VERSION ""

NS_ :

BS_:

BU_: TM

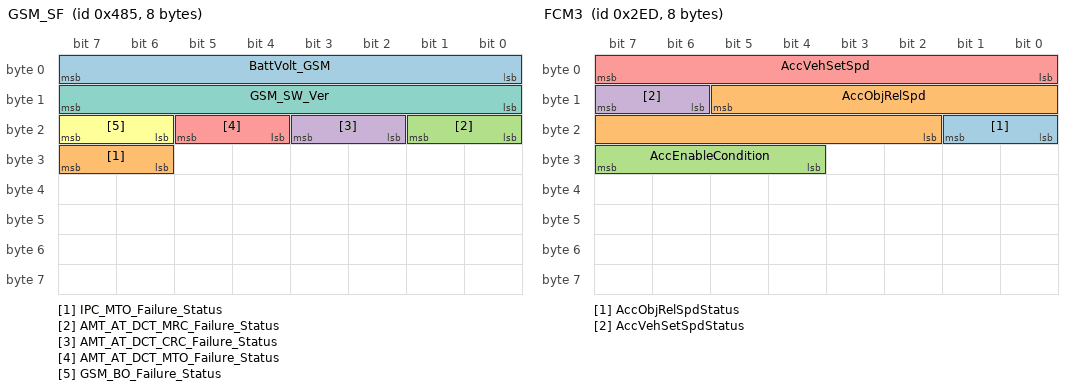
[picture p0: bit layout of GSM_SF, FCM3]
BO_ 1157 GSM_SF: 8 Vector__XXX
 SG_ BattVolt_GSM : 7|8@0+ (0.1,0) [0|25] ""  TM
 SG_ IPC_MTO_Failure_Status : 31|2@0+ (1,0) [0|3] ""  TM
 SG_ AMT_AT_DCT_MRC_Failure_Status : 17|2@0+ (1,0) [0|3] ""  TM
 SG_ AMT_AT_DCT_CRC_Failure_Status : 19|2@0+ (1,0) [0|3] ""  TM
 SG_ AMT_AT_DCT_MTO_Failure_Status : 21|2@0+ (1,0) [0|3] ""  TM
 SG_ GSM_BO_Failure_Status : 23|2@0+ (1,0) [0|3] ""  TM
 SG_ GSM_SW_Ver : 15|8@0+ (1,0) [0|255] ""  TM

BO_ 749 FCM3: 8 Vector__XXX
 SG_ AccObjRelSpdStatus : 17|2@0+ (1,0) [0|3] ""  TM
 SG_ AccObjRelSpd : 13|12@0+ (0.1,0) [0|409.5] ""  TM
 SG_ AccEnableCondition : 31|4@0+ (1,0) [0|15] ""  TM
 SG_ AccVehSetSpdStatus : 15|2@0+ (1,0) [0|3] ""  TM
 SG_ AccVehSetSpd : 7|8@0+ (1,0) [0|255] "kmph"  TM

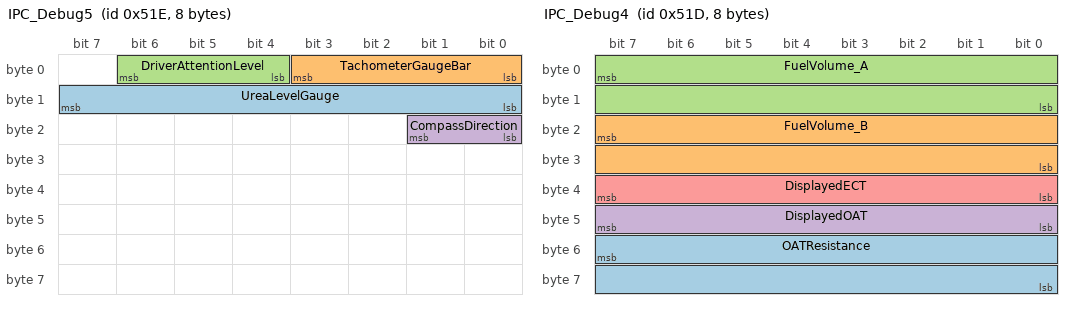
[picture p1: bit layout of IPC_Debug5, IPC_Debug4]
BO_ 1310 IPC_Debug5: 8 Vector__XXX
 SG_ UreaLevelGauge : 8|8@1+ (1,0) [0|100] "%"  TM
 SG_ TachometerGaugeBar : 3|4@0+ (1,0) [0|15] "NA"  TM
 SG_ DriverAttentionLevel : 6|3@0+ (1,0) [0|5] ""  TM
 SG_ CompassDirection : 17|2@0+ (1,0) [0|3] ""  TM

BO_ 1309 IPC_Debug4: 8 Vector__XXX
 SG_ OATResistance : 55|16@0+ (10,0) [0|655350] "Ohms"  TM
 SG_ FuelVolume_B : 23|16@0+ (0.1,0) [0|6553.5] "Litre"  TM
 SG_ FuelVolume_A : 7|16@0+ (0.1,0) [0|6553.5] "Litre"  TM
 SG_ DisplayedOAT : 47|8@0+ (1,0) [0|255] "C"  TM
 SG_ DisplayedECT : 39|8@0+ (1,0) [0|255] "C"  TM

BO_ 526 EMS_Event1: 8 Vector__XXX
 SG_ AccLkaSwitchState : 3|2@0+ (1,0) [0|3] ""  TM
 SG_ AdasSteeringSwitchState : 7|4@0+ (1,0) [0|15] ""  TM

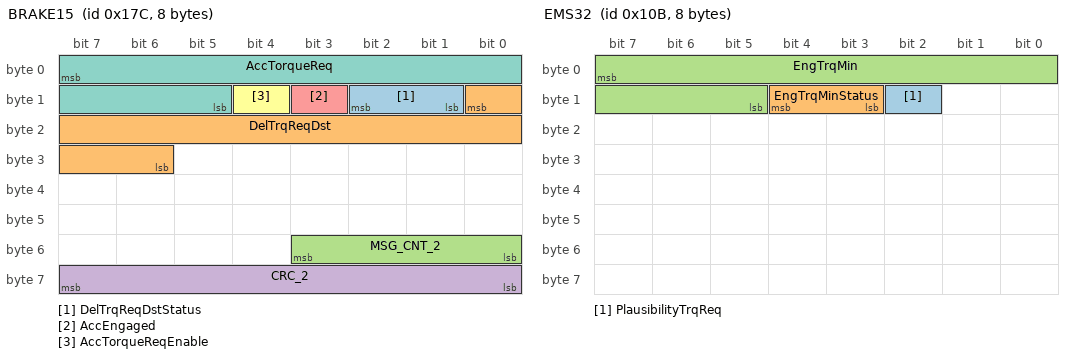
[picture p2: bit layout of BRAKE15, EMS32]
BO_ 380 BRAKE15: 8 Vector__XXX
 SG_ DelTrqReqDstStatus : 10|2@0+ (1,0) [0|3] ""  TM
 SG_ DelTrqReqDst : 8|11@0+ (0.01,-10) [-10|10] "Nm"  TM
 SG_ MSG_CNT_2 : 51|4@0+ (1,0) [0|15] ""  TM
 SG_ CRC_2 : 63|8@0+ (1,0) [0|255] ""  TM
 SG_ AccEngaged : 11|1@0+ (1,0) [0|1] ""  TM
 SG_ AccTorqueReqEnable : 12|1@0+ (1,0) [0|1] ""  TM
 SG_ AccTorqueReq : 7|11@0+ (1,-500) [-500|1546] "Nm"  TM

BO_ 267 EMS32: 8 Vector__XXX
 SG_ PlausibilityTrqReq : 10|1@0+ (1,0) [0|1] ""  TM
 SG_ EngTrqMinStatus : 12|2@0+ (1,0) [0|3] ""  TM
 SG_ EngTrqMin : 7|11@0+ (1,-500) [-500|1546] "Nm"  TM

BO_ 864 BCM4_RC: 8 Vector__XXX
 SG_ BcmPotPowerTailgateState : 25|2@0+ (1,0) [0|3] ""  TM
 SG_ PotHeightAdjState : 28|3@0+ (1,0) [0|7] ""  TM
 SG_ PotSwRkeOnOffState : 30|1@0+ (1,0) [0|1] ""  TM
 SG_ PotGestOnOffState : 29|1@0+ (1,0) [0|1] ""  TM
 SG_ PotBuzzOnOffState : 31|1@0+ (1,0) [0|1] ""  TM
 SG_ PotFuncState : 16|1@0+ (1,0) [0|1] ""  TM
 SG_ BCmHuSunShadeStateStatus : 18|2@0+ (1,0) [0|3] ""  TM
 SG_ BCmHuSunShadeState : 21|3@0+ (1,0) [0|7] ""  TM
 SG_ BCmHuSunRoofStateStatus : 23|2@0+ (1,0) [0|3] ""  TM
 SG_ BCmHuSunRoofState : 10|3@0+ (1,0) [0|7] ""  TM
 SG_ BCmHuGotoEntryExitPosState : 11|1@0+ (1,0) [0|1] ""  TM
 SG_ DrvMemSeatFunState : 12|1@0+ (1,0) [0|1] ""  TM
 SG_ MemRecallCancelSeat : 13|1@0+ (1,0) [0|1] ""  TM
 SG_ MemoryPosStoreReqStatus : 4|2@0+ (1,0) [0|3] ""  TM
 SG_ MemoryPosStoreReq : 2|3@0+ (1,0) [0|7] ""  TM
 SG_ MemoryPosLoadReqStatus : 15|2@0+ (1,0) [0|3] ""  TM
 SG_ MemoryPosLoadReq : 7|3@0+ (1,0) [0|7] ""  TM

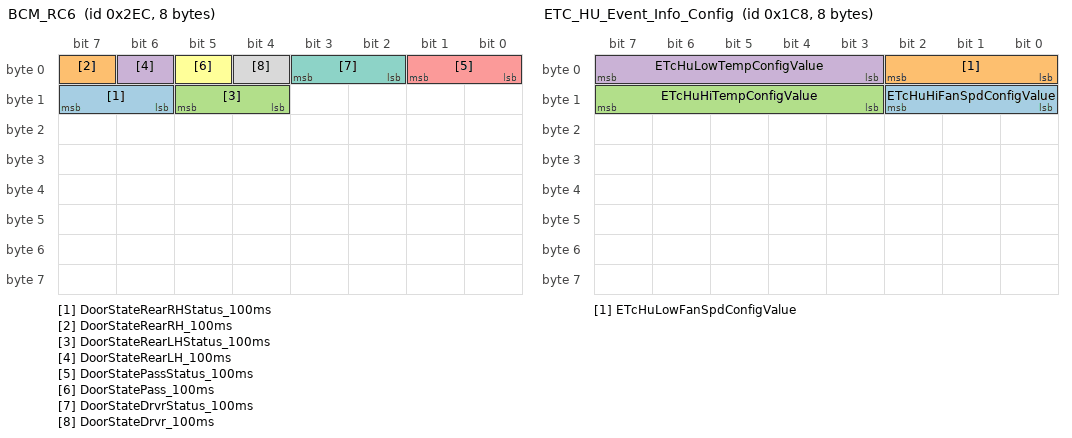
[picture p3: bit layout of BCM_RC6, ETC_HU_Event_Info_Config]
BO_ 748 BCM_RC6: 8 Vector__XXX
 SG_ DoorStateRearRHStatus_100ms : 15|2@0+ (1,0) [0|3] ""  TM
 SG_ DoorStateRearRH_100ms : 7|1@0+ (1,0) [0|1] ""  TM
 SG_ DoorStateRearLHStatus_100ms : 13|2@0+ (1,0) [0|3] ""  TM
 SG_ DoorStateRearLH_100ms : 6|1@0+ (1,0) [0|1] ""  TM
 SG_ DoorStatePassStatus_100ms : 1|2@0+ (1,0) [0|3] ""  TM
 SG_ DoorStatePass_100ms : 5|1@0+ (1,0) [0|1] ""  TM
 SG_ DoorStateDrvrStatus_100ms : 3|2@0+ (1,0) [0|3] ""  TM
 SG_ DoorStateDrvr_100ms : 4|1@0+ (1,0) [0|1] ""  TM

BO_ 456 ETC_HU_Event_Info_Config: 8 Vector__XXX
 SG_ ETcHuHiFanSpdConfigValue : 10|3@0+ (1,0) [0|7] ""  TM
 SG_ ETcHuLowFanSpdConfigValue : 2|3@0+ (1,0) [0|7] ""  TM
 SG_ ETcHuHiTempConfigValue : 15|5@0+ (1,0) [0|31] ""  TM
 SG_ ETcHuLowTempConfigValue : 7|5@0+ (1,0) [0|31] ""  TM

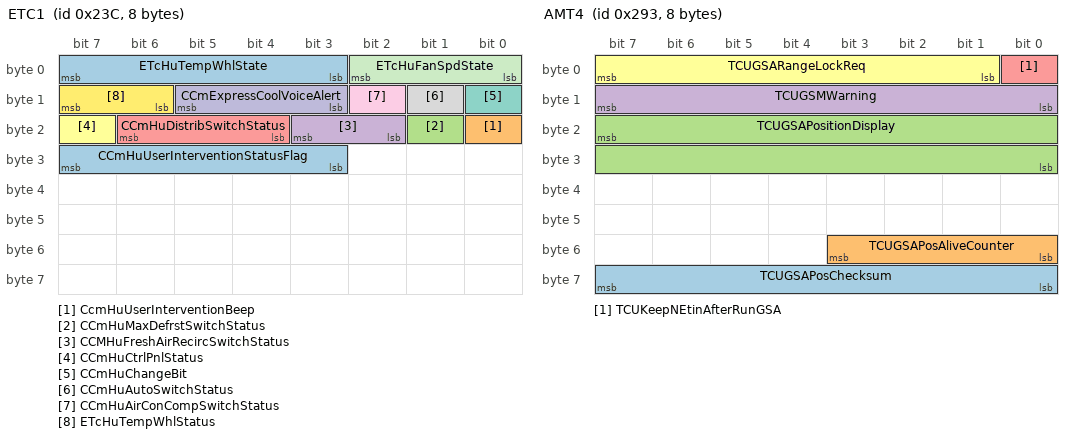
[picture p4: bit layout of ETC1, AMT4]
BO_ 572 ETC1: 8 Vector__XXX
 SG_ CCmHuUserInterventionStatusFlag : 31|5@0+ (1,0) [0|31] ""  TM
 SG_ CcmHuUserInterventionBeep : 16|1@0+ (1,0) [0|1] ""  TM
 SG_ CCmHuMaxDefrstSwitchStatus : 17|1@0+ (1,0) [0|1] ""  TM
 SG_ CCMHuFreshAirRecircSwitchStatus : 19|2@0+ (1,0) [0|3] ""  TM
 SG_ CCmHuDistribSwitchStatus : 22|3@0+ (1,0) [0|7] ""  TM
 SG_ CCmHuCtrlPnlStatus : 23|1@0+ (1,0) [0|1] ""  TM
 SG_ CCmHuChangeBit : 8|1@0+ (1,0) [0|1] ""  TM
 SG_ CCmHuAutoSwitchStatus : 9|1@0+ (1,0) [0|1] ""  TM
 SG_ CCmHuAirConCompSwitchStatus : 10|1@0+ (1,0) [0|1] ""  TM
 SG_ CCmExpressCoolVoiceAlert : 13|3@0+ (1,0) [0|7] ""  TM
 SG_ ETcHuFanSpdState : 2|3@0+ (1,0) [0|7] ""  TM
 SG_ ETcHuTempWhlStatus : 15|2@0+ (1,0) [0|3] ""  TM
 SG_ ETcHuTempWhlState : 7|5@0+ (1,0) [0|31] ""  TM

BO_ 1292 ESCL_NMPDU: 8 Vector__XXX
 SG_ ESCL_NMPDU_USER_DATA_D4 : 55|8@0+ (1,0) [0|255] ""  TM
 SG_ ESCL_NMPDU_USER_DATA_D3 : 47|8@0+ (1,0) [0|255] ""  TM
 SG_ ESCL_NMPDU_USER_DATA_D2 : 39|8@0+ (1,0) [0|255] ""  TM
 SG_ ESCL_NMPDU_USER_DATA_D1 : 31|8@0+ (1,0) [0|255] ""  TM
 SG_ ESCL_NMPDU_SRC_ECU_ID : 7|8@0+ (1,0) [0|255] ""  TM
 SG_ CurrentState_ESCL : 16|1@0+ (1,0) [0|1] ""  TM
 SG_ ActiveWakeUp_ESCL : 12|1@0+ (1,0) [0|1] ""  TM
 SG_ Reserved79 : 20|1@0+ (1,0) [0|1] ""  TM
 SG_ Reserved78 : 21|1@0+ (1,0) [0|1] ""  TM
 SG_ Reserved77 : 22|1@0+ (1,0) [0|1] ""  TM
 SG_ Reserved76 : 23|1@0+ (1,0) [0|1] ""  TM
 SG_ Reserved75 : 9|1@0+ (1,0) [0|1] ""  TM
 SG_ Reserved74 : 10|1@0+ (1,0) [0|1] ""  TM
 SG_ Reserved73 : 13|1@0+ (1,0) [0|1] ""  TM
 SG_ Reserved72 : 15|1@0+ (1,0) [0|1] ""  TM
 SG_ RepeatMessageReq_ESCL : 8|1@0+ (1,0) [0|1] ""  TM
 SG_ PreviousState_ESCL : 19|3@0+ (1,0) [0|7] ""  TM
 SG_ PartialNetworkInformation_ESCL : 14|1@0+ (1,0) [0|1] ""  TM
 SG_ NMCoOrdSlpReady_ESCL : 11|1@0+ (1,0) [0|1] ""  TM
 SG_ ESCL_NMPDU_USER_DATA_D5 : 63|8@0+ (1,0) [0|255] ""  TM

BO_ 437 DctPepsAuthReq: 8 Vector__XXX
 SG_ DctPepsAuthReq : 7|64@0+ (1,0) [0|0] ""  TM

BO_ 659 AMT4: 8 Vector__XXX
 SG_ TCUGSAPosChecksum : 63|8@0+ (1,0) [0|255] ""  TM
 SG_ TCUGSAPosAliveCounter : 51|4@0+ (1,0) [0|15] ""  TM
 SG_ TCUGSAPositionDisplay : 23|16@0+ (1,0) [0|65535] ""  TM
 SG_ TCUGSMWarning : 15|8@0+ (1,0) [0|255] ""  TM
 SG_ TCUKeepNEtinAfterRunGSA : 0|1@0+ (1,0) [0|1] ""  TM
 SG_ TCUGSARangeLockReq : 7|7@0+ (1,0) [0|127] ""  TM

BO_ 1610 SRR_DiagResponse_UUDT: 8 Vector__XXX
 SG_ SRR_DiagResponse_UUDT : 7|64@0+ (1,0) [0|0] ""  TM

BO_ 1866 SRR_DiagResponse_USDT: 8 Vector__XXX
 SG_ SRR_DiagResponse_USDT : 7|64@0+ (1,0) [0|0] ""  TM

BO_ 1858 SRR_DiagRequest: 8 Vector__XXX
 SG_ SRR_DiagRequest : 7|64@0+ (1,0) [0|0] ""  TM

BO_ 1608 FR_DiagResponse_UUDT: 8 Vector__XXX
 SG_ FR_DiagResponse_UUDT : 7|64@0+ (1,0) [0|0] ""  TM

BO_ 1864 FR_DiagResponse_USDT: 8 Vector__XXX
 SG_ FR_DiagResponse_USDT : 7|64@0+ (1,0) [0|0] ""  TM

BO_ 1856 FR_DiagRequest: 8 Vector__XXX
 SG_ FR_DiagRequest : 7|64@0+ (1,0) [0|0] ""  TM

BO_ 1609 FCM_DiagResponse_UUDT: 8 Vector__XXX
 SG_ FCM_DiagResponse_UUDT : 7|64@0+ (1,0) [0|0] ""  TM

BO_ 1865 FCM_DiagResponse_USDT: 8 Vector__XXX
 SG_ FCM_DiagResponse_USDT : 7|64@0+ (1,0) [0|0] ""  TM

BO_ 1857 FCM_DiagRequest: 8 Vector__XXX
 SG_ FCM_DiagRequest : 7|64@0+ (1,0) [0|0] ""  TM

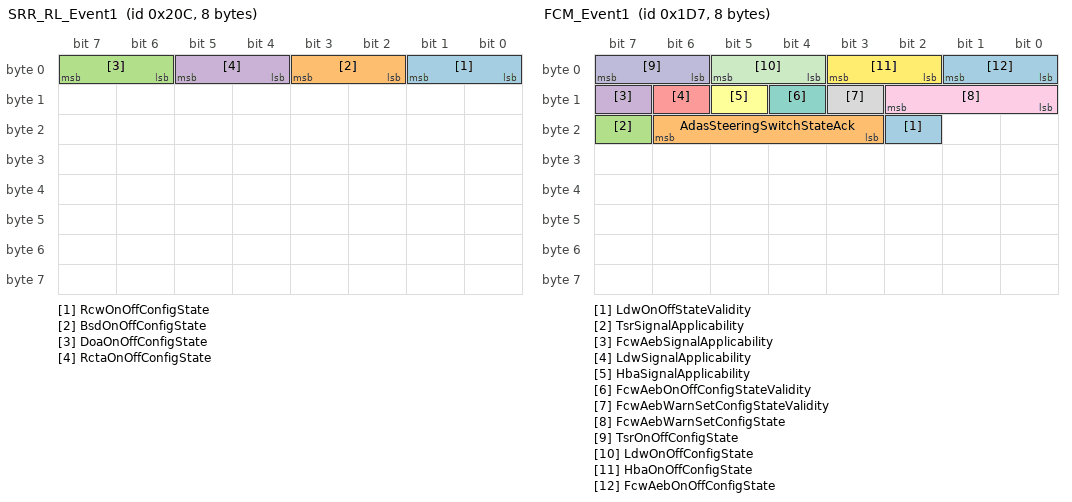
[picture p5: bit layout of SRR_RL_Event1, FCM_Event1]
BO_ 524 SRR_RL_Event1: 8 Vector__XXX
 SG_ RcwOnOffConfigState : 1|2@0+ (1,0) [0|3] ""  TM
 SG_ BsdOnOffConfigState : 3|2@0+ (1,0) [0|3] ""  TM
 SG_ DoaOnOffConfigState : 7|2@0+ (1,0) [0|3] ""  TM
 SG_ RctaOnOffConfigState : 5|2@0+ (1,0) [0|3] ""  TM

BO_ 593 SRR_RL1: 8 Vector__XXX
 SG_ RLRadarPresence : 26|1@0+ (1,0) [0|1] ""  TM
 SG_ RctaStates : 29|3@0+ (1,0) [0|7] ""  TM
 SG_ RctaOnOffState : 19|2@0+ (1,0) [0|3] ""  TM
 SG_ RctaIndRight : 31|2@0+ (1,0) [0|3] ""  TM
 SG_ RctaIndLeft : 17|2@0+ (1,0) [0|3] ""  TM
 SG_ RcwWarning : 25|2@0+ (1,0) [0|3] ""  TM
 SG_ RcwStates : 39|3@0+ (1,0) [0|7] ""  TM
 SG_ RcwOnOffState : 36|2@0+ (1,0) [0|3] ""  TM
 SG_ BsdStates : 22|3@0+ (1,0) [0|7] ""  TM
 SG_ BsdSoundRight : 23|1@0+ (1,0) [0|1] ""  TM
 SG_ BsdSoundLeft : 8|1@0+ (1,0) [0|1] ""  TM
 SG_ BsdOnOffState : 15|2@0+ (1,0) [0|3] ""  TM
 SG_ BsdIndStatus : 13|1@0+ (1,0) [0|1] ""  TM
 SG_ BsdIndRight : 10|2@0+ (1,0) [0|3] ""  TM
 SG_ BsdIndLeft : 12|2@0+ (1,0) [0|3] ""  TM
 SG_ DoaWarnRight : 3|2@0+ (1,0) [0|3] ""  TM
 SG_ DoaWarnLeft : 5|2@0+ (1,0) [0|3] ""  TM
 SG_ DoaStates : 1|2@0+ (1,0) [0|3] ""  TM
 SG_ DoaOnOffState : 7|2@0+ (1,0) [0|3] ""  TM

BO_ 1291 SRR_NMPDU: 8 Vector__XXX
 SG_ ActiveWakeUp_SRR : 12|1@0+ (1,0) [0|1] ""  TM
 SG_ CurrentState_SRR : 16|1@0+ (1,0) [0|1] ""  TM
 SG_ NMCoOrdSlpReady_SRR : 11|1@0+ (1,0) [0|1] ""  TM
 SG_ PartialNetworkInformation_SRR : 14|1@0+ (1,0) [0|1] ""  TM
 SG_ PreviousState_SRR : 19|3@0+ (1,0) [0|7] ""  TM
 SG_ RepeatMessageReq_SRR : 8|1@0+ (1,0) [0|1] ""  TM
 SG_ Reserved71 : 23|1@0+ (1,0) [0|1] ""  TM
 SG_ Reserved70 : 22|1@0+ (1,0) [0|1] ""  TM
 SG_ Reserved69 : 21|1@0+ (1,0) [0|1] ""  TM
 SG_ Reserved68 : 20|1@0+ (1,0) [0|1] ""  TM
 SG_ Reserved67 : 15|1@0+ (1,0) [0|1] ""  TM
 SG_ Reserved66 : 13|1@0+ (1,0) [0|1] ""  TM
 SG_ Reserved65 : 10|1@0+ (1,0) [0|1] ""  TM
 SG_ Reserved64 : 9|1@0+ (1,0) [0|1] ""  TM
 SG_ SRR_NMPDU_USER_DATA_D5 : 63|8@0+ (1,0) [0|255] ""  TM
 SG_ SRR_NMPDU_USER_DATA_D4 : 55|8@0+ (1,0) [0|255] ""  TM
 SG_ SRR_NMPDU_USER_DATA_D3 : 47|8@0+ (1,0) [0|255] ""  TM
 SG_ SRR_NMPDU_USER_DATA_D2 : 39|8@0+ (1,0) [0|255] ""  TM
 SG_ SRR_NMPDU_USER_DATA_D1 : 31|8@0+ (1,0) [0|255] ""  TM
 SG_ SRR_NMPDU_SRC_ECU_ID : 7|8@0+ (1,0) [0|255] ""  TM

BO_ 468 HU_Event2: 8 Vector__XXX
 SG_ PotSwRkeOnOffReq : 58|2@0+ (1,0) [0|3] ""  TM
 SG_ PotHeightAdjReq : 61|3@0+ (1,0) [0|7] ""  TM
 SG_ PotGestOnOffReq : 63|2@0+ (1,0) [0|3] ""  TM
 SG_ PotBuzzOnOffReq : 49|2@0+ (1,0) [0|3] ""  TM
 SG_ RcwReqType : 51|2@0+ (1,0) [0|3] ""  TM
 SG_ RcwOnOffStateReq : 53|2@0+ (1,0) [0|3] ""  TM
 SG_ RcwOnOffStateAck : 55|2@0+ (1,0) [0|3] ""  TM
 SG_ RctaReqType : 41|2@0+ (1,0) [0|3] ""  TM
 SG_ RctaOnOffStateReq : 43|2@0+ (1,0) [0|3] ""  TM
 SG_ RctaOnOffStateAck : 45|2@0+ (1,0) [0|3] ""  TM
 SG_ DoaReqType : 47|2@0+ (1,0) [0|3] ""  TM
 SG_ DoaOnOffStateReq : 33|2@0+ (1,0) [0|3] ""  TM
 SG_ DoaOnOffStateAck : 35|2@0+ (1,0) [0|3] ""  TM
 SG_ BsdReqType : 37|2@0+ (1,0) [0|3] ""  TM
 SG_ BsdOnOffStateReq : 39|2@0+ (1,0) [0|3] ""  TM
 SG_ BsdOnOffStateAck : 25|2@0+ (1,0) [0|3] ""  TM
 SG_ FcwAebWarnSetStateReq : 21|3@0+ (1,0) [0|7] ""  TM
 SG_ FcwAebWarnSetStateAck : 18|3@0+ (1,0) [0|7] ""  TM
 SG_ FcwAebReqType : 31|2@0+ (1,0) [0|3] ""  TM
 SG_ FcwAebOnOffStateReq : 23|2@0+ (1,0) [0|3] ""  TM
 SG_ FcwAebOnOffStateAck : 29|2@0+ (1,0) [0|3] ""  TM
 SG_ TsrReqType : 13|2@0+ (1,0) [0|3] ""  TM
 SG_ TsrOnOffStateReq : 9|2@0+ (1,0) [0|3] ""  TM
 SG_ TsrOnOffStateAck : 11|2@0+ (1,0) [0|3] ""  TM
 SG_ LdwOnOffStateReq : 15|2@0+ (1,0) [0|3] ""  TM
 SG_ LdwReqType : 27|2@0+ (1,0) [0|3] ""  TM
 SG_ LdwOnOffStateAck : 7|2@0+ (1,0) [0|3] ""  TM
 SG_ HbaOnOffStateReq : 5|2@0+ (1,0) [0|3] ""  TM
 SG_ HbaReqType : 3|2@0+ (1,0) [0|3] ""  TM
 SG_ HbaOnOffStateAck : 1|2@0+ (1,0) [0|3] ""  TM

BO_ 471 FCM_Event1: 8 Vector__XXX
 SG_ LdwOnOffStateValidity : 18|1@0+ (1,0) [0|1] ""  TM
 SG_ AdasSteeringSwitchStateAck : 22|4@0+ (1,0) [0|15] ""  TM
 SG_ TsrSignalApplicability : 23|1@0+ (1,0) [0|1] ""  TM
 SG_ FcwAebSignalApplicability : 15|1@0+ (1,0) [0|1] ""  TM
 SG_ LdwSignalApplicability : 14|1@0+ (1,0) [0|1] ""  TM
 SG_ HbaSignalApplicability : 13|1@0+ (1,0) [0|1] ""  TM
 SG_ FcwAebOnOffConfigStateValidity : 12|1@0+ (1,0) [0|1] ""  TM
 SG_ FcwAebWarnSetConfigStateValidity : 11|1@0+ (1,0) [0|1] ""  TM
 SG_ FcwAebWarnSetConfigState : 10|3@0+ (1,0) [0|7] ""  TM
 SG_ TsrOnOffConfigState : 7|2@0+ (1,0) [0|3] ""  TM
 SG_ LdwOnOffConfigState : 5|2@0+ (1,0) [0|3] ""  TM
 SG_ HbaOnOffConfigState : 3|2@0+ (1,0) [0|3] ""  TM
 SG_ FcwAebOnOffConfigState : 1|2@0+ (1,0) [0|3] ""  TM

BO_ 592 FCM1: 8 Vector__XXX
 SG_ AccInfoDisp : 44|3@0+ (1,0) [0|7] ""  TM
 SG_ AccWarnDisp : 41|2@0+ (1,0) [0|3] ""  TM
 SG_ AccSetDst : 55|3@0+ (1,0) [0|7] ""  TM
 SG_ AccObjValid : 52|1@0+ (1,0) [0|1] ""  TM
 SG_ AccObjDistStatus : 25|2@0+ (1,0) [0|3] ""  TM
 SG_ AccObjDist : 39|11@0+ (0.1,0) [0|204.7] "m"  TM
 SG_ TsrSysStates : 13|2@0+ (1,0) [0|3] ""  TM
 SG_ TsrDspSpd : 23|8@0+ (1,0) [0|255] ""  TM
 SG_ TsrDisNoPass : 15|2@0+ (1,0) [0|3] ""  TM
 SG_ LkaLnWrnStates : 1|2@0+ (1,0) [0|3] ""  TM
 SG_ LkaLdwLaneRecogn : 3|2@0+ (1,0) [0|3] ""  TM
 SG_ HbaStates : 11|2@0+ (1,0) [0|3] ""  TM
 SG_ TsrOnOffState : 7|2@0+ (1,0) [0|3] ""  TM
 SG_ HbaOnOffState : 9|2@0+ (1,0) [0|3] ""  TM
 SG_ LkaLdwSysStates : 31|3@0+ (1,0) [0|7] ""  TM
 SG_ LdwOnOffState : 5|2@0+ (1,0) [0|3] ""  TM
 SG_ FcmPresence : 28|1@0+ (1,0) [0|1] ""  TM

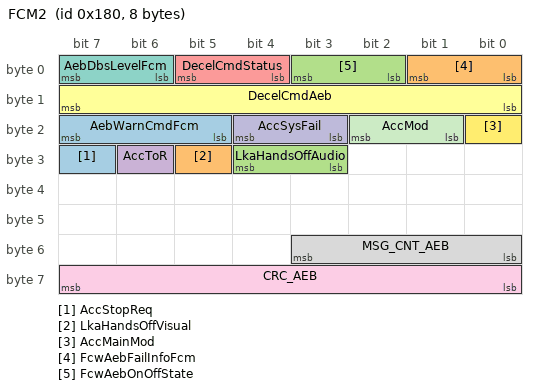
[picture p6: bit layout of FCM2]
BO_ 384 FCM2: 8 Vector__XXX
 SG_ AccStopReq : 31|1@0+ (1,0) [0|1] ""  TM
 SG_ LkaHandsOffVisual : 29|1@0+ (1,0) [0|1] ""  TM
 SG_ LkaHandsOffAudio : 28|2@0+ (1,0) [0|3] ""  TM
 SG_ AccToR : 30|1@0+ (1,0) [0|1] ""  TM
 SG_ DecelCmdStatus : 5|2@0+ (1,0) [0|3] ""  TM
 SG_ DecelCmdAeb : 15|8@0+ (0.01,0) [0|1] "g"  TM
 SG_ AebDbsLevelFcm : 7|2@0+ (1,0) [0|3] ""  TM
 SG_ MSG_CNT_AEB : 51|4@0+ (1,0) [0|15] ""  TM
 SG_ CRC_AEB : 63|8@0+ (1,0) [0|255] ""  TM
 SG_ AccSysFail : 20|2@0+ (1,0) [0|3] ""  TM
 SG_ AccMod : 18|2@0+ (1,0) [0|3] ""  TM
 SG_ AccMainMod : 16|1@0+ (1,0) [0|1] ""  TM
 SG_ AebWarnCmdFcm : 23|3@0+ (1,0) [0|7] ""  TM
 SG_ FcwAebFailInfoFcm : 1|2@0+ (1,0) [0|3] ""  TM
 SG_ FcwAebOnOffState : 3|2@0+ (1,0) [0|3] ""  TM

CM_ BU_ TM "Telematics Control Unit EV ECU

FN file name: 'TML_TM_FunctionNet_Matrix_V1.59'
FN column letter: 'B'
FN column Name: 'TM'";
CM_ BO_ 1157 "Supervision frame transmitted by GSM";
CM_ SG_ 1157 BattVolt_GSM "Battery voltage evaluated by GSM";
CM_ SG_ 1157 IPC_MTO_Failure_Status "Status of the IPC Message Timeout  failure detected as per Tata-IVN_Specification_Network_Management.";
CM_ SG_ 1157 AMT_AT_DCT_MRC_Failure_Status "Status of the message rolling counter failure";
CM_ SG_ 1157 AMT_AT_DCT_CRC_Failure_Status "Status of the cyclic reduntancy failure ";
CM_ SG_ 1157 AMT_AT_DCT_MTO_Failure_Status "Status of the AMT_AT_DCT Message Timeout  failure detected as per Tata-IVN_Specification_Network_Management.";
CM_ SG_ 1157 GSM_BO_Failure_Status "Status of the bus-off failure detected by GSM as per Tata-IVN_Specification_Network_Management.

";
CM_ SG_ 1157 GSM_SW_Ver "SW version of GSM
";
CM_ SG_ 749 AccObjRelSpdStatus "Status of Object distance";
CM_ SG_ 749 AccObjRelSpd "Object relative speed";
CM_ SG_ 749 AccEnableCondition "This signal tells whether ACC can be enabled by the driver or not";
CM_ SG_ 749 AccVehSetSpdStatus "Status of set vehicle speed";
CM_ SG_ 749 AccVehSetSpd "Set vehicle speed";
CM_ SG_ 1310 DriverAttentionLevel "AVH function availability indication";
CM_ SG_ 526 AccLkaSwitchState "It indicates the status of AdasSteeringSwitchState signal";
CM_ SG_ 526 AdasSteeringSwitchState "It indicates the State of Steering switch pressed by the user";
CM_ SG_ 380 DelTrqReqDstStatus "plausibility status signal of DelTrqReqDst";
CM_ SG_ 380 DelTrqReqDst "delta torque request";
CM_ SG_ 380 MSG_CNT_2 "Messgage counter for ACC torque signals";
CM_ SG_ 380 CRC_2 "CRC signal for ACC torque";
CM_ SG_ 380 AccEngaged "This indicates whether ACC is engaged or not";
CM_ SG_ 380 AccTorqueReqEnable "This signal indicates that ESP requests engine torque control for ACC. When the signal is set, EMS should not conduct fuel-cut off control unless it is required to prevent the damage of the engine and the related components.";
CM_ SG_ 380 AccTorqueReq "Effective flywheel torque requested by the BSM, either in case of TorqueIncrease or TorqueReduct.";
CM_ SG_ 267 PlausibilityTrqReq "This signal represents the feedback about validity of BSM intervention requests. This signal shall be set as soon as the ECM detects a communication fault (MC, CRC or SNA) on BSM received messages";
CM_ SG_ 267 EngTrqMinStatus "status information of EngTrqMin";
CM_ SG_ 267 EngTrqMin "This signal represents the minimum engine torque that the engine can deliver at gas pedal released";
CM_ SG_ 864 BcmPotPowerTailgateState "PowerTailgateStatus - Status of power boot/tailgate. Received from the POT ECU . This is published to PEPS ECU";
CM_ SG_ 864 PotHeightAdjState "Easy Entry/Exit function Enable or Disable current State to HU";
CM_ SG_ 864 PotSwRkeOnOffState "POT open/close by RKE switch enable/ disable user req state from BCM to HU";
CM_ SG_ 864 PotGestOnOffState "POT open/close by gesture enable/ disable user req state from BCM to HU";
CM_ SG_ 864 PotBuzzOnOffState "POT buzzer of open/close action enable/ disable user req state from BCM to HU";
CM_ SG_ 864 PotFuncState "This signal informs the whether POT function present or not in Vehicle";
CM_ SG_ 864 BCmHuSunShadeStateStatus "status of BCmHuSunShadeState";
CM_ SG_ 864 BCmHuSunShadeState "SunShade state from BCM to HU";
CM_ SG_ 864 BCmHuSunRoofStateStatus "status of BCmHuSunRoofState";
CM_ SG_ 864 BCmHuSunRoofState "Sunroof state from BCM to HU";
CM_ SG_ 864 BCmHuGotoEntryExitPosState "Easy Entry/Exit function Enable or Disable current State to HU";
CM_ SG_ 864 DrvMemSeatFunState "This signal informs the whether memory driver seat function present or not ";
CM_ SG_ 864 MemRecallCancelSeat "when the ongoing memory recall is cancelled due to any source (seat switch pack or any pre-condition)";
CM_ SG_ 864 MemoryPosStoreReqStatus "Status of Signal MemoryPosStoreReq";
CM_ SG_ 864 MemoryPosStoreReq "Memory save";
CM_ SG_ 864 MemoryPosLoadReqStatus "Status of Signal MemoryPosLoadReq";
CM_ SG_ 864 MemoryPosLoadReq "Seat Memory recall";
CM_ SG_ 748 DoorStateRearRHStatus_100ms "Rear right side door valid status



";
CM_ SG_ 748 DoorStateRearRH_100ms "Rear right side door switch state from BCM to FATC and IC";
CM_ SG_ 748 DoorStateRearLHStatus_100ms "Rear left side door valid Status





";
CM_ SG_ 748 DoorStateRearLH_100ms "Rear left side door switch state from BCM";
CM_ SG_ 748 DoorStatePassStatus_100ms "Driver Door Passenger valid Status";
CM_ SG_ 748 DoorStatePass_100ms "Co-Driver door switch state from BCM ";
CM_ SG_ 748 DoorStateDrvrStatus_100ms "DoorStateDrvr valid Status";
CM_ SG_ 748 DoorStateDrvr_100ms "Driver door switch state from BCM ";
CM_ SG_ 456 ETcHuHiFanSpdConfigValue "Indicates the higher configuration fan speed value for the ETC ECU under consideration";
CM_ SG_ 456 ETcHuLowFanSpdConfigValue "Indicates the lower configuration fan speed value for the ETC ECU under consideration";
CM_ SG_ 456 ETcHuHiTempConfigValue "Indicates the higher configuration temperature value for the ETC ECU under consideration";
CM_ SG_ 456 ETcHuLowTempConfigValue "Indicates the lower configuration temperature value for the ETC ECU under consideration";
CM_ SG_ 572 CCmHuUserInterventionStatusFlag "Indicates which HVAC control user has operated";
CM_ SG_ 572 CcmHuUserInterventionBeep "Audio Beep request for the user intervention on touched CCH panel.";
CM_ SG_ 572 CCmHuMaxDefrstSwitchStatus "Indicates whether the maximum defrost control is ON or OFF";
CM_ SG_ 572 CCMHuFreshAirRecircSwitchStatus "Indicates the different values of fresh air recirculation mode";
CM_ SG_ 572 CCmHuDistribSwitchStatus "Indicates the different distribution modes";
CM_ SG_ 572 CCmHuCtrlPnlStatus "Indicates whether the control panel is ON or OFF";
CM_ SG_ 572 CCmHuChangeBit "change bit";
CM_ SG_ 572 CCmHuAutoSwitchStatus "Indicates whether the Auto mode is ON or OFF";
CM_ SG_ 572 CCmHuAirConCompSwitchStatus "Indicates whether the AC is ON or OFF";
CM_ SG_ 572 CCmExpressCoolVoiceAlert "Indicates voice alert based on action needed for express cooling functionality";
CM_ SG_ 572 ETcHuFanSpdState "Indicates the Fan speed value in Levels";
CM_ SG_ 572 ETcHuTempWhlStatus "Indicates the status of the Set temperature value";
CM_ SG_ 572 ETcHuTempWhlState "Indicates the Set temperature value from ETC in Levels";
CM_ BO_ 437 "PEPS - DCT Immobilization DCT Immobilize to PEPS. Immobilization signals from DCT to PEPS while learning";
CM_ SG_ 437 DctPepsAuthReq "PEPS - DCT Immobilization

 DCT Immobilize to PEPS. Immobilization signals from DCT to PEPS while learning";
CM_ SG_ 659 TCUGSAPosChecksum "CRC for entire GSM Tx messages";
CM_ SG_ 659 TCUGSAPosAliveCounter "Rolling counter for the entire GSM Tx messages";
CM_ SG_ 659 TCUGSAPositionDisplay "Refer FN/FD for bit-mapped signals";
CM_ SG_ 659 TCUGSMWarning "Request from GSM for alerts/warnings. More then one bit to can be set in the signal. This is to request multiple messages.

This is bit-mapped signal. Please refer FD/Function net for value table";
CM_ SG_ 659 TCUGSARangeLockReq "Refer FN/FD for bit-mapped signals";
CM_ SG_ 524 RcwOnOffConfigState "It indicates the RCW  feature's On/Off State";
CM_ SG_ 524 BsdOnOffConfigState "It indicates the BSD feature's On/Off State";
CM_ SG_ 524 DoaOnOffConfigState "It indicates the DOA feature's On/Off State";
CM_ SG_ 524 RctaOnOffConfigState "It indicates the RCTA feature's On/Off State";
CM_ BO_ 593 "Supervision frame transmitted by SRS";
CM_ SG_ 593 RLRadarPresence "This signal indicates the presence of Rear Radar Module";
CM_ SG_ 593 RctaStates "This signal indicates the states of RCTA";
CM_ SG_ 593 RctaOnOffState "This signal indicates the presence of RCTA feature";
CM_ SG_ 593 RctaIndRight "This signal Indicates RCTA Warning Indicator mode for Right side.";
CM_ SG_ 593 RctaIndLeft "This signal Indicates RCTA Warning Indicator mode for Left side.";
CM_ SG_ 593 RcwWarning "Flag indicating activation of RCW warning (hazard light request)";
CM_ SG_ 593 RcwStates "RCW system status";
CM_ SG_ 593 RcwOnOffState "This signal indicates the presence of RCW feature";
CM_ SG_ 593 BsdStates "This signal indicates the status of BSD";
CM_ SG_ 593 BsdSoundRight "BSD-LCA Sound warning Right speaker";
CM_ SG_ 593 BsdSoundLeft "BSD-LCA Sound warning Left speaker";
CM_ SG_ 593 BsdOnOffState "This signal indicates the presence of BSD feature";
CM_ SG_ 593 BsdIndStatus "Mirror indicator failure signa";
CM_ SG_ 593 BsdIndRight "BSD right indicator warning";
CM_ SG_ 593 BsdIndLeft "BSD left indicator warning";
CM_ SG_ 593 DoaWarnRight "DOA Left indicator warning";
CM_ SG_ 593 DoaWarnLeft "DOA Left indicator warning";
CM_ SG_ 593 DoaStates "This signal indicates the states of DOA";
CM_ SG_ 593 DoaOnOffState "This signal indicates the presence of DOA feature";
CM_ SG_ 468 PotSwRkeOnOffReq "POT open/close by RKE switch enable/ disable user req";
CM_ SG_ 468 PotHeightAdjReq "POT height selection by user through HU";
CM_ SG_ 468 PotGestOnOffReq "POT open/close by gesture enable/ disable user req";
CM_ SG_ 468 PotBuzzOnOffReq "POT buzzer of open/close action enable/ disable user req";
CM_ SG_ 468 RcwReqType "This signal indicates the request for an action that IVI wants RearRadar to perform for RCW feature";
CM_ SG_ 468 RcwOnOffStateReq "It indicates the request made by the user for feature enable/disable";
CM_ SG_ 468 RcwOnOffStateAck "It indicates the acknowledgment status from IVI";
CM_ SG_ 468 RctaReqType "This signal indicates the request for an action that IVI wants RLRadar to perform for RCTA feature";
CM_ SG_ 468 RctaOnOffStateReq "It indicates the request made by the user for feature enable/disable";
CM_ SG_ 468 RctaOnOffStateAck "It indicates the acknowledgment status from IVI";
CM_ SG_ 468 DoaReqType "This signal indicates the request for an action that IVI wants RLRadar to perform for DOA feature";
CM_ SG_ 468 DoaOnOffStateReq "It indicates the request made by the user for feature enable/disable";
CM_ SG_ 468 DoaOnOffStateAck "It indicates the acknowledgment status from IVI";
CM_ SG_ 468 BsdReqType "This signal indicates the request for an action that IVI wants RearRadar to perform for BSD feature";
CM_ SG_ 468 BsdOnOffStateReq "It indicates the request made by the user for feature enable/disable";
CM_ SG_ 468 BsdOnOffStateAck "It indicates the acknowledgment status from IVI";
CM_ SG_ 468 FcwAebWarnSetStateReq "It indicates the request made by the user for feature sensitivity

";
CM_ SG_ 468 FcwAebWarnSetStateAck "It indicates the acknowledgment status from IVI for feature sensitivity
";
CM_ SG_ 468 FcwAebReqType "This signal indicates the request for an action that IVI wants FCM to perform for FCW AEB feature

";
CM_ SG_ 468 FcwAebOnOffStateReq "It indicates the request made by the user for feature enable/disable

";
CM_ SG_ 468 FcwAebOnOffStateAck "It indicates the acknowledgment status from IVI for feature ON/OFF
";
CM_ SG_ 468 TsrReqType "This signal indicates the request for an action that IVI wants FCM to perform for TSR feature

";
CM_ SG_ 468 TsrOnOffStateReq "It indicates the request made by the user for feature enable/disable

";
CM_ SG_ 468 TsrOnOffStateAck "It indicates the acknowledgment status from IVI

";
CM_ SG_ 468 LdwOnOffStateReq "It indicates the request made by the user for feature enable/disable

";
CM_ SG_ 468 LdwReqType "This signal indicates the request for an action that IVI wants FCM to perform for LDW feature
";
CM_ SG_ 468 LdwOnOffStateAck "It indicates the acknowledgment status from IVI
";
CM_ SG_ 468 HbaOnOffStateReq "It indicates the request made by the user for feature enable/disable
";
CM_ SG_ 468 HbaReqType "This signal indicates the request for an action that IVI wants FCM to perform for HBA feature";
CM_ SG_ 468 HbaOnOffStateAck "It indicates the acknowledgment status from IVI
";
CM_ SG_ 471 LdwOnOffStateValidity "This signal indicates whether the conditions for LKA feature activation are valid";
CM_ SG_ 471 AdasSteeringSwitchStateAck "It indicates Ack of Switch signal from ESP";
CM_ SG_ 471 TsrSignalApplicability "This signal describes the applicability of TSR Event signals";
CM_ SG_ 471 FcwAebSignalApplicability "This signal describes the applicability of FCW-AEB Event signals";
CM_ SG_ 471 LdwSignalApplicability "This signal describes the applicability of LDW Event signals";
CM_ SG_ 471 HbaSignalApplicability "This signal describes the applicability of HBA Event signals";
CM_ SG_ 471 FcwAebOnOffConfigStateValidity "It indicates the status of AEB feature's On/Off State signal";
CM_ SG_ 471 FcwAebWarnSetConfigStateValidity "It indicates the status of the sensitivity settings signal";
CM_ SG_ 471 FcwAebWarnSetConfigState "It indicates the sensitivity settings selected by the user";
CM_ SG_ 471 TsrOnOffConfigState "It indicates the TSR feature's On/Off State";
CM_ SG_ 471 LdwOnOffConfigState "It indicates the LDW feature's On/Off State";
CM_ SG_ 471 HbaOnOffConfigState "It indicates the HBA feature's On/Off State";
CM_ SG_ 471 FcwAebOnOffConfigState "It indicates the AEB feature's On/Off State";
CM_ SG_ 592 AccInfoDisp "ACC information display";
CM_ SG_ 592 AccWarnDisp "ACC warning display (ACC disengaged: Control Release. No ACC entry: Control Prohibition)";
CM_ SG_ 592 AccSetDst "ACC set distance by the driver's input";
CM_ SG_ 592 AccObjValid "object validity - This indicates whether a valid object is present in ego vehicle path or not";
CM_ SG_ 592 AccObjDistStatus "Status of Object distance";
CM_ SG_ 592 AccObjDist "Object distance";
CM_ SG_ 592 TsrSysStates "TSR (Traffic Sign Recognition) system operating state";
CM_ SG_ 592 TsrDspSpd "Speed limit sign Information for cluster display";
CM_ SG_ 592 TsrDisNoPass "No passing sign information for cluster display";
CM_ SG_ 592 LkaLnWrnStates "Lane Departure Warning to user";
CM_ SG_ 592 LkaLdwLaneRecogn "This signal indicates the recognized Lane by Camera module.";
CM_ SG_ 592 HbaStates "This signal indicates the HBA system states";
CM_ SG_ 592 TsrOnOffState "It indicates the TSR feature's On/Off State";
CM_ SG_ 592 HbaOnOffState "It indicates the HBA feature's On/Off State";
CM_ SG_ 592 LkaLdwSysStates "This signal indicates the LKA/LDW system status";
CM_ SG_ 592 LdwOnOffState "It indicates the LDW feature's On/Off State";
CM_ SG_ 592 FcmPresence "This signal indicates the presence of Front Camera Module";
CM_ SG_ 384 AccStopReq "STOP REQUEST";
CM_ SG_ 384 LkaHandsOffVisual "This signal indicates the visual warning to be given to the user for Steering Hands off";
CM_ SG_ 384 LkaHandsOffAudio "This signal indicates the audio warning to be given to the user for Steering Hands off";
CM_ SG_ 384 AccToR "ACC takeover request - This signal gives information to the driver that customer should take over the control of the system
CRC and MRC is required for this signal";
CM_ SG_ 384 DecelCmdStatus "It indicates the status of the deceleration request value signal.";
CM_ SG_ 384 DecelCmdAeb "DBS(Dynamic braking support ) helps to avoid collision by increasing the brake force when driver setup on the brake is  weak in collision risk situation.";
CM_ SG_ 384 AebDbsLevelFcm "DBS(Dynamic braking support ) helps to avoid collision by increasing the brake force when driver setup on the brake is  weak in collision risk situation.";
CM_ SG_ 384 MSG_CNT_AEB "Message counter for AEB feature";
CM_ SG_ 384 CRC_AEB "CRC signal for AEB feature";
CM_ SG_ 384 AccSysFail "ACC failure status";
CM_ SG_ 384 AccMod "Mode Indication for ACC function";
CM_ SG_ 384 AccMainMod "ACC main mode";
CM_ SG_ 384 AebWarnCmdFcm "AEB warning command (prefill, partial braking, full braking). CRC and MRC is required for this signal";
CM_ SG_ 384 FcwAebFailInfoFcm "The failure information of AEB.The failure information of AEB.";
CM_ SG_ 384 FcwAebOnOffState "It indicates the AEB feature's On/Off State";
BA_DEF_ SG_  "Remarks" STRING ;
BA_DEF_ SG_  "NWM_WakeupAllowed" ENUM  "No","Yes";
BA_DEF_ SG_  "GenSigTimeoutTime_HU_Mid_X451" INT 0 65535;
BA_DEF_ SG_  "GenSigTimeoutTime_HU_High_X451" INT 0 65535;
BA_DEF_ SG_  "GenSigTimeoutTime_HU_B" INT 0 65535;
BA_DEF_ SG_  "GenSigTimeoutTime_HU_A" INT 0 65535;
BA_DEF_ SG_  "GenSigTimeoutTime_BCM_Mid" INT 0 65535;
BA_DEF_ SG_  "GenSigTimeoutMsg_HU_Mid_X451" INT 0 65535;
BA_DEF_ SG_  "GenSigTimeoutMsg_HU_High_X451" INT 0 65535;
BA_DEF_ SG_  "GenSigTimeoutMsg_HU_B" INT 0 65535;
BA_DEF_ SG_  "GenSigTimeoutMsg_HU_A" INT 0 65535;
BA_DEF_ SG_  "GenSigStartValue" INT 0 0;
BA_DEF_ SG_  "GenSigSendType" ENUM  "Cyclic","OnWrite","OnWriteWithRepetition","OnChange","OnChangeWithRepetition","IfActive","IfActiveWithRepetition","NoSigSendType","NotUsed","NotUsed","NotUsed","NotUsed","NotUsed";
BA_DEF_ SG_  "GenSigInactiveValue" INT 0 0;
BA_DEF_ SG_  "GenSigEnvVarType" ENUM  "int","float","undef";
BA_DEF_ SG_  "GenSigCycleTimeActive" INT 0 0;
BA_DEF_ SG_  "GenSigCycleTime" INT 0 0;
BA_DEF_ SG_  "GenSigTimeoutMsg_HU_High_X445" INT 0 65535;
BA_DEF_ SG_  "GenSigTimeoutMsg_HU_Mid_X445" INT 0 65535;
BA_DEF_ SG_  "GenSigTimeoutTime_HU_High_X445" INT 0 65535;
BA_DEF_ SG_  "GenSigTimeoutTime_HU_Mid_X445" INT 0 65535;
BA_DEF_ SG_  "GenSigTimeoutMsg_IVI" INT 0 65535;
BA_DEF_ SG_  "GenSigTimeoutTime_IVI" INT 0 65535;
BA_DEF_ BO_  "NmMessage" ENUM  "no","yes";
BA_DEF_ BO_  "NmAsrMessage" ENUM  "<n.a.>","No","Yes";
BA_DEF_ BO_  "MessageTimeout" INT 0 65535;
BA_DEF_ BO_  "Me" INT 0 0;
BA_DEF_ BO_  "GenMsgStartDelayTime" INT 0 0;
BA_DEF_ BO_  "GenMsgSendType" ENUM  "Cyclic","NotUsed","NotUsed","NotUsed","NotUsed","NotUsed","NotUsed","IfActive","NoMsgSendType","NotUsed";
BA_DEF_ BO_  "GenMsgNrOfRepetition" INT 0 0;
BA_DEF_ BO_  "GenMsgILSupport" ENUM  "No","Yes";
BA_DEF_ BO_  "GenMsgDelayTime" INT 0 0;
BA_DEF_ BO_  "GenMsgCycleTimeFast" INT 0 0;
BA_DEF_ BO_  "GenMsgCycleTime" INT 0 0;
BA_DEF_ BO_  "DiagUudtResponse" ENUM  "false","true";
BA_DEF_ BO_  "DiagUsdtResponse" ENUM  "false","true";
BA_DEF_ BO_  "DiagState" ENUM  "No","Yes";
BA_DEF_ BO_  "DiagResponse" ENUM  "No","Yes";
BA_DEF_ BO_  "DiagRequest" ENUM  "No","Yes";
BA_DEF_ BO_  "MsgType" ENUM  "Application","NM","NMH";
BA_DEF_ BU_  "NodeLayerModules" STRING ;
BA_DEF_ BU_  "NmCAN" INT 1 3;
BA_DEF_ BU_  "NmAsrNodeIdentifier" HEX 0 255;
BA_DEF_ BU_  "NmAsrNode" ENUM  "<n.a.>","No","Yes";
BA_DEF_ BU_  "NmAsrCanMsgReducedTime" INT 1 65535;
BA_DEF_ BU_  "ECU" STRING ;
BA_DEF_  "NmType" STRING ;
BA_DEF_  "NmMessageCount" INT 0 128;
BA_DEF_  "NmAsrWaitBusSleepTime" INT 1 65535;
BA_DEF_  "NmAsrTimeoutTime" INT 1 65535;
BA_DEF_  "NmAsrRepeatMessageTime" INT 1 65535;
BA_DEF_  "NmAsrMessageCount" INT 128 128;
BA_DEF_  "NmAsrCanMsgCycleTime" INT 1 65535;
BA_DEF_  "NmAsrBaseAddress" HEX 0 2047;
BA_DEF_  "Manufacturer" STRING ;
BA_DEF_  "ILTxTimeout" INT 0 65535;
BA_DEF_  "GenEnvVarPrefix" STRING ;
BA_DEF_  "GenEnvVarEndingSnd" STRING ;
BA_DEF_  "GenEnvVarEndingDsp" STRING ;
BA_DEF_  "DBName" STRING ;
BA_DEF_  "BusType" STRING ;
BA_DEF_  "Baudrate" INT 0 1000000;
BA_DEF_ SG_  "SystemSignalLongSymbol" STRING ;
BA_DEF_DEF_  "Remarks" "null";
BA_DEF_DEF_  "NWM_WakeupAllowed" "No";
BA_DEF_DEF_  "GenSigTimeoutTime_HU_Mid_X451" 500;
BA_DEF_DEF_  "GenSigTimeoutTime_HU_High_X451" 500;
BA_DEF_DEF_  "GenSigTimeoutTime_HU_B" 500;
BA_DEF_DEF_  "GenSigTimeoutTime_HU_A" 500;
BA_DEF_DEF_  "GenSigTimeoutTime_BCM_Mid" 0;
BA_DEF_DEF_  "GenSigTimeoutMsg_HU_Mid_X451" 500;
BA_DEF_DEF_  "GenSigTimeoutMsg_HU_High_X451" 500;
BA_DEF_DEF_  "GenSigTimeoutMsg_HU_B" 500;
BA_DEF_DEF_  "GenSigTimeoutMsg_HU_A" 500;
BA_DEF_DEF_  "GenSigStartValue" 0;
BA_DEF_DEF_  "GenSigSendType" "Cyclic";
BA_DEF_DEF_  "GenSigInactiveValue" 0;
BA_DEF_DEF_  "GenSigEnvVarType" "undef";
BA_DEF_DEF_  "GenSigCycleTimeActive" 0;
BA_DEF_DEF_  "GenSigCycleTime" 0;
BA_DEF_DEF_  "GenSigTimeoutMsg_HU_High_X445" 500;
BA_DEF_DEF_  "GenSigTimeoutMsg_HU_Mid_X445" 500;
BA_DEF_DEF_  "GenSigTimeoutTime_HU_High_X445" 500;
BA_DEF_DEF_  "GenSigTimeoutTime_HU_Mid_X445" 500;
BA_DEF_DEF_  "GenSigTimeoutMsg_IVI" 500;
BA_DEF_DEF_  "GenSigTimeoutTime_IVI" 500;
BA_DEF_DEF_  "NmMessage" "no";
BA_DEF_DEF_  "NmAsrMessage" "<n.a.>";
BA_DEF_DEF_  "MessageTimeout" 500;
BA_DEF_DEF_  "Me" 0;
BA_DEF_DEF_  "GenMsgStartDelayTime" 0;
BA_DEF_DEF_  "GenMsgSendType" "Cyclic";
BA_DEF_DEF_  "GenMsgNrOfRepetition" 0;
BA_DEF_DEF_  "GenMsgILSupport" "Yes";
BA_DEF_DEF_  "GenMsgDelayTime" 0;
BA_DEF_DEF_  "GenMsgCycleTimeFast" 0;
BA_DEF_DEF_  "GenMsgCycleTime" 0;
BA_DEF_DEF_  "DiagUudtResponse" "false";
BA_DEF_DEF_  "DiagUsdtResponse" "false";
BA_DEF_DEF_  "DiagState" "No";
BA_DEF_DEF_  "DiagResponse" "No";
BA_DEF_DEF_  "DiagRequest" "No";
BA_DEF_DEF_  "MsgType" "Application";
BA_DEF_DEF_  "NodeLayerModules" "null";
BA_DEF_DEF_  "NmCAN" 3;
BA_DEF_DEF_  "NmAsrNodeIdentifier" 2;
BA_DEF_DEF_  "NmAsrNode" "<n.a.>";
BA_DEF_DEF_  "NmAsrCanMsgReducedTime" 50;
BA_DEF_DEF_  "ECU" "";
BA_DEF_DEF_  "NmType" "NmAsr";
BA_DEF_DEF_  "NmMessageCount" 128;
BA_DEF_DEF_  "NmAsrWaitBusSleepTime" 500;
BA_DEF_DEF_  "NmAsrTimeoutTime" 1000;
BA_DEF_DEF_  "NmAsrRepeatMessageTime" 1500;
BA_DEF_DEF_  "NmAsrMessageCount" 128;
BA_DEF_DEF_  "NmAsrCanMsgCycleTime" 200;
BA_DEF_DEF_  "NmAsrBaseAddress" 1280;
BA_DEF_DEF_  "Manufacturer" "TML";
BA_DEF_DEF_  "ILTxTimeout" 500;
BA_DEF_DEF_  "GenEnvVarPrefix" "Env";
BA_DEF_DEF_  "GenEnvVarEndingSnd" "_";
BA_DEF_DEF_  "GenEnvVarEndingDsp" "Dsp_";
BA_DEF_DEF_  "DBName" "null";
BA_DEF_DEF_  "BusType" "CAN";
BA_DEF_DEF_  "Baudrate" 500000;
BA_DEF_DEF_  "SystemSignalLongSymbol" "";
BA_ "NmMessageCount" 0;
BA_ "DBName" "CANBus_1";
BA_ "ECU" BU_ TM "TM";
BA_ "MessageTimeout" BO_ 1157 0;
BA_ "GenMsgCycleTime" BO_ 1157 100;
BA_ "GenMsgCycleTime" BO_ 749 100;
BA_ "GenMsgCycleTime" BO_ 1310 100;
BA_ "GenMsgCycleTime" BO_ 1309 100;
BA_ "MessageTimeout" BO_ 526 0;
BA_ "GenMsgSendType" BO_ 526 8;
BA_ "GenMsgNrOfRepetition" BO_ 526 3;
BA_ "GenMsgDelayTime" BO_ 526 40;
BA_ "GenMsgCycleTimeFast" BO_ 526 40;
BA_ "GenMsgCycleTime" BO_ 380 20;
BA_ "GenMsgStartDelayTime" BO_ 267 3;
BA_ "GenMsgCycleTime" BO_ 267 10;
BA_ "GenMsgCycleTime" BO_ 864 200;
BA_ "GenMsgCycleTime" BO_ 748 100;
BA_ "MessageTimeout" BO_ 456 0;
BA_ "GenMsgSendType" BO_ 456 8;
BA_ "GenMsgNrOfRepetition" BO_ 456 3;
BA_ "GenMsgCycleTime" BO_ 572 50;
BA_ "NmMessage" BO_ 1292 1;
BA_ "MessageTimeout" BO_ 1292 1000;
BA_ "GenMsgCycleTime" BO_ 1292 200;
BA_ "MsgType" BO_ 1292 1;
BA_ "MessageTimeout" BO_ 437 0;
BA_ "GenMsgSendType" BO_ 437 8;
BA_ "GenMsgNrOfRepetition" BO_ 437 3;
BA_ "GenMsgDelayTime" BO_ 437 100;
BA_ "GenMsgCycleTimeFast" BO_ 437 100;
BA_ "GenMsgStartDelayTime" BO_ 659 10;
BA_ "GenMsgCycleTime" BO_ 659 100;
BA_ "MessageTimeout" BO_ 1610 0;
BA_ "GenMsgSendType" BO_ 1610 8;
BA_ "GenMsgILSupport" BO_ 1610 0;
BA_ "DiagResponse" BO_ 1610 1;
BA_ "MessageTimeout" BO_ 1866 0;
BA_ "GenMsgSendType" BO_ 1866 8;
BA_ "GenMsgILSupport" BO_ 1866 0;
BA_ "DiagResponse" BO_ 1866 1;
BA_ "MessageTimeout" BO_ 1858 0;
BA_ "GenMsgSendType" BO_ 1858 8;
BA_ "GenMsgILSupport" BO_ 1858 0;
BA_ "DiagRequest" BO_ 1858 1;
BA_ "MessageTimeout" BO_ 1608 0;
BA_ "GenMsgSendType" BO_ 1608 8;
BA_ "GenMsgILSupport" BO_ 1608 0;
BA_ "DiagResponse" BO_ 1608 1;
BA_ "MessageTimeout" BO_ 1864 0;
BA_ "GenMsgSendType" BO_ 1864 8;
BA_ "GenMsgILSupport" BO_ 1864 0;
BA_ "DiagResponse" BO_ 1864 1;
BA_ "MessageTimeout" BO_ 1856 0;
BA_ "GenMsgSendType" BO_ 1856 8;
BA_ "GenMsgILSupport" BO_ 1856 0;
BA_ "DiagRequest" BO_ 1856 1;
BA_ "MessageTimeout" BO_ 1609 0;
BA_ "GenMsgSendType" BO_ 1609 8;
BA_ "GenMsgILSupport" BO_ 1609 0;
BA_ "DiagResponse" BO_ 1609 1;
BA_ "MessageTimeout" BO_ 1865 0;
BA_ "GenMsgSendType" BO_ 1865 8;
BA_ "GenMsgILSupport" BO_ 1865 0;
BA_ "DiagResponse" BO_ 1865 1;
BA_ "MessageTimeout" BO_ 1857 0;
BA_ "GenMsgSendType" BO_ 1857 8;
BA_ "GenMsgILSupport" BO_ 1857 0;
BA_ "DiagRequest" BO_ 1857 1;
BA_ "MessageTimeout" BO_ 524 0;
BA_ "GenMsgSendType" BO_ 524 8;
BA_ "GenMsgNrOfRepetition" BO_ 524 3;
BA_ "MessageTimeout" BO_ 593 0;
BA_ "GenMsgCycleTime" BO_ 593 100;
BA_ "MessageTimeout" BO_ 1291 1000;
BA_ "GenMsgCycleTime" BO_ 1291 200;
BA_ "MessageTimeout" BO_ 468 0;
BA_ "GenMsgSendType" BO_ 468 8;
BA_ "GenMsgNrOfRepetition" BO_ 468 3;
BA_ "GenMsgDelayTime" BO_ 468 200;
BA_ "GenMsgCycleTimeFast" BO_ 468 200;
BA_ "MessageTimeout" BO_ 471 0;
BA_ "GenMsgSendType" BO_ 471 8;
BA_ "GenMsgNrOfRepetition" BO_ 471 3;
BA_ "GenMsgDelayTime" BO_ 471 40;
BA_ "GenMsgCycleTimeFast" BO_ 471 40;
BA_ "GenMsgCycleTime" BO_ 592 100;
BA_ "GenMsgCycleTime" BO_ 384 20;
BA_ "GenSigTimeoutTime_HU_B" SG_ 1157 BattVolt_GSM 0;
BA_ "GenSigTimeoutTime_HU_A" SG_ 1157 BattVolt_GSM 0;
BA_ "GenSigTimeoutMsg_HU_B" SG_ 1157 BattVolt_GSM 0;
BA_ "GenSigTimeoutMsg_HU_A" SG_ 1157 BattVolt_GSM 0;
BA_ "GenSigSendType" SG_ 1157 BattVolt_GSM 7;
BA_ "GenSigCycleTimeActive" SG_ 1157 BattVolt_GSM 100;
BA_ "GenSigCycleTime" SG_ 1157 BattVolt_GSM 100;
BA_ "GenSigTimeoutTime_HU_B" SG_ 1157 IPC_MTO_Failure_Status 0;
BA_ "GenSigTimeoutTime_HU_A" SG_ 1157 IPC_MTO_Failure_Status 0;
BA_ "GenSigTimeoutMsg_HU_B" SG_ 1157 IPC_MTO_Failure_Status 0;
BA_ "GenSigTimeoutMsg_HU_A" SG_ 1157 IPC_MTO_Failure_Status 0;
BA_ "GenSigSendType" SG_ 1157 IPC_MTO_Failure_Status 7;
BA_ "GenSigCycleTimeActive" SG_ 1157 IPC_MTO_Failure_Status 100;
BA_ "GenSigCycleTime" SG_ 1157 IPC_MTO_Failure_Status 100;
BA_ "GenSigTimeoutTime_HU_B" SG_ 1157 AMT_AT_DCT_MRC_Failure_Status 0;
BA_ "GenSigTimeoutTime_HU_A" SG_ 1157 AMT_AT_DCT_MRC_Failure_Status 0;
BA_ "GenSigTimeoutMsg_HU_B" SG_ 1157 AMT_AT_DCT_MRC_Failure_Status 0;
BA_ "GenSigTimeoutMsg_HU_A" SG_ 1157 AMT_AT_DCT_MRC_Failure_Status 0;
BA_ "GenSigSendType" SG_ 1157 AMT_AT_DCT_MRC_Failure_Status 7;
BA_ "GenSigCycleTimeActive" SG_ 1157 AMT_AT_DCT_MRC_Failure_Status 100;
BA_ "GenSigCycleTime" SG_ 1157 AMT_AT_DCT_MRC_Failure_Status 100;
BA_ "GenSigTimeoutTime_HU_B" SG_ 1157 AMT_AT_DCT_CRC_Failure_Status 0;
BA_ "GenSigTimeoutTime_HU_A" SG_ 1157 AMT_AT_DCT_CRC_Failure_Status 0;
BA_ "GenSigTimeoutMsg_HU_B" SG_ 1157 AMT_AT_DCT_CRC_Failure_Status 0;
BA_ "GenSigTimeoutMsg_HU_A" SG_ 1157 AMT_AT_DCT_CRC_Failure_Status 0;
BA_ "GenSigSendType" SG_ 1157 AMT_AT_DCT_CRC_Failure_Status 7;
BA_ "GenSigCycleTimeActive" SG_ 1157 AMT_AT_DCT_CRC_Failure_Status 100;
BA_ "GenSigCycleTime" SG_ 1157 AMT_AT_DCT_CRC_Failure_Status 100;
BA_ "GenSigTimeoutTime_HU_B" SG_ 1157 AMT_AT_DCT_MTO_Failure_Status 0;
BA_ "GenSigTimeoutTime_HU_A" SG_ 1157 AMT_AT_DCT_MTO_Failure_Status 0;
BA_ "GenSigTimeoutMsg_HU_B" SG_ 1157 AMT_AT_DCT_MTO_Failure_Status 0;
BA_ "GenSigTimeoutMsg_HU_A" SG_ 1157 AMT_AT_DCT_MTO_Failure_Status 0;
BA_ "GenSigSendType" SG_ 1157 AMT_AT_DCT_MTO_Failure_Status 7;
BA_ "GenSigCycleTimeActive" SG_ 1157 AMT_AT_DCT_MTO_Failure_Status 100;
BA_ "GenSigCycleTime" SG_ 1157 AMT_AT_DCT_MTO_Failure_Status 100;
BA_ "GenSigTimeoutTime_HU_B" SG_ 1157 GSM_BO_Failure_Status 0;
BA_ "GenSigTimeoutTime_HU_A" SG_ 1157 GSM_BO_Failure_Status 0;
BA_ "GenSigTimeoutMsg_HU_B" SG_ 1157 GSM_BO_Failure_Status 0;
BA_ "GenSigTimeoutMsg_HU_A" SG_ 1157 GSM_BO_Failure_Status 0;
BA_ "GenSigSendType" SG_ 1157 GSM_BO_Failure_Status 7;
BA_ "GenSigCycleTimeActive" SG_ 1157 GSM_BO_Failure_Status 100;
BA_ "GenSigCycleTime" SG_ 1157 GSM_BO_Failure_Status 100;
BA_ "GenSigTimeoutTime_HU_B" SG_ 1157 GSM_SW_Ver 0;
BA_ "GenSigTimeoutTime_HU_A" SG_ 1157 GSM_SW_Ver 0;
BA_ "GenSigTimeoutMsg_HU_B" SG_ 1157 GSM_SW_Ver 0;
BA_ "GenSigTimeoutMsg_HU_A" SG_ 1157 GSM_SW_Ver 0;
BA_ "GenSigSendType" SG_ 1157 GSM_SW_Ver 7;
BA_ "GenSigCycleTimeActive" SG_ 1157 GSM_SW_Ver 100;
BA_ "GenSigCycleTime" SG_ 1157 GSM_SW_Ver 100;
BA_ "GenSigTimeoutTime_HU_B" SG_ 749 AccObjRelSpdStatus 0;
BA_ "GenSigTimeoutTime_HU_A" SG_ 749 AccObjRelSpdStatus 0;
BA_ "GenSigTimeoutMsg_HU_B" SG_ 749 AccObjRelSpdStatus 0;
BA_ "GenSigTimeoutMsg_HU_A" SG_ 749 AccObjRelSpdStatus 0;
BA_ "GenSigSendType" SG_ 749 AccObjRelSpdStatus 7;
BA_ "GenSigCycleTimeActive" SG_ 749 AccObjRelSpdStatus 100;
BA_ "GenSigCycleTime" SG_ 749 AccObjRelSpdStatus 100;
BA_ "GenSigTimeoutTime_HU_B" SG_ 749 AccObjRelSpd 0;
BA_ "GenSigTimeoutTime_HU_A" SG_ 749 AccObjRelSpd 0;
BA_ "GenSigTimeoutMsg_HU_B" SG_ 749 AccObjRelSpd 0;
BA_ "GenSigTimeoutMsg_HU_A" SG_ 749 AccObjRelSpd 0;
BA_ "GenSigSendType" SG_ 749 AccObjRelSpd 7;
BA_ "GenSigCycleTimeActive" SG_ 749 AccObjRelSpd 100;
BA_ "GenSigCycleTime" SG_ 749 AccObjRelSpd 100;
BA_ "GenSigTimeoutTime_HU_B" SG_ 749 AccEnableCondition 0;
BA_ "GenSigTimeoutTime_HU_A" SG_ 749 AccEnableCondition 0;
BA_ "GenSigTimeoutMsg_HU_B" SG_ 749 AccEnableCondition 0;
BA_ "GenSigTimeoutMsg_HU_A" SG_ 749 AccEnableCondition 0;
BA_ "GenSigSendType" SG_ 749 AccEnableCondition 7;
BA_ "GenSigCycleTimeActive" SG_ 749 AccEnableCondition 100;
BA_ "GenSigCycleTime" SG_ 749 AccEnableCondition 100;
BA_ "GenSigTimeoutTime_HU_B" SG_ 749 AccVehSetSpdStatus 0;
BA_ "GenSigTimeoutTime_HU_A" SG_ 749 AccVehSetSpdStatus 0;
BA_ "GenSigTimeoutMsg_HU_B" SG_ 749 AccVehSetSpdStatus 0;
BA_ "GenSigTimeoutMsg_HU_A" SG_ 749 AccVehSetSpdStatus 0;
BA_ "GenSigSendType" SG_ 749 AccVehSetSpdStatus 7;
BA_ "GenSigCycleTimeActive" SG_ 749 AccVehSetSpdStatus 100;
BA_ "GenSigCycleTime" SG_ 749 AccVehSetSpdStatus 100;
BA_ "GenSigTimeoutTime_HU_B" SG_ 749 AccVehSetSpd 0;
BA_ "GenSigTimeoutTime_HU_A" SG_ 749 AccVehSetSpd 0;
BA_ "GenSigTimeoutMsg_HU_B" SG_ 749 AccVehSetSpd 0;
BA_ "GenSigTimeoutMsg_HU_A" SG_ 749 AccVehSetSpd 0;
BA_ "GenSigSendType" SG_ 749 AccVehSetSpd 7;
BA_ "GenSigCycleTimeActive" SG_ 749 AccVehSetSpd 100;
BA_ "GenSigCycleTime" SG_ 749 AccVehSetSpd 100;
BA_ "GenSigSendType" SG_ 1310 DriverAttentionLevel 7;
BA_ "GenSigCycleTimeActive" SG_ 1310 DriverAttentionLevel 50;
BA_ "GenSigCycleTime" SG_ 1310 DriverAttentionLevel 50;
BA_ "Remarks" SG_ 526 AccLkaSwitchState "null*";
BA_ "GenSigTimeoutTime_HU_Mid_X451" SG_ 526 AccLkaSwitchState 0;
BA_ "GenSigTimeoutTime_HU_High_X451" SG_ 526 AccLkaSwitchState 0;
BA_ "GenSigTimeoutTime_HU_B" SG_ 526 AccLkaSwitchState 0;
BA_ "GenSigTimeoutTime_HU_A" SG_ 526 AccLkaSwitchState 0;
BA_ "GenSigTimeoutMsg_HU_Mid_X451" SG_ 526 AccLkaSwitchState 0;
BA_ "GenSigTimeoutMsg_HU_High_X451" SG_ 526 AccLkaSwitchState 0;
BA_ "GenSigTimeoutMsg_HU_B" SG_ 526 AccLkaSwitchState 0;
BA_ "GenSigTimeoutMsg_HU_A" SG_ 526 AccLkaSwitchState 0;
BA_ "GenSigSendType" SG_ 526 AccLkaSwitchState 2;
BA_ "GenSigTimeoutMsg_HU_High_X445" SG_ 526 AccLkaSwitchState 0;
BA_ "GenSigTimeoutMsg_HU_Mid_X445" SG_ 526 AccLkaSwitchState 0;
BA_ "GenSigTimeoutTime_HU_High_X445" SG_ 526 AccLkaSwitchState 0;
BA_ "GenSigTimeoutTime_HU_Mid_X445" SG_ 526 AccLkaSwitchState 0;
BA_ "GenSigTimeoutMsg_IVI" SG_ 526 AccLkaSwitchState 0;
BA_ "GenSigTimeoutTime_IVI" SG_ 526 AccLkaSwitchState 0;
BA_ "Remarks" SG_ 526 AdasSteeringSwitchState "null*";
BA_ "GenSigTimeoutTime_HU_Mid_X451" SG_ 526 AdasSteeringSwitchState 0;
BA_ "GenSigTimeoutTime_HU_High_X451" SG_ 526 AdasSteeringSwitchState 0;
BA_ "GenSigTimeoutTime_HU_B" SG_ 526 AdasSteeringSwitchState 0;
BA_ "GenSigTimeoutTime_HU_A" SG_ 526 AdasSteeringSwitchState 0;
BA_ "GenSigTimeoutMsg_HU_Mid_X451" SG_ 526 AdasSteeringSwitchState 0;
BA_ "GenSigTimeoutMsg_HU_High_X451" SG_ 526 AdasSteeringSwitchState 0;
BA_ "GenSigTimeoutMsg_HU_B" SG_ 526 AdasSteeringSwitchState 0;
BA_ "GenSigTimeoutMsg_HU_A" SG_ 526 AdasSteeringSwitchState 0;
BA_ "GenSigSendType" SG_ 526 AdasSteeringSwitchState 2;
BA_ "GenSigTimeoutMsg_HU_High_X445" SG_ 526 AdasSteeringSwitchState 0;
BA_ "GenSigTimeoutMsg_HU_Mid_X445" SG_ 526 AdasSteeringSwitchState 0;
BA_ "GenSigTimeoutTime_HU_High_X445" SG_ 526 AdasSteeringSwitchState 0;
BA_ "GenSigTimeoutTime_HU_Mid_X445" SG_ 526 AdasSteeringSwitchState 0;
BA_ "GenSigTimeoutMsg_IVI" SG_ 526 AdasSteeringSwitchState 0;
BA_ "GenSigTimeoutTime_IVI" SG_ 526 AdasSteeringSwitchState 0;
BA_ "GenSigSendType" SG_ 380 DelTrqReqDstStatus 7;
BA_ "GenSigCycleTimeActive" SG_ 380 DelTrqReqDstStatus 20;
BA_ "GenSigCycleTime" SG_ 380 DelTrqReqDstStatus 20;
BA_ "GenSigStartValue" SG_ 380 DelTrqReqDst 1000;
BA_ "GenSigSendType" SG_ 380 DelTrqReqDst 7;
BA_ "GenSigCycleTimeActive" SG_ 380 DelTrqReqDst 20;
BA_ "GenSigCycleTime" SG_ 380 DelTrqReqDst 20;
BA_ "GenSigSendType" SG_ 380 MSG_CNT_2 7;
BA_ "GenSigCycleTimeActive" SG_ 380 MSG_CNT_2 20;
BA_ "GenSigCycleTime" SG_ 380 MSG_CNT_2 20;
BA_ "GenSigSendType" SG_ 380 CRC_2 7;
BA_ "GenSigCycleTimeActive" SG_ 380 CRC_2 20;
BA_ "GenSigCycleTime" SG_ 380 CRC_2 20;
BA_ "GenSigSendType" SG_ 380 AccEngaged 7;
BA_ "GenSigCycleTimeActive" SG_ 380 AccEngaged 20;
BA_ "GenSigCycleTime" SG_ 380 AccEngaged 20;
BA_ "GenSigSendType" SG_ 380 AccTorqueReqEnable 7;
BA_ "GenSigCycleTimeActive" SG_ 380 AccTorqueReqEnable 20;
BA_ "GenSigCycleTime" SG_ 380 AccTorqueReqEnable 20;
BA_ "GenSigStartValue" SG_ 380 AccTorqueReq 500;
BA_ "GenSigSendType" SG_ 380 AccTorqueReq 7;
BA_ "GenSigCycleTimeActive" SG_ 380 AccTorqueReq 20;
BA_ "GenSigCycleTime" SG_ 380 AccTorqueReq 20;
BA_ "GenSigTimeoutTime_HU_Mid_X451" SG_ 267 PlausibilityTrqReq 0;
BA_ "GenSigTimeoutTime_HU_High_X451" SG_ 267 PlausibilityTrqReq 0;
BA_ "GenSigTimeoutTime_HU_B" SG_ 267 PlausibilityTrqReq 0;
BA_ "GenSigTimeoutTime_HU_A" SG_ 267 PlausibilityTrqReq 0;
BA_ "GenSigTimeoutMsg_HU_Mid_X451" SG_ 267 PlausibilityTrqReq 0;
BA_ "GenSigTimeoutMsg_HU_High_X451" SG_ 267 PlausibilityTrqReq 0;
BA_ "GenSigTimeoutMsg_HU_B" SG_ 267 PlausibilityTrqReq 0;
BA_ "GenSigTimeoutMsg_HU_A" SG_ 267 PlausibilityTrqReq 0;
BA_ "GenSigSendType" SG_ 267 PlausibilityTrqReq 7;
BA_ "GenSigCycleTimeActive" SG_ 267 PlausibilityTrqReq 10;
BA_ "GenSigCycleTime" SG_ 267 PlausibilityTrqReq 10;
BA_ "GenSigSendType" SG_ 267 EngTrqMinStatus 7;
BA_ "GenSigCycleTimeActive" SG_ 267 EngTrqMinStatus 10;
BA_ "GenSigCycleTime" SG_ 267 EngTrqMinStatus 10;
BA_ "GenSigStartValue" SG_ 267 EngTrqMin 500;
BA_ "GenSigSendType" SG_ 267 EngTrqMin 7;
BA_ "GenSigCycleTimeActive" SG_ 267 EngTrqMin 10;
BA_ "GenSigCycleTime" SG_ 267 EngTrqMin 10;
BA_ "GenSigTimeoutTime_HU_B" SG_ 864 BcmPotPowerTailgateState 0;
BA_ "GenSigTimeoutTime_HU_A" SG_ 864 BcmPotPowerTailgateState 0;
BA_ "GenSigTimeoutMsg_HU_B" SG_ 864 BcmPotPowerTailgateState 0;
BA_ "GenSigTimeoutMsg_HU_A" SG_ 864 BcmPotPowerTailgateState 0;
BA_ "GenSigSendType" SG_ 864 BcmPotPowerTailgateState 7;
BA_ "GenSigCycleTimeActive" SG_ 864 BcmPotPowerTailgateState 200;
BA_ "GenSigCycleTime" SG_ 864 BcmPotPowerTailgateState 200;
BA_ "GenSigTimeoutTime_HU_B" SG_ 864 PotHeightAdjState 0;
BA_ "GenSigTimeoutTime_HU_A" SG_ 864 PotHeightAdjState 0;
BA_ "GenSigTimeoutMsg_HU_B" SG_ 864 PotHeightAdjState 0;
BA_ "GenSigTimeoutMsg_HU_A" SG_ 864 PotHeightAdjState 0;
BA_ "GenSigSendType" SG_ 864 PotHeightAdjState 7;
BA_ "GenSigCycleTimeActive" SG_ 864 PotHeightAdjState 200;
BA_ "GenSigCycleTime" SG_ 864 PotHeightAdjState 200;
BA_ "GenSigTimeoutTime_HU_B" SG_ 864 PotSwRkeOnOffState 0;
BA_ "GenSigTimeoutTime_HU_A" SG_ 864 PotSwRkeOnOffState 0;
BA_ "GenSigTimeoutMsg_HU_B" SG_ 864 PotSwRkeOnOffState 0;
BA_ "GenSigTimeoutMsg_HU_A" SG_ 864 PotSwRkeOnOffState 0;
BA_ "GenSigSendType" SG_ 864 PotSwRkeOnOffState 7;
BA_ "GenSigCycleTimeActive" SG_ 864 PotSwRkeOnOffState 200;
BA_ "GenSigCycleTime" SG_ 864 PotSwRkeOnOffState 200;
BA_ "GenSigTimeoutTime_HU_B" SG_ 864 PotGestOnOffState 0;
BA_ "GenSigTimeoutTime_HU_A" SG_ 864 PotGestOnOffState 0;
BA_ "GenSigTimeoutMsg_HU_B" SG_ 864 PotGestOnOffState 0;
BA_ "GenSigTimeoutMsg_HU_A" SG_ 864 PotGestOnOffState 0;
BA_ "GenSigSendType" SG_ 864 PotGestOnOffState 7;
BA_ "GenSigCycleTimeActive" SG_ 864 PotGestOnOffState 200;
BA_ "GenSigCycleTime" SG_ 864 PotGestOnOffState 200;
BA_ "GenSigTimeoutTime_HU_Mid_X451" SG_ 864 PotBuzzOnOffState 0;
BA_ "GenSigTimeoutTime_HU_High_X451" SG_ 864 PotBuzzOnOffState 0;
BA_ "GenSigTimeoutTime_HU_B" SG_ 864 PotBuzzOnOffState 0;
BA_ "GenSigTimeoutTime_HU_A" SG_ 864 PotBuzzOnOffState 0;
BA_ "GenSigTimeoutMsg_HU_Mid_X451" SG_ 864 PotBuzzOnOffState 0;
BA_ "GenSigTimeoutMsg_HU_High_X451" SG_ 864 PotBuzzOnOffState 0;
BA_ "GenSigTimeoutMsg_HU_B" SG_ 864 PotBuzzOnOffState 0;
BA_ "GenSigTimeoutMsg_HU_A" SG_ 864 PotBuzzOnOffState 0;
BA_ "GenSigSendType" SG_ 864 PotBuzzOnOffState 2;
BA_ "GenSigTimeoutMsg_HU_High_X445" SG_ 864 PotBuzzOnOffState 0;
BA_ "GenSigTimeoutMsg_HU_Mid_X445" SG_ 864 PotBuzzOnOffState 0;
BA_ "GenSigTimeoutTime_HU_High_X445" SG_ 864 PotBuzzOnOffState 0;
BA_ "GenSigTimeoutTime_HU_Mid_X445" SG_ 864 PotBuzzOnOffState 0;
BA_ "GenSigTimeoutMsg_IVI" SG_ 864 PotBuzzOnOffState 0;
BA_ "GenSigTimeoutTime_IVI" SG_ 864 PotBuzzOnOffState 0;
BA_ "GenSigTimeoutTime_HU_Mid_X451" SG_ 864 PotFuncState 0;
BA_ "GenSigTimeoutTime_HU_High_X451" SG_ 864 PotFuncState 0;
BA_ "GenSigTimeoutTime_HU_B" SG_ 864 PotFuncState 0;
BA_ "GenSigTimeoutTime_HU_A" SG_ 864 PotFuncState 0;
BA_ "GenSigTimeoutMsg_HU_Mid_X451" SG_ 864 PotFuncState 0;
BA_ "GenSigTimeoutMsg_HU_High_X451" SG_ 864 PotFuncState 0;
BA_ "GenSigTimeoutMsg_HU_B" SG_ 864 PotFuncState 0;
BA_ "GenSigTimeoutMsg_HU_A" SG_ 864 PotFuncState 0;
BA_ "GenSigSendType" SG_ 864 PotFuncState 7;
BA_ "GenSigCycleTimeActive" SG_ 864 PotFuncState 200;
BA_ "GenSigCycleTime" SG_ 864 PotFuncState 200;
BA_ "GenSigTimeoutTime_HU_Mid_X451" SG_ 864 BCmHuSunShadeStateStatus 1000;
BA_ "GenSigTimeoutTime_HU_High_X451" SG_ 864 BCmHuSunShadeStateStatus 1000;
BA_ "GenSigTimeoutTime_HU_B" SG_ 864 BCmHuSunShadeStateStatus 1000;
BA_ "GenSigTimeoutTime_HU_A" SG_ 864 BCmHuSunShadeStateStatus 1000;
BA_ "GenSigTimeoutMsg_HU_Mid_X451" SG_ 864 BCmHuSunShadeStateStatus 1000;
BA_ "GenSigTimeoutMsg_HU_High_X451" SG_ 864 BCmHuSunShadeStateStatus 1000;
BA_ "GenSigTimeoutMsg_HU_B" SG_ 864 BCmHuSunShadeStateStatus 1000;
BA_ "GenSigTimeoutMsg_HU_A" SG_ 864 BCmHuSunShadeStateStatus 1000;
BA_ "GenSigSendType" SG_ 864 BCmHuSunShadeStateStatus 7;
BA_ "GenSigCycleTimeActive" SG_ 864 BCmHuSunShadeStateStatus 200;
BA_ "GenSigCycleTime" SG_ 864 BCmHuSunShadeStateStatus 200;
BA_ "GenSigTimeoutMsg_HU_High_X445" SG_ 864 BCmHuSunShadeStateStatus 1000;
BA_ "GenSigTimeoutMsg_HU_Mid_X445" SG_ 864 BCmHuSunShadeStateStatus 1000;
BA_ "GenSigTimeoutTime_HU_High_X445" SG_ 864 BCmHuSunShadeStateStatus 1000;
BA_ "GenSigTimeoutTime_HU_Mid_X445" SG_ 864 BCmHuSunShadeStateStatus 1000;
BA_ "GenSigTimeoutMsg_IVI" SG_ 864 BCmHuSunShadeStateStatus 1000;
BA_ "GenSigTimeoutTime_IVI" SG_ 864 BCmHuSunShadeStateStatus 1000;
BA_ "GenSigTimeoutTime_HU_Mid_X451" SG_ 864 BCmHuSunShadeState 1000;
BA_ "GenSigTimeoutTime_HU_High_X451" SG_ 864 BCmHuSunShadeState 1000;
BA_ "GenSigTimeoutTime_HU_B" SG_ 864 BCmHuSunShadeState 1000;
BA_ "GenSigTimeoutTime_HU_A" SG_ 864 BCmHuSunShadeState 1000;
BA_ "GenSigTimeoutMsg_HU_Mid_X451" SG_ 864 BCmHuSunShadeState 1000;
BA_ "GenSigTimeoutMsg_HU_High_X451" SG_ 864 BCmHuSunShadeState 1000;
BA_ "GenSigTimeoutMsg_HU_B" SG_ 864 BCmHuSunShadeState 1000;
BA_ "GenSigTimeoutMsg_HU_A" SG_ 864 BCmHuSunShadeState 1000;
BA_ "GenSigSendType" SG_ 864 BCmHuSunShadeState 7;
BA_ "GenSigCycleTimeActive" SG_ 864 BCmHuSunShadeState 200;
BA_ "GenSigCycleTime" SG_ 864 BCmHuSunShadeState 200;
BA_ "GenSigTimeoutMsg_HU_High_X445" SG_ 864 BCmHuSunShadeState 1000;
BA_ "GenSigTimeoutMsg_HU_Mid_X445" SG_ 864 BCmHuSunShadeState 1000;
BA_ "GenSigTimeoutTime_HU_High_X445" SG_ 864 BCmHuSunShadeState 1000;
BA_ "GenSigTimeoutTime_HU_Mid_X445" SG_ 864 BCmHuSunShadeState 1000;
BA_ "GenSigTimeoutMsg_IVI" SG_ 864 BCmHuSunShadeState 1000;
BA_ "GenSigTimeoutTime_IVI" SG_ 864 BCmHuSunShadeState 1000;
BA_ "GenSigTimeoutTime_HU_Mid_X451" SG_ 864 BCmHuSunRoofStateStatus 1000;
BA_ "GenSigTimeoutTime_HU_High_X451" SG_ 864 BCmHuSunRoofStateStatus 1000;
BA_ "GenSigTimeoutTime_HU_B" SG_ 864 BCmHuSunRoofStateStatus 1000;
BA_ "GenSigTimeoutTime_HU_A" SG_ 864 BCmHuSunRoofStateStatus 1000;
BA_ "GenSigTimeoutMsg_HU_Mid_X451" SG_ 864 BCmHuSunRoofStateStatus 1000;
BA_ "GenSigTimeoutMsg_HU_High_X451" SG_ 864 BCmHuSunRoofStateStatus 1000;
BA_ "GenSigTimeoutMsg_HU_B" SG_ 864 BCmHuSunRoofStateStatus 1000;
BA_ "GenSigTimeoutMsg_HU_A" SG_ 864 BCmHuSunRoofStateStatus 1000;
BA_ "GenSigSendType" SG_ 864 BCmHuSunRoofStateStatus 7;
BA_ "GenSigCycleTimeActive" SG_ 864 BCmHuSunRoofStateStatus 200;
BA_ "GenSigCycleTime" SG_ 864 BCmHuSunRoofStateStatus 200;
BA_ "GenSigTimeoutMsg_HU_High_X445" SG_ 864 BCmHuSunRoofStateStatus 1000;
BA_ "GenSigTimeoutMsg_HU_Mid_X445" SG_ 864 BCmHuSunRoofStateStatus 1000;
BA_ "GenSigTimeoutTime_HU_High_X445" SG_ 864 BCmHuSunRoofStateStatus 1000;
BA_ "GenSigTimeoutTime_HU_Mid_X445" SG_ 864 BCmHuSunRoofStateStatus 1000;
BA_ "GenSigTimeoutMsg_IVI" SG_ 864 BCmHuSunRoofStateStatus 1000;
BA_ "GenSigTimeoutTime_IVI" SG_ 864 BCmHuSunRoofStateStatus 1000;
BA_ "GenSigTimeoutTime_HU_Mid_X451" SG_ 864 BCmHuSunRoofState 1000;
BA_ "GenSigTimeoutTime_HU_High_X451" SG_ 864 BCmHuSunRoofState 1000;
BA_ "GenSigTimeoutTime_HU_B" SG_ 864 BCmHuSunRoofState 1000;
BA_ "GenSigTimeoutTime_HU_A" SG_ 864 BCmHuSunRoofState 1000;
BA_ "GenSigTimeoutMsg_HU_Mid_X451" SG_ 864 BCmHuSunRoofState 1000;
BA_ "GenSigTimeoutMsg_HU_High_X451" SG_ 864 BCmHuSunRoofState 1000;
BA_ "GenSigTimeoutMsg_HU_B" SG_ 864 BCmHuSunRoofState 1000;
BA_ "GenSigTimeoutMsg_HU_A" SG_ 864 BCmHuSunRoofState 1000;
BA_ "GenSigSendType" SG_ 864 BCmHuSunRoofState 7;
BA_ "GenSigCycleTimeActive" SG_ 864 BCmHuSunRoofState 200;
BA_ "GenSigCycleTime" SG_ 864 BCmHuSunRoofState 200;
BA_ "GenSigTimeoutMsg_HU_High_X445" SG_ 864 BCmHuSunRoofState 1000;
BA_ "GenSigTimeoutMsg_HU_Mid_X445" SG_ 864 BCmHuSunRoofState 1000;
BA_ "GenSigTimeoutTime_HU_High_X445" SG_ 864 BCmHuSunRoofState 1000;
BA_ "GenSigTimeoutTime_HU_Mid_X445" SG_ 864 BCmHuSunRoofState 1000;
BA_ "GenSigTimeoutMsg_IVI" SG_ 864 BCmHuSunRoofState 1000;
BA_ "GenSigTimeoutTime_IVI" SG_ 864 BCmHuSunRoofState 1000;
BA_ "GenSigTimeoutTime_HU_Mid_X451" SG_ 864 BCmHuGotoEntryExitPosState 1000;
BA_ "GenSigTimeoutTime_HU_High_X451" SG_ 864 BCmHuGotoEntryExitPosState 1000;
BA_ "GenSigTimeoutTime_HU_B" SG_ 864 BCmHuGotoEntryExitPosState 1000;
BA_ "GenSigTimeoutTime_HU_A" SG_ 864 BCmHuGotoEntryExitPosState 1000;
BA_ "GenSigTimeoutMsg_HU_Mid_X451" SG_ 864 BCmHuGotoEntryExitPosState 1000;
BA_ "GenSigTimeoutMsg_HU_High_X451" SG_ 864 BCmHuGotoEntryExitPosState 1000;
BA_ "GenSigTimeoutMsg_HU_B" SG_ 864 BCmHuGotoEntryExitPosState 1000;
BA_ "GenSigTimeoutMsg_HU_A" SG_ 864 BCmHuGotoEntryExitPosState 1000;
BA_ "GenSigSendType" SG_ 864 BCmHuGotoEntryExitPosState 7;
BA_ "GenSigCycleTimeActive" SG_ 864 BCmHuGotoEntryExitPosState 200;
BA_ "GenSigCycleTime" SG_ 864 BCmHuGotoEntryExitPosState 200;
BA_ "GenSigTimeoutMsg_HU_High_X445" SG_ 864 BCmHuGotoEntryExitPosState 1000;
BA_ "GenSigTimeoutMsg_HU_Mid_X445" SG_ 864 BCmHuGotoEntryExitPosState 1000;
BA_ "GenSigTimeoutTime_HU_High_X445" SG_ 864 BCmHuGotoEntryExitPosState 1000;
BA_ "GenSigTimeoutTime_HU_Mid_X445" SG_ 864 BCmHuGotoEntryExitPosState 1000;
BA_ "GenSigTimeoutMsg_IVI" SG_ 864 BCmHuGotoEntryExitPosState 1000;
BA_ "GenSigTimeoutTime_IVI" SG_ 864 BCmHuGotoEntryExitPosState 1000;
BA_ "GenSigTimeoutTime_HU_Mid_X451" SG_ 864 DrvMemSeatFunState 1000;
BA_ "GenSigTimeoutTime_HU_High_X451" SG_ 864 DrvMemSeatFunState 1000;
BA_ "GenSigTimeoutTime_HU_B" SG_ 864 DrvMemSeatFunState 1000;
BA_ "GenSigTimeoutTime_HU_A" SG_ 864 DrvMemSeatFunState 1000;
BA_ "GenSigTimeoutMsg_HU_Mid_X451" SG_ 864 DrvMemSeatFunState 1000;
BA_ "GenSigTimeoutMsg_HU_High_X451" SG_ 864 DrvMemSeatFunState 1000;
BA_ "GenSigTimeoutMsg_HU_B" SG_ 864 DrvMemSeatFunState 1000;
BA_ "GenSigTimeoutMsg_HU_A" SG_ 864 DrvMemSeatFunState 1000;
BA_ "GenSigSendType" SG_ 864 DrvMemSeatFunState 7;
BA_ "GenSigCycleTimeActive" SG_ 864 DrvMemSeatFunState 200;
BA_ "GenSigCycleTime" SG_ 864 DrvMemSeatFunState 200;
BA_ "GenSigTimeoutMsg_HU_High_X445" SG_ 864 DrvMemSeatFunState 1000;
BA_ "GenSigTimeoutMsg_HU_Mid_X445" SG_ 864 DrvMemSeatFunState 1000;
BA_ "GenSigTimeoutTime_HU_High_X445" SG_ 864 DrvMemSeatFunState 1000;
BA_ "GenSigTimeoutTime_HU_Mid_X445" SG_ 864 DrvMemSeatFunState 1000;
BA_ "GenSigTimeoutMsg_IVI" SG_ 864 DrvMemSeatFunState 1000;
BA_ "GenSigTimeoutTime_IVI" SG_ 864 DrvMemSeatFunState 1000;
BA_ "GenSigTimeoutTime_HU_Mid_X451" SG_ 864 MemRecallCancelSeat 1000;
BA_ "GenSigTimeoutTime_HU_High_X451" SG_ 864 MemRecallCancelSeat 1000;
BA_ "GenSigTimeoutTime_HU_B" SG_ 864 MemRecallCancelSeat 1000;
BA_ "GenSigTimeoutTime_HU_A" SG_ 864 MemRecallCancelSeat 1000;
BA_ "GenSigTimeoutMsg_HU_Mid_X451" SG_ 864 MemRecallCancelSeat 1000;
BA_ "GenSigTimeoutMsg_HU_High_X451" SG_ 864 MemRecallCancelSeat 1000;
BA_ "GenSigTimeoutMsg_HU_B" SG_ 864 MemRecallCancelSeat 1000;
BA_ "GenSigTimeoutMsg_HU_A" SG_ 864 MemRecallCancelSeat 1000;
BA_ "GenSigSendType" SG_ 864 MemRecallCancelSeat 7;
BA_ "GenSigCycleTimeActive" SG_ 864 MemRecallCancelSeat 200;
BA_ "GenSigCycleTime" SG_ 864 MemRecallCancelSeat 200;
BA_ "GenSigTimeoutMsg_HU_High_X445" SG_ 864 MemRecallCancelSeat 1000;
BA_ "GenSigTimeoutMsg_HU_Mid_X445" SG_ 864 MemRecallCancelSeat 1000;
BA_ "GenSigTimeoutTime_HU_High_X445" SG_ 864 MemRecallCancelSeat 1000;
BA_ "GenSigTimeoutTime_HU_Mid_X445" SG_ 864 MemRecallCancelSeat 1000;
BA_ "GenSigTimeoutMsg_IVI" SG_ 864 MemRecallCancelSeat 1000;
BA_ "GenSigTimeoutTime_IVI" SG_ 864 MemRecallCancelSeat 1000;
BA_ "GenSigTimeoutTime_HU_Mid_X451" SG_ 864 MemoryPosStoreReqStatus 1000;
BA_ "GenSigTimeoutTime_HU_High_X451" SG_ 864 MemoryPosStoreReqStatus 1000;
BA_ "GenSigTimeoutTime_HU_B" SG_ 864 MemoryPosStoreReqStatus 1000;
BA_ "GenSigTimeoutTime_HU_A" SG_ 864 MemoryPosStoreReqStatus 1000;
BA_ "GenSigTimeoutMsg_HU_Mid_X451" SG_ 864 MemoryPosStoreReqStatus 1000;
BA_ "GenSigTimeoutMsg_HU_High_X451" SG_ 864 MemoryPosStoreReqStatus 1000;
BA_ "GenSigTimeoutMsg_HU_B" SG_ 864 MemoryPosStoreReqStatus 1000;
BA_ "GenSigTimeoutMsg_HU_A" SG_ 864 MemoryPosStoreReqStatus 1000;
BA_ "GenSigSendType" SG_ 864 MemoryPosStoreReqStatus 7;
BA_ "GenSigCycleTimeActive" SG_ 864 MemoryPosStoreReqStatus 200;
BA_ "GenSigCycleTime" SG_ 864 MemoryPosStoreReqStatus 200;
BA_ "GenSigTimeoutMsg_HU_High_X445" SG_ 864 MemoryPosStoreReqStatus 1000;
BA_ "GenSigTimeoutMsg_HU_Mid_X445" SG_ 864 MemoryPosStoreReqStatus 1000;
BA_ "GenSigTimeoutTime_HU_High_X445" SG_ 864 MemoryPosStoreReqStatus 1000;
BA_ "GenSigTimeoutTime_HU_Mid_X445" SG_ 864 MemoryPosStoreReqStatus 1000;
BA_ "GenSigTimeoutMsg_IVI" SG_ 864 MemoryPosStoreReqStatus 1000;
BA_ "GenSigTimeoutTime_IVI" SG_ 864 MemoryPosStoreReqStatus 1000;
BA_ "GenSigTimeoutTime_HU_Mid_X451" SG_ 864 MemoryPosStoreReq 1000;
BA_ "GenSigTimeoutTime_HU_High_X451" SG_ 864 MemoryPosStoreReq 1000;
BA_ "GenSigTimeoutTime_HU_B" SG_ 864 MemoryPosStoreReq 1000;
BA_ "GenSigTimeoutTime_HU_A" SG_ 864 MemoryPosStoreReq 1000;
BA_ "GenSigTimeoutMsg_HU_Mid_X451" SG_ 864 MemoryPosStoreReq 1000;
BA_ "GenSigTimeoutMsg_HU_High_X451" SG_ 864 MemoryPosStoreReq 1000;
BA_ "GenSigTimeoutMsg_HU_B" SG_ 864 MemoryPosStoreReq 1000;
BA_ "GenSigTimeoutMsg_HU_A" SG_ 864 MemoryPosStoreReq 1000;
BA_ "GenSigSendType" SG_ 864 MemoryPosStoreReq 7;
BA_ "GenSigCycleTimeActive" SG_ 864 MemoryPosStoreReq 200;
BA_ "GenSigCycleTime" SG_ 864 MemoryPosStoreReq 200;
BA_ "GenSigTimeoutMsg_HU_High_X445" SG_ 864 MemoryPosStoreReq 1000;
BA_ "GenSigTimeoutMsg_HU_Mid_X445" SG_ 864 MemoryPosStoreReq 1000;
BA_ "GenSigTimeoutTime_HU_High_X445" SG_ 864 MemoryPosStoreReq 1000;
BA_ "GenSigTimeoutTime_HU_Mid_X445" SG_ 864 MemoryPosStoreReq 1000;
BA_ "GenSigTimeoutMsg_IVI" SG_ 864 MemoryPosStoreReq 1000;
BA_ "GenSigTimeoutTime_IVI" SG_ 864 MemoryPosStoreReq 1000;
BA_ "GenSigTimeoutTime_HU_Mid_X451" SG_ 864 MemoryPosLoadReqStatus 1000;
BA_ "GenSigTimeoutTime_HU_High_X451" SG_ 864 MemoryPosLoadReqStatus 1000;
BA_ "GenSigTimeoutTime_HU_B" SG_ 864 MemoryPosLoadReqStatus 1000;
BA_ "GenSigTimeoutTime_HU_A" SG_ 864 MemoryPosLoadReqStatus 1000;
BA_ "GenSigTimeoutMsg_HU_Mid_X451" SG_ 864 MemoryPosLoadReqStatus 1000;
BA_ "GenSigTimeoutMsg_HU_High_X451" SG_ 864 MemoryPosLoadReqStatus 1000;
BA_ "GenSigTimeoutMsg_HU_B" SG_ 864 MemoryPosLoadReqStatus 1000;
BA_ "GenSigTimeoutMsg_HU_A" SG_ 864 MemoryPosLoadReqStatus 1000;
BA_ "GenSigSendType" SG_ 864 MemoryPosLoadReqStatus 7;
BA_ "GenSigCycleTimeActive" SG_ 864 MemoryPosLoadReqStatus 200;
BA_ "GenSigCycleTime" SG_ 864 MemoryPosLoadReqStatus 200;
BA_ "GenSigTimeoutMsg_HU_High_X445" SG_ 864 MemoryPosLoadReqStatus 1000;
BA_ "GenSigTimeoutMsg_HU_Mid_X445" SG_ 864 MemoryPosLoadReqStatus 1000;
BA_ "GenSigTimeoutTime_HU_High_X445" SG_ 864 MemoryPosLoadReqStatus 1000;
BA_ "GenSigTimeoutTime_HU_Mid_X445" SG_ 864 MemoryPosLoadReqStatus 1000;
BA_ "GenSigTimeoutMsg_IVI" SG_ 864 MemoryPosLoadReqStatus 1000;
BA_ "GenSigTimeoutTime_IVI" SG_ 864 MemoryPosLoadReqStatus 1000;
BA_ "GenSigTimeoutTime_HU_Mid_X451" SG_ 864 MemoryPosLoadReq 1000;
BA_ "GenSigTimeoutTime_HU_High_X451" SG_ 864 MemoryPosLoadReq 1000;
BA_ "GenSigTimeoutTime_HU_B" SG_ 864 MemoryPosLoadReq 1000;
BA_ "GenSigTimeoutTime_HU_A" SG_ 864 MemoryPosLoadReq 1000;
BA_ "GenSigTimeoutMsg_HU_Mid_X451" SG_ 864 MemoryPosLoadReq 1000;
BA_ "GenSigTimeoutMsg_HU_High_X451" SG_ 864 MemoryPosLoadReq 1000;
BA_ "GenSigTimeoutMsg_HU_B" SG_ 864 MemoryPosLoadReq 1000;
BA_ "GenSigTimeoutMsg_HU_A" SG_ 864 MemoryPosLoadReq 1000;
BA_ "GenSigSendType" SG_ 864 MemoryPosLoadReq 7;
BA_ "GenSigCycleTimeActive" SG_ 864 MemoryPosLoadReq 200;
BA_ "GenSigCycleTime" SG_ 864 MemoryPosLoadReq 200;
BA_ "GenSigTimeoutMsg_HU_High_X445" SG_ 864 MemoryPosLoadReq 1000;
BA_ "GenSigTimeoutMsg_HU_Mid_X445" SG_ 864 MemoryPosLoadReq 1000;
BA_ "GenSigTimeoutTime_HU_High_X445" SG_ 864 MemoryPosLoadReq 1000;
BA_ "GenSigTimeoutTime_HU_Mid_X445" SG_ 864 MemoryPosLoadReq 1000;
BA_ "GenSigTimeoutMsg_IVI" SG_ 864 MemoryPosLoadReq 1000;
BA_ "GenSigTimeoutTime_IVI" SG_ 864 MemoryPosLoadReq 1000;
BA_ "Remarks" SG_ 748 DoorStateRearRHStatus_100ms "null*";
BA_ "GenSigSendType" SG_ 748 DoorStateRearRHStatus_100ms 7;
BA_ "GenSigCycleTimeActive" SG_ 748 DoorStateRearRHStatus_100ms 100;
BA_ "GenSigCycleTime" SG_ 748 DoorStateRearRHStatus_100ms 100;
BA_ "Remarks" SG_ 748 DoorStateRearRH_100ms "null*";
BA_ "GenSigSendType" SG_ 748 DoorStateRearRH_100ms 7;
BA_ "GenSigCycleTimeActive" SG_ 748 DoorStateRearRH_100ms 100;
BA_ "GenSigCycleTime" SG_ 748 DoorStateRearRH_100ms 100;
BA_ "Remarks" SG_ 748 DoorStateRearLHStatus_100ms "null*";
BA_ "GenSigSendType" SG_ 748 DoorStateRearLHStatus_100ms 7;
BA_ "GenSigCycleTimeActive" SG_ 748 DoorStateRearLHStatus_100ms 100;
BA_ "GenSigCycleTime" SG_ 748 DoorStateRearLHStatus_100ms 100;
BA_ "Remarks" SG_ 748 DoorStateRearLH_100ms "null*";
BA_ "GenSigSendType" SG_ 748 DoorStateRearLH_100ms 7;
BA_ "GenSigCycleTimeActive" SG_ 748 DoorStateRearLH_100ms 100;
BA_ "GenSigCycleTime" SG_ 748 DoorStateRearLH_100ms 100;
BA_ "Remarks" SG_ 748 DoorStatePassStatus_100ms "null*";
BA_ "GenSigSendType" SG_ 748 DoorStatePassStatus_100ms 7;
BA_ "GenSigCycleTimeActive" SG_ 748 DoorStatePassStatus_100ms 100;
BA_ "GenSigCycleTime" SG_ 748 DoorStatePassStatus_100ms 100;
BA_ "Remarks" SG_ 748 DoorStatePass_100ms "null*";
BA_ "GenSigSendType" SG_ 748 DoorStatePass_100ms 7;
BA_ "GenSigCycleTimeActive" SG_ 748 DoorStatePass_100ms 100;
BA_ "GenSigCycleTime" SG_ 748 DoorStatePass_100ms 100;
BA_ "Remarks" SG_ 748 DoorStateDrvrStatus_100ms "null*";
BA_ "GenSigSendType" SG_ 748 DoorStateDrvrStatus_100ms 7;
BA_ "GenSigCycleTimeActive" SG_ 748 DoorStateDrvrStatus_100ms 100;
BA_ "GenSigCycleTime" SG_ 748 DoorStateDrvrStatus_100ms 100;
BA_ "Remarks" SG_ 748 DoorStateDrvr_100ms "null*";
BA_ "GenSigSendType" SG_ 748 DoorStateDrvr_100ms 7;
BA_ "GenSigCycleTimeActive" SG_ 748 DoorStateDrvr_100ms 100;
BA_ "GenSigCycleTime" SG_ 748 DoorStateDrvr_100ms 100;
BA_ "Remarks" SG_ 456 ETcHuHiFanSpdConfigValue "null*";
BA_ "GenSigTimeoutTime_HU_Mid_X451" SG_ 456 ETcHuHiFanSpdConfigValue 0;
BA_ "GenSigTimeoutTime_HU_High_X451" SG_ 456 ETcHuHiFanSpdConfigValue 0;
BA_ "GenSigTimeoutTime_HU_B" SG_ 456 ETcHuHiFanSpdConfigValue 0;
BA_ "GenSigTimeoutTime_HU_A" SG_ 456 ETcHuHiFanSpdConfigValue 0;
BA_ "GenSigTimeoutMsg_HU_Mid_X451" SG_ 456 ETcHuHiFanSpdConfigValue 0;
BA_ "GenSigTimeoutMsg_HU_High_X451" SG_ 456 ETcHuHiFanSpdConfigValue 0;
BA_ "GenSigTimeoutMsg_HU_B" SG_ 456 ETcHuHiFanSpdConfigValue 0;
BA_ "GenSigTimeoutMsg_HU_A" SG_ 456 ETcHuHiFanSpdConfigValue 0;
BA_ "GenSigSendType" SG_ 456 ETcHuHiFanSpdConfigValue 1;
BA_ "GenSigTimeoutMsg_HU_High_X445" SG_ 456 ETcHuHiFanSpdConfigValue 0;
BA_ "GenSigTimeoutMsg_HU_Mid_X445" SG_ 456 ETcHuHiFanSpdConfigValue 0;
BA_ "GenSigTimeoutTime_HU_High_X445" SG_ 456 ETcHuHiFanSpdConfigValue 0;
BA_ "GenSigTimeoutTime_HU_Mid_X445" SG_ 456 ETcHuHiFanSpdConfigValue 0;
BA_ "GenSigTimeoutMsg_IVI" SG_ 456 ETcHuHiFanSpdConfigValue 0;
BA_ "GenSigTimeoutTime_IVI" SG_ 456 ETcHuHiFanSpdConfigValue 0;
BA_ "Remarks" SG_ 456 ETcHuLowFanSpdConfigValue "null*";
BA_ "GenSigTimeoutTime_HU_Mid_X451" SG_ 456 ETcHuLowFanSpdConfigValue 0;
BA_ "GenSigTimeoutTime_HU_High_X451" SG_ 456 ETcHuLowFanSpdConfigValue 0;
BA_ "GenSigTimeoutTime_HU_B" SG_ 456 ETcHuLowFanSpdConfigValue 0;
BA_ "GenSigTimeoutTime_HU_A" SG_ 456 ETcHuLowFanSpdConfigValue 0;
BA_ "GenSigTimeoutMsg_HU_Mid_X451" SG_ 456 ETcHuLowFanSpdConfigValue 0;
BA_ "GenSigTimeoutMsg_HU_High_X451" SG_ 456 ETcHuLowFanSpdConfigValue 0;
BA_ "GenSigTimeoutMsg_HU_B" SG_ 456 ETcHuLowFanSpdConfigValue 0;
BA_ "GenSigTimeoutMsg_HU_A" SG_ 456 ETcHuLowFanSpdConfigValue 0;
BA_ "GenSigSendType" SG_ 456 ETcHuLowFanSpdConfigValue 1;
BA_ "GenSigTimeoutMsg_HU_High_X445" SG_ 456 ETcHuLowFanSpdConfigValue 0;
BA_ "GenSigTimeoutMsg_HU_Mid_X445" SG_ 456 ETcHuLowFanSpdConfigValue 0;
BA_ "GenSigTimeoutTime_HU_High_X445" SG_ 456 ETcHuLowFanSpdConfigValue 0;
BA_ "GenSigTimeoutTime_HU_Mid_X445" SG_ 456 ETcHuLowFanSpdConfigValue 0;
BA_ "GenSigTimeoutMsg_IVI" SG_ 456 ETcHuLowFanSpdConfigValue 0;
BA_ "GenSigTimeoutTime_IVI" SG_ 456 ETcHuLowFanSpdConfigValue 0;
BA_ "Remarks" SG_ 456 ETcHuHiTempConfigValue "null*";
BA_ "GenSigTimeoutTime_HU_Mid_X451" SG_ 456 ETcHuHiTempConfigValue 0;
BA_ "GenSigTimeoutTime_HU_High_X451" SG_ 456 ETcHuHiTempConfigValue 0;
BA_ "GenSigTimeoutTime_HU_B" SG_ 456 ETcHuHiTempConfigValue 0;
BA_ "GenSigTimeoutTime_HU_A" SG_ 456 ETcHuHiTempConfigValue 0;
BA_ "GenSigTimeoutMsg_HU_Mid_X451" SG_ 456 ETcHuHiTempConfigValue 0;
BA_ "GenSigTimeoutMsg_HU_High_X451" SG_ 456 ETcHuHiTempConfigValue 0;
BA_ "GenSigTimeoutMsg_HU_B" SG_ 456 ETcHuHiTempConfigValue 0;
BA_ "GenSigTimeoutMsg_HU_A" SG_ 456 ETcHuHiTempConfigValue 0;
BA_ "GenSigSendType" SG_ 456 ETcHuHiTempConfigValue 1;
BA_ "GenSigTimeoutMsg_HU_High_X445" SG_ 456 ETcHuHiTempConfigValue 0;
BA_ "GenSigTimeoutMsg_HU_Mid_X445" SG_ 456 ETcHuHiTempConfigValue 0;
BA_ "GenSigTimeoutTime_HU_High_X445" SG_ 456 ETcHuHiTempConfigValue 0;
BA_ "GenSigTimeoutTime_HU_Mid_X445" SG_ 456 ETcHuHiTempConfigValue 0;
BA_ "GenSigTimeoutMsg_IVI" SG_ 456 ETcHuHiTempConfigValue 0;
BA_ "GenSigTimeoutTime_IVI" SG_ 456 ETcHuHiTempConfigValue 0;
BA_ "Remarks" SG_ 456 ETcHuLowTempConfigValue "null*";
BA_ "GenSigTimeoutTime_HU_Mid_X451" SG_ 456 ETcHuLowTempConfigValue 0;
BA_ "GenSigTimeoutTime_HU_High_X451" SG_ 456 ETcHuLowTempConfigValue 0;
BA_ "GenSigTimeoutTime_HU_B" SG_ 456 ETcHuLowTempConfigValue 0;
BA_ "GenSigTimeoutTime_HU_A" SG_ 456 ETcHuLowTempConfigValue 0;
BA_ "GenSigTimeoutMsg_HU_Mid_X451" SG_ 456 ETcHuLowTempConfigValue 0;
BA_ "GenSigTimeoutMsg_HU_High_X451" SG_ 456 ETcHuLowTempConfigValue 0;
BA_ "GenSigTimeoutMsg_HU_B" SG_ 456 ETcHuLowTempConfigValue 0;
BA_ "GenSigTimeoutMsg_HU_A" SG_ 456 ETcHuLowTempConfigValue 0;
BA_ "GenSigSendType" SG_ 456 ETcHuLowTempConfigValue 1;
BA_ "GenSigTimeoutMsg_HU_High_X445" SG_ 456 ETcHuLowTempConfigValue 0;
BA_ "GenSigTimeoutMsg_HU_Mid_X445" SG_ 456 ETcHuLowTempConfigValue 0;
BA_ "GenSigTimeoutTime_HU_High_X445" SG_ 456 ETcHuLowTempConfigValue 0;
BA_ "GenSigTimeoutTime_HU_Mid_X445" SG_ 456 ETcHuLowTempConfigValue 0;
BA_ "GenSigTimeoutMsg_IVI" SG_ 456 ETcHuLowTempConfigValue 0;
BA_ "GenSigTimeoutTime_IVI" SG_ 456 ETcHuLowTempConfigValue 0;
BA_ "GenSigSendType" SG_ 572 CCmHuUserInterventionStatusFlag 7;
BA_ "GenSigCycleTimeActive" SG_ 572 CCmHuUserInterventionStatusFlag 50;
BA_ "GenSigCycleTime" SG_ 572 CCmHuUserInterventionStatusFlag 50;
BA_ "GenSigSendType" SG_ 572 CcmHuUserInterventionBeep 7;
BA_ "GenSigCycleTimeActive" SG_ 572 CcmHuUserInterventionBeep 50;
BA_ "GenSigCycleTime" SG_ 572 CcmHuUserInterventionBeep 50;
BA_ "GenSigSendType" SG_ 572 CCmHuMaxDefrstSwitchStatus 7;
BA_ "GenSigCycleTimeActive" SG_ 572 CCmHuMaxDefrstSwitchStatus 50;
BA_ "GenSigCycleTime" SG_ 572 CCmHuMaxDefrstSwitchStatus 50;
BA_ "GenSigSendType" SG_ 572 CCMHuFreshAirRecircSwitchStatus 7;
BA_ "GenSigCycleTimeActive" SG_ 572 CCMHuFreshAirRecircSwitchStatus 50;
BA_ "GenSigCycleTime" SG_ 572 CCMHuFreshAirRecircSwitchStatus 50;
BA_ "GenSigSendType" SG_ 572 CCmHuDistribSwitchStatus 7;
BA_ "GenSigCycleTimeActive" SG_ 572 CCmHuDistribSwitchStatus 50;
BA_ "GenSigCycleTime" SG_ 572 CCmHuDistribSwitchStatus 50;
BA_ "GenSigSendType" SG_ 572 CCmHuCtrlPnlStatus 7;
BA_ "GenSigCycleTimeActive" SG_ 572 CCmHuCtrlPnlStatus 50;
BA_ "GenSigCycleTime" SG_ 572 CCmHuCtrlPnlStatus 50;
BA_ "GenSigSendType" SG_ 572 CCmHuChangeBit 7;
BA_ "GenSigCycleTimeActive" SG_ 572 CCmHuChangeBit 50;
BA_ "GenSigCycleTime" SG_ 572 CCmHuChangeBit 50;
BA_ "GenSigSendType" SG_ 572 CCmHuAutoSwitchStatus 7;
BA_ "GenSigCycleTimeActive" SG_ 572 CCmHuAutoSwitchStatus 50;
BA_ "GenSigCycleTime" SG_ 572 CCmHuAutoSwitchStatus 50;
BA_ "GenSigSendType" SG_ 572 CCmHuAirConCompSwitchStatus 7;
BA_ "GenSigCycleTimeActive" SG_ 572 CCmHuAirConCompSwitchStatus 50;
BA_ "GenSigCycleTime" SG_ 572 CCmHuAirConCompSwitchStatus 50;
BA_ "GenSigSendType" SG_ 572 CCmExpressCoolVoiceAlert 7;
BA_ "GenSigCycleTimeActive" SG_ 572 CCmExpressCoolVoiceAlert 50;
BA_ "GenSigCycleTime" SG_ 572 CCmExpressCoolVoiceAlert 50;
BA_ "GenSigSendType" SG_ 572 ETcHuFanSpdState 7;
BA_ "GenSigCycleTimeActive" SG_ 572 ETcHuFanSpdState 50;
BA_ "GenSigCycleTime" SG_ 572 ETcHuFanSpdState 50;
BA_ "GenSigSendType" SG_ 572 ETcHuTempWhlStatus 7;
BA_ "GenSigCycleTimeActive" SG_ 572 ETcHuTempWhlStatus 50;
BA_ "GenSigCycleTime" SG_ 572 ETcHuTempWhlStatus 50;
BA_ "GenSigStartValue" SG_ 572 ETcHuTempWhlState 7;
BA_ "GenSigSendType" SG_ 572 ETcHuTempWhlState 7;
BA_ "GenSigCycleTimeActive" SG_ 572 ETcHuTempWhlState 50;
BA_ "GenSigCycleTime" SG_ 572 ETcHuTempWhlState 50;
BA_ "GenSigTimeoutTime_HU_Mid_X451" SG_ 1292 ESCL_NMPDU_USER_DATA_D4 0;
BA_ "GenSigTimeoutTime_HU_High_X451" SG_ 1292 ESCL_NMPDU_USER_DATA_D4 0;
BA_ "GenSigTimeoutTime_HU_B" SG_ 1292 ESCL_NMPDU_USER_DATA_D4 0;
BA_ "GenSigTimeoutTime_HU_A" SG_ 1292 ESCL_NMPDU_USER_DATA_D4 0;
BA_ "GenSigTimeoutMsg_HU_Mid_X451" SG_ 1292 ESCL_NMPDU_USER_DATA_D4 0;
BA_ "GenSigTimeoutMsg_HU_High_X451" SG_ 1292 ESCL_NMPDU_USER_DATA_D4 0;
BA_ "GenSigTimeoutMsg_HU_B" SG_ 1292 ESCL_NMPDU_USER_DATA_D4 0;
BA_ "GenSigTimeoutMsg_HU_A" SG_ 1292 ESCL_NMPDU_USER_DATA_D4 0;
BA_ "GenSigSendType" SG_ 1292 ESCL_NMPDU_USER_DATA_D4 7;
BA_ "GenSigCycleTimeActive" SG_ 1292 ESCL_NMPDU_USER_DATA_D4 200;
BA_ "GenSigCycleTime" SG_ 1292 ESCL_NMPDU_USER_DATA_D4 200;
BA_ "GenSigTimeoutTime_HU_Mid_X451" SG_ 1292 ESCL_NMPDU_USER_DATA_D3 0;
BA_ "GenSigTimeoutTime_HU_High_X451" SG_ 1292 ESCL_NMPDU_USER_DATA_D3 0;
BA_ "GenSigTimeoutTime_HU_B" SG_ 1292 ESCL_NMPDU_USER_DATA_D3 0;
BA_ "GenSigTimeoutTime_HU_A" SG_ 1292 ESCL_NMPDU_USER_DATA_D3 0;
BA_ "GenSigTimeoutMsg_HU_Mid_X451" SG_ 1292 ESCL_NMPDU_USER_DATA_D3 0;
BA_ "GenSigTimeoutMsg_HU_High_X451" SG_ 1292 ESCL_NMPDU_USER_DATA_D3 0;
BA_ "GenSigTimeoutMsg_HU_B" SG_ 1292 ESCL_NMPDU_USER_DATA_D3 0;
BA_ "GenSigTimeoutMsg_HU_A" SG_ 1292 ESCL_NMPDU_USER_DATA_D3 0;
BA_ "GenSigSendType" SG_ 1292 ESCL_NMPDU_USER_DATA_D3 7;
BA_ "GenSigCycleTimeActive" SG_ 1292 ESCL_NMPDU_USER_DATA_D3 200;
BA_ "GenSigCycleTime" SG_ 1292 ESCL_NMPDU_USER_DATA_D3 200;
BA_ "GenSigTimeoutTime_HU_Mid_X451" SG_ 1292 ESCL_NMPDU_USER_DATA_D2 0;
BA_ "GenSigTimeoutTime_HU_High_X451" SG_ 1292 ESCL_NMPDU_USER_DATA_D2 0;
BA_ "GenSigTimeoutTime_HU_B" SG_ 1292 ESCL_NMPDU_USER_DATA_D2 0;
BA_ "GenSigTimeoutTime_HU_A" SG_ 1292 ESCL_NMPDU_USER_DATA_D2 0;
BA_ "GenSigTimeoutMsg_HU_Mid_X451" SG_ 1292 ESCL_NMPDU_USER_DATA_D2 0;
BA_ "GenSigTimeoutMsg_HU_High_X451" SG_ 1292 ESCL_NMPDU_USER_DATA_D2 0;
BA_ "GenSigTimeoutMsg_HU_B" SG_ 1292 ESCL_NMPDU_USER_DATA_D2 0;
BA_ "GenSigTimeoutMsg_HU_A" SG_ 1292 ESCL_NMPDU_USER_DATA_D2 0;
BA_ "GenSigSendType" SG_ 1292 ESCL_NMPDU_USER_DATA_D2 7;
BA_ "GenSigCycleTimeActive" SG_ 1292 ESCL_NMPDU_USER_DATA_D2 200;
BA_ "GenSigCycleTime" SG_ 1292 ESCL_NMPDU_USER_DATA_D2 200;
BA_ "GenSigTimeoutTime_HU_Mid_X451" SG_ 1292 ESCL_NMPDU_USER_DATA_D1 0;
BA_ "GenSigTimeoutTime_HU_High_X451" SG_ 1292 ESCL_NMPDU_USER_DATA_D1 0;
BA_ "GenSigTimeoutTime_HU_B" SG_ 1292 ESCL_NMPDU_USER_DATA_D1 0;
BA_ "GenSigTimeoutTime_HU_A" SG_ 1292 ESCL_NMPDU_USER_DATA_D1 0;
BA_ "GenSigTimeoutMsg_HU_Mid_X451" SG_ 1292 ESCL_NMPDU_USER_DATA_D1 0;
BA_ "GenSigTimeoutMsg_HU_High_X451" SG_ 1292 ESCL_NMPDU_USER_DATA_D1 0;
BA_ "GenSigTimeoutMsg_HU_B" SG_ 1292 ESCL_NMPDU_USER_DATA_D1 0;
BA_ "GenSigTimeoutMsg_HU_A" SG_ 1292 ESCL_NMPDU_USER_DATA_D1 0;
BA_ "GenSigSendType" SG_ 1292 ESCL_NMPDU_USER_DATA_D1 7;
BA_ "GenSigCycleTimeActive" SG_ 1292 ESCL_NMPDU_USER_DATA_D1 200;
BA_ "GenSigCycleTime" SG_ 1292 ESCL_NMPDU_USER_DATA_D1 200;
BA_ "GenSigTimeoutTime_HU_Mid_X451" SG_ 1292 ESCL_NMPDU_SRC_ECU_ID 0;
BA_ "GenSigTimeoutTime_HU_High_X451" SG_ 1292 ESCL_NMPDU_SRC_ECU_ID 0;
BA_ "GenSigTimeoutTime_HU_B" SG_ 1292 ESCL_NMPDU_SRC_ECU_ID 0;
BA_ "GenSigTimeoutTime_HU_A" SG_ 1292 ESCL_NMPDU_SRC_ECU_ID 0;
BA_ "GenSigTimeoutMsg_HU_Mid_X451" SG_ 1292 ESCL_NMPDU_SRC_ECU_ID 0;
BA_ "GenSigTimeoutMsg_HU_High_X451" SG_ 1292 ESCL_NMPDU_SRC_ECU_ID 0;
BA_ "GenSigTimeoutMsg_HU_B" SG_ 1292 ESCL_NMPDU_SRC_ECU_ID 0;
BA_ "GenSigTimeoutMsg_HU_A" SG_ 1292 ESCL_NMPDU_SRC_ECU_ID 0;
BA_ "GenSigSendType" SG_ 1292 ESCL_NMPDU_SRC_ECU_ID 7;
BA_ "GenSigCycleTimeActive" SG_ 1292 ESCL_NMPDU_SRC_ECU_ID 200;
BA_ "GenSigCycleTime" SG_ 1292 ESCL_NMPDU_SRC_ECU_ID 200;
BA_ "GenSigTimeoutTime_HU_Mid_X451" SG_ 1292 CurrentState_ESCL 0;
BA_ "GenSigTimeoutTime_HU_High_X451" SG_ 1292 CurrentState_ESCL 0;
BA_ "GenSigTimeoutTime_HU_B" SG_ 1292 CurrentState_ESCL 0;
BA_ "GenSigTimeoutTime_HU_A" SG_ 1292 CurrentState_ESCL 0;
BA_ "GenSigTimeoutMsg_HU_Mid_X451" SG_ 1292 CurrentState_ESCL 0;
BA_ "GenSigTimeoutMsg_HU_High_X451" SG_ 1292 CurrentState_ESCL 0;
BA_ "GenSigTimeoutMsg_HU_B" SG_ 1292 CurrentState_ESCL 0;
BA_ "GenSigTimeoutMsg_HU_A" SG_ 1292 CurrentState_ESCL 0;
BA_ "GenSigSendType" SG_ 1292 CurrentState_ESCL 7;
BA_ "GenSigCycleTimeActive" SG_ 1292 CurrentState_ESCL 200;
BA_ "GenSigCycleTime" SG_ 1292 CurrentState_ESCL 200;
BA_ "GenSigTimeoutTime_HU_Mid_X451" SG_ 1292 ActiveWakeUp_ESCL 0;
BA_ "GenSigTimeoutTime_HU_High_X451" SG_ 1292 ActiveWakeUp_ESCL 0;
BA_ "GenSigTimeoutTime_HU_B" SG_ 1292 ActiveWakeUp_ESCL 0;
BA_ "GenSigTimeoutTime_HU_A" SG_ 1292 ActiveWakeUp_ESCL 0;
BA_ "GenSigTimeoutMsg_HU_Mid_X451" SG_ 1292 ActiveWakeUp_ESCL 0;
BA_ "GenSigTimeoutMsg_HU_High_X451" SG_ 1292 ActiveWakeUp_ESCL 0;
BA_ "GenSigTimeoutMsg_HU_B" SG_ 1292 ActiveWakeUp_ESCL 0;
BA_ "GenSigTimeoutMsg_HU_A" SG_ 1292 ActiveWakeUp_ESCL 0;
BA_ "GenSigSendType" SG_ 1292 ActiveWakeUp_ESCL 7;
BA_ "GenSigCycleTimeActive" SG_ 1292 ActiveWakeUp_ESCL 200;
BA_ "GenSigCycleTime" SG_ 1292 ActiveWakeUp_ESCL 200;
BA_ "GenSigTimeoutTime_HU_Mid_X451" SG_ 1292 Reserved79 0;
BA_ "GenSigTimeoutTime_HU_High_X451" SG_ 1292 Reserved79 0;
BA_ "GenSigTimeoutTime_HU_B" SG_ 1292 Reserved79 0;
BA_ "GenSigTimeoutTime_HU_A" SG_ 1292 Reserved79 0;
BA_ "GenSigTimeoutMsg_HU_Mid_X451" SG_ 1292 Reserved79 0;
BA_ "GenSigTimeoutMsg_HU_High_X451" SG_ 1292 Reserved79 0;
BA_ "GenSigTimeoutMsg_HU_B" SG_ 1292 Reserved79 0;
BA_ "GenSigTimeoutMsg_HU_A" SG_ 1292 Reserved79 0;
BA_ "GenSigSendType" SG_ 1292 Reserved79 7;
BA_ "GenSigCycleTimeActive" SG_ 1292 Reserved79 200;
BA_ "GenSigCycleTime" SG_ 1292 Reserved79 200;
BA_ "GenSigTimeoutTime_HU_Mid_X451" SG_ 1292 Reserved78 0;
BA_ "GenSigTimeoutTime_HU_High_X451" SG_ 1292 Reserved78 0;
BA_ "GenSigTimeoutTime_HU_B" SG_ 1292 Reserved78 0;
BA_ "GenSigTimeoutTime_HU_A" SG_ 1292 Reserved78 0;
BA_ "GenSigTimeoutMsg_HU_Mid_X451" SG_ 1292 Reserved78 0;
BA_ "GenSigTimeoutMsg_HU_High_X451" SG_ 1292 Reserved78 0;
BA_ "GenSigTimeoutMsg_HU_B" SG_ 1292 Reserved78 0;
BA_ "GenSigTimeoutMsg_HU_A" SG_ 1292 Reserved78 0;
BA_ "GenSigSendType" SG_ 1292 Reserved78 7;
BA_ "GenSigCycleTimeActive" SG_ 1292 Reserved78 200;
BA_ "GenSigCycleTime" SG_ 1292 Reserved78 200;
BA_ "GenSigTimeoutTime_HU_Mid_X451" SG_ 1292 Reserved77 0;
BA_ "GenSigTimeoutTime_HU_High_X451" SG_ 1292 Reserved77 0;
BA_ "GenSigTimeoutTime_HU_B" SG_ 1292 Reserved77 0;
BA_ "GenSigTimeoutTime_HU_A" SG_ 1292 Reserved77 0;
BA_ "GenSigTimeoutMsg_HU_Mid_X451" SG_ 1292 Reserved77 0;
BA_ "GenSigTimeoutMsg_HU_High_X451" SG_ 1292 Reserved77 0;
BA_ "GenSigTimeoutMsg_HU_B" SG_ 1292 Reserved77 0;
BA_ "GenSigTimeoutMsg_HU_A" SG_ 1292 Reserved77 0;
BA_ "GenSigSendType" SG_ 1292 Reserved77 7;
BA_ "GenSigCycleTimeActive" SG_ 1292 Reserved77 200;
BA_ "GenSigCycleTime" SG_ 1292 Reserved77 200;
BA_ "GenSigTimeoutTime_HU_Mid_X451" SG_ 1292 Reserved76 0;
BA_ "GenSigTimeoutTime_HU_High_X451" SG_ 1292 Reserved76 0;
BA_ "GenSigTimeoutTime_HU_B" SG_ 1292 Reserved76 0;
BA_ "GenSigTimeoutTime_HU_A" SG_ 1292 Reserved76 0;
BA_ "GenSigTimeoutMsg_HU_Mid_X451" SG_ 1292 Reserved76 0;
BA_ "GenSigTimeoutMsg_HU_High_X451" SG_ 1292 Reserved76 0;
BA_ "GenSigTimeoutMsg_HU_B" SG_ 1292 Reserved76 0;
BA_ "GenSigTimeoutMsg_HU_A" SG_ 1292 Reserved76 0;
BA_ "GenSigSendType" SG_ 1292 Reserved76 7;
BA_ "GenSigCycleTimeActive" SG_ 1292 Reserved76 200;
BA_ "GenSigCycleTime" SG_ 1292 Reserved76 200;
BA_ "GenSigTimeoutTime_HU_Mid_X451" SG_ 1292 Reserved75 0;
BA_ "GenSigTimeoutTime_HU_High_X451" SG_ 1292 Reserved75 0;
BA_ "GenSigTimeoutTime_HU_B" SG_ 1292 Reserved75 0;
BA_ "GenSigTimeoutTime_HU_A" SG_ 1292 Reserved75 0;
BA_ "GenSigTimeoutMsg_HU_Mid_X451" SG_ 1292 Reserved75 0;
BA_ "GenSigTimeoutMsg_HU_High_X451" SG_ 1292 Reserved75 0;
BA_ "GenSigTimeoutMsg_HU_B" SG_ 1292 Reserved75 0;
BA_ "GenSigTimeoutMsg_HU_A" SG_ 1292 Reserved75 0;
BA_ "GenSigSendType" SG_ 1292 Reserved75 7;
BA_ "GenSigCycleTimeActive" SG_ 1292 Reserved75 200;
BA_ "GenSigCycleTime" SG_ 1292 Reserved75 200;
BA_ "GenSigTimeoutTime_HU_Mid_X451" SG_ 1292 Reserved74 0;
BA_ "GenSigTimeoutTime_HU_High_X451" SG_ 1292 Reserved74 0;
BA_ "GenSigTimeoutTime_HU_B" SG_ 1292 Reserved74 0;
BA_ "GenSigTimeoutTime_HU_A" SG_ 1292 Reserved74 0;
BA_ "GenSigTimeoutMsg_HU_Mid_X451" SG_ 1292 Reserved74 0;
BA_ "GenSigTimeoutMsg_HU_High_X451" SG_ 1292 Reserved74 0;
BA_ "GenSigTimeoutMsg_HU_B" SG_ 1292 Reserved74 0;
BA_ "GenSigTimeoutMsg_HU_A" SG_ 1292 Reserved74 0;
BA_ "GenSigSendType" SG_ 1292 Reserved74 7;
BA_ "GenSigCycleTimeActive" SG_ 1292 Reserved74 200;
BA_ "GenSigCycleTime" SG_ 1292 Reserved74 200;
BA_ "GenSigTimeoutTime_HU_Mid_X451" SG_ 1292 Reserved73 0;
BA_ "GenSigTimeoutTime_HU_High_X451" SG_ 1292 Reserved73 0;
BA_ "GenSigTimeoutTime_HU_B" SG_ 1292 Reserved73 0;
BA_ "GenSigTimeoutTime_HU_A" SG_ 1292 Reserved73 0;
BA_ "GenSigTimeoutMsg_HU_Mid_X451" SG_ 1292 Reserved73 0;
BA_ "GenSigTimeoutMsg_HU_High_X451" SG_ 1292 Reserved73 0;
BA_ "GenSigTimeoutMsg_HU_B" SG_ 1292 Reserved73 0;
BA_ "GenSigTimeoutMsg_HU_A" SG_ 1292 Reserved73 0;
BA_ "GenSigSendType" SG_ 1292 Reserved73 7;
BA_ "GenSigCycleTimeActive" SG_ 1292 Reserved73 200;
BA_ "GenSigCycleTime" SG_ 1292 Reserved73 200;
BA_ "GenSigTimeoutTime_HU_Mid_X451" SG_ 1292 Reserved72 0;
BA_ "GenSigTimeoutTime_HU_High_X451" SG_ 1292 Reserved72 0;
BA_ "GenSigTimeoutTime_HU_B" SG_ 1292 Reserved72 0;
BA_ "GenSigTimeoutTime_HU_A" SG_ 1292 Reserved72 0;
BA_ "GenSigTimeoutMsg_HU_Mid_X451" SG_ 1292 Reserved72 0;
BA_ "GenSigTimeoutMsg_HU_High_X451" SG_ 1292 Reserved72 0;
BA_ "GenSigTimeoutMsg_HU_B" SG_ 1292 Reserved72 0;
BA_ "GenSigTimeoutMsg_HU_A" SG_ 1292 Reserved72 0;
BA_ "GenSigSendType" SG_ 1292 Reserved72 7;
BA_ "GenSigCycleTimeActive" SG_ 1292 Reserved72 200;
BA_ "GenSigCycleTime" SG_ 1292 Reserved72 200;
BA_ "GenSigTimeoutTime_HU_Mid_X451" SG_ 1292 RepeatMessageReq_ESCL 0;
BA_ "GenSigTimeoutTime_HU_High_X451" SG_ 1292 RepeatMessageReq_ESCL 0;
BA_ "GenSigTimeoutTime_HU_B" SG_ 1292 RepeatMessageReq_ESCL 0;
BA_ "GenSigTimeoutTime_HU_A" SG_ 1292 RepeatMessageReq_ESCL 0;
BA_ "GenSigTimeoutMsg_HU_Mid_X451" SG_ 1292 RepeatMessageReq_ESCL 0;
BA_ "GenSigTimeoutMsg_HU_High_X451" SG_ 1292 RepeatMessageReq_ESCL 0;
BA_ "GenSigTimeoutMsg_HU_B" SG_ 1292 RepeatMessageReq_ESCL 0;
BA_ "GenSigTimeoutMsg_HU_A" SG_ 1292 RepeatMessageReq_ESCL 0;
BA_ "GenSigSendType" SG_ 1292 RepeatMessageReq_ESCL 7;
BA_ "GenSigCycleTimeActive" SG_ 1292 RepeatMessageReq_ESCL 200;
BA_ "GenSigCycleTime" SG_ 1292 RepeatMessageReq_ESCL 200;
BA_ "GenSigTimeoutTime_HU_Mid_X451" SG_ 1292 PreviousState_ESCL 0;
BA_ "GenSigTimeoutTime_HU_High_X451" SG_ 1292 PreviousState_ESCL 0;
BA_ "GenSigTimeoutTime_HU_B" SG_ 1292 PreviousState_ESCL 0;
BA_ "GenSigTimeoutTime_HU_A" SG_ 1292 PreviousState_ESCL 0;
BA_ "GenSigTimeoutMsg_HU_Mid_X451" SG_ 1292 PreviousState_ESCL 0;
BA_ "GenSigTimeoutMsg_HU_High_X451" SG_ 1292 PreviousState_ESCL 0;
BA_ "GenSigTimeoutMsg_HU_B" SG_ 1292 PreviousState_ESCL 0;
BA_ "GenSigTimeoutMsg_HU_A" SG_ 1292 PreviousState_ESCL 0;
BA_ "GenSigSendType" SG_ 1292 PreviousState_ESCL 7;
BA_ "GenSigCycleTimeActive" SG_ 1292 PreviousState_ESCL 200;
BA_ "GenSigCycleTime" SG_ 1292 PreviousState_ESCL 200;
BA_ "GenSigTimeoutTime_HU_Mid_X451" SG_ 1292 PartialNetworkInformation_ESCL 0;
BA_ "GenSigTimeoutTime_HU_High_X451" SG_ 1292 PartialNetworkInformation_ESCL 0;
BA_ "GenSigTimeoutTime_HU_B" SG_ 1292 PartialNetworkInformation_ESCL 0;
BA_ "GenSigTimeoutTime_HU_A" SG_ 1292 PartialNetworkInformation_ESCL 0;
BA_ "GenSigTimeoutMsg_HU_Mid_X451" SG_ 1292 PartialNetworkInformation_ESCL 0;
BA_ "GenSigTimeoutMsg_HU_High_X451" SG_ 1292 PartialNetworkInformation_ESCL 0;
BA_ "GenSigTimeoutMsg_HU_B" SG_ 1292 PartialNetworkInformation_ESCL 0;
BA_ "GenSigTimeoutMsg_HU_A" SG_ 1292 PartialNetworkInformation_ESCL 0;
BA_ "GenSigSendType" SG_ 1292 PartialNetworkInformation_ESCL 7;
BA_ "GenSigCycleTimeActive" SG_ 1292 PartialNetworkInformation_ESCL 200;
BA_ "GenSigCycleTime" SG_ 1292 PartialNetworkInformation_ESCL 200;
BA_ "GenSigTimeoutTime_HU_Mid_X451" SG_ 1292 NMCoOrdSlpReady_ESCL 0;
BA_ "GenSigTimeoutTime_HU_High_X451" SG_ 1292 NMCoOrdSlpReady_ESCL 0;
BA_ "GenSigTimeoutTime_HU_B" SG_ 1292 NMCoOrdSlpReady_ESCL 0;
BA_ "GenSigTimeoutTime_HU_A" SG_ 1292 NMCoOrdSlpReady_ESCL 0;
BA_ "GenSigTimeoutMsg_HU_Mid_X451" SG_ 1292 NMCoOrdSlpReady_ESCL 0;
BA_ "GenSigTimeoutMsg_HU_High_X451" SG_ 1292 NMCoOrdSlpReady_ESCL 0;
BA_ "GenSigTimeoutMsg_HU_B" SG_ 1292 NMCoOrdSlpReady_ESCL 0;
BA_ "GenSigTimeoutMsg_HU_A" SG_ 1292 NMCoOrdSlpReady_ESCL 0;
BA_ "GenSigSendType" SG_ 1292 NMCoOrdSlpReady_ESCL 7;
BA_ "GenSigCycleTimeActive" SG_ 1292 NMCoOrdSlpReady_ESCL 200;
BA_ "GenSigCycleTime" SG_ 1292 NMCoOrdSlpReady_ESCL 200;
BA_ "GenSigTimeoutTime_HU_Mid_X451" SG_ 1292 ESCL_NMPDU_USER_DATA_D5 0;
BA_ "GenSigTimeoutTime_HU_High_X451" SG_ 1292 ESCL_NMPDU_USER_DATA_D5 0;
BA_ "GenSigTimeoutTime_HU_B" SG_ 1292 ESCL_NMPDU_USER_DATA_D5 0;
BA_ "GenSigTimeoutTime_HU_A" SG_ 1292 ESCL_NMPDU_USER_DATA_D5 0;
BA_ "GenSigTimeoutMsg_HU_Mid_X451" SG_ 1292 ESCL_NMPDU_USER_DATA_D5 0;
BA_ "GenSigTimeoutMsg_HU_High_X451" SG_ 1292 ESCL_NMPDU_USER_DATA_D5 0;
BA_ "GenSigTimeoutMsg_HU_B" SG_ 1292 ESCL_NMPDU_USER_DATA_D5 0;
BA_ "GenSigTimeoutMsg_HU_A" SG_ 1292 ESCL_NMPDU_USER_DATA_D5 0;
BA_ "GenSigSendType" SG_ 1292 ESCL_NMPDU_USER_DATA_D5 7;
BA_ "GenSigCycleTimeActive" SG_ 1292 ESCL_NMPDU_USER_DATA_D5 200;
BA_ "GenSigCycleTime" SG_ 1292 ESCL_NMPDU_USER_DATA_D5 200;
BA_ "GenSigTimeoutTime_HU_Mid_X451" SG_ 437 DctPepsAuthReq 0;
BA_ "GenSigTimeoutTime_HU_High_X451" SG_ 437 DctPepsAuthReq 0;
BA_ "GenSigTimeoutTime_HU_B" SG_ 437 DctPepsAuthReq 0;
BA_ "GenSigTimeoutTime_HU_A" SG_ 437 DctPepsAuthReq 0;
BA_ "GenSigTimeoutMsg_HU_Mid_X451" SG_ 437 DctPepsAuthReq 0;
BA_ "GenSigTimeoutMsg_HU_High_X451" SG_ 437 DctPepsAuthReq 0;
BA_ "GenSigTimeoutMsg_HU_B" SG_ 437 DctPepsAuthReq 0;
BA_ "GenSigTimeoutMsg_HU_A" SG_ 437 DctPepsAuthReq 0;
BA_ "GenSigSendType" SG_ 437 DctPepsAuthReq 1;
BA_ "GenSigTimeoutMsg_HU_High_X445" SG_ 437 DctPepsAuthReq 0;
BA_ "GenSigTimeoutMsg_HU_Mid_X445" SG_ 437 DctPepsAuthReq 0;
BA_ "GenSigTimeoutTime_HU_High_X445" SG_ 437 DctPepsAuthReq 0;
BA_ "GenSigTimeoutTime_HU_Mid_X445" SG_ 437 DctPepsAuthReq 0;
BA_ "GenSigTimeoutMsg_IVI" SG_ 437 DctPepsAuthReq 0;
BA_ "GenSigTimeoutTime_IVI" SG_ 437 DctPepsAuthReq 0;
BA_ "GenSigSendType" SG_ 659 TCUGSAPosChecksum 7;
BA_ "GenSigCycleTimeActive" SG_ 659 TCUGSAPosChecksum 100;
BA_ "GenSigCycleTime" SG_ 659 TCUGSAPosChecksum 100;
BA_ "GenSigSendType" SG_ 659 TCUGSAPosAliveCounter 7;
BA_ "GenSigCycleTimeActive" SG_ 659 TCUGSAPosAliveCounter 100;
BA_ "GenSigCycleTime" SG_ 659 TCUGSAPosAliveCounter 100;
BA_ "GenSigSendType" SG_ 659 TCUGSAPositionDisplay 7;
BA_ "GenSigCycleTimeActive" SG_ 659 TCUGSAPositionDisplay 100;
BA_ "GenSigCycleTime" SG_ 659 TCUGSAPositionDisplay 100;
BA_ "GenSigSendType" SG_ 659 TCUGSMWarning 7;
BA_ "GenSigCycleTimeActive" SG_ 659 TCUGSMWarning 100;
BA_ "GenSigCycleTime" SG_ 659 TCUGSMWarning 100;
BA_ "GenSigSendType" SG_ 659 TCUKeepNEtinAfterRunGSA 7;
BA_ "GenSigCycleTimeActive" SG_ 659 TCUKeepNEtinAfterRunGSA 100;
BA_ "GenSigCycleTime" SG_ 659 TCUKeepNEtinAfterRunGSA 100;
BA_ "GenSigStartValue" SG_ 659 TCUGSARangeLockReq 30;
BA_ "GenSigSendType" SG_ 659 TCUGSARangeLockReq 7;
BA_ "GenSigCycleTimeActive" SG_ 659 TCUGSARangeLockReq 100;
BA_ "GenSigCycleTime" SG_ 659 TCUGSARangeLockReq 100;
BA_ "GenSigTimeoutTime_HU_Mid_X451" SG_ 1610 SRR_DiagResponse_UUDT 0;
BA_ "GenSigTimeoutTime_HU_High_X451" SG_ 1610 SRR_DiagResponse_UUDT 0;
BA_ "GenSigTimeoutTime_HU_B" SG_ 1610 SRR_DiagResponse_UUDT 0;
BA_ "GenSigTimeoutTime_HU_A" SG_ 1610 SRR_DiagResponse_UUDT 0;
BA_ "GenSigTimeoutMsg_HU_Mid_X451" SG_ 1610 SRR_DiagResponse_UUDT 0;
BA_ "GenSigTimeoutMsg_HU_High_X451" SG_ 1610 SRR_DiagResponse_UUDT 0;
BA_ "GenSigTimeoutMsg_HU_B" SG_ 1610 SRR_DiagResponse_UUDT 0;
BA_ "GenSigTimeoutMsg_HU_A" SG_ 1610 SRR_DiagResponse_UUDT 0;
BA_ "GenSigSendType" SG_ 1610 SRR_DiagResponse_UUDT 1;
BA_ "GenSigTimeoutMsg_HU_High_X445" SG_ 1610 SRR_DiagResponse_UUDT 0;
BA_ "GenSigTimeoutMsg_HU_Mid_X445" SG_ 1610 SRR_DiagResponse_UUDT 0;
BA_ "GenSigTimeoutTime_HU_High_X445" SG_ 1610 SRR_DiagResponse_UUDT 0;
BA_ "GenSigTimeoutTime_HU_Mid_X445" SG_ 1610 SRR_DiagResponse_UUDT 0;
BA_ "GenSigTimeoutMsg_IVI" SG_ 1610 SRR_DiagResponse_UUDT 0;
BA_ "GenSigTimeoutTime_IVI" SG_ 1610 SRR_DiagResponse_UUDT 0;
BA_ "GenSigTimeoutTime_HU_Mid_X451" SG_ 1866 SRR_DiagResponse_USDT 0;
BA_ "GenSigTimeoutTime_HU_High_X451" SG_ 1866 SRR_DiagResponse_USDT 0;
BA_ "GenSigTimeoutTime_HU_B" SG_ 1866 SRR_DiagResponse_USDT 0;
BA_ "GenSigTimeoutTime_HU_A" SG_ 1866 SRR_DiagResponse_USDT 0;
BA_ "GenSigTimeoutMsg_HU_Mid_X451" SG_ 1866 SRR_DiagResponse_USDT 0;
BA_ "GenSigTimeoutMsg_HU_High_X451" SG_ 1866 SRR_DiagResponse_USDT 0;
BA_ "GenSigTimeoutMsg_HU_B" SG_ 1866 SRR_DiagResponse_USDT 0;
BA_ "GenSigTimeoutMsg_HU_A" SG_ 1866 SRR_DiagResponse_USDT 0;
BA_ "GenSigSendType" SG_ 1866 SRR_DiagResponse_USDT 1;
BA_ "GenSigTimeoutMsg_HU_High_X445" SG_ 1866 SRR_DiagResponse_USDT 0;
BA_ "GenSigTimeoutMsg_HU_Mid_X445" SG_ 1866 SRR_DiagResponse_USDT 0;
BA_ "GenSigTimeoutTime_HU_High_X445" SG_ 1866 SRR_DiagResponse_USDT 0;
BA_ "GenSigTimeoutTime_HU_Mid_X445" SG_ 1866 SRR_DiagResponse_USDT 0;
BA_ "GenSigTimeoutMsg_IVI" SG_ 1866 SRR_DiagResponse_USDT 0;
BA_ "GenSigTimeoutTime_IVI" SG_ 1866 SRR_DiagResponse_USDT 0;
BA_ "GenSigTimeoutTime_HU_Mid_X451" SG_ 1858 SRR_DiagRequest 0;
BA_ "GenSigTimeoutTime_HU_High_X451" SG_ 1858 SRR_DiagRequest 0;
BA_ "GenSigTimeoutTime_HU_B" SG_ 1858 SRR_DiagRequest 0;
BA_ "GenSigTimeoutTime_HU_A" SG_ 1858 SRR_DiagRequest 0;
BA_ "GenSigTimeoutMsg_HU_Mid_X451" SG_ 1858 SRR_DiagRequest 0;
BA_ "GenSigTimeoutMsg_HU_High_X451" SG_ 1858 SRR_DiagRequest 0;
BA_ "GenSigTimeoutMsg_HU_B" SG_ 1858 SRR_DiagRequest 0;
BA_ "GenSigTimeoutMsg_HU_A" SG_ 1858 SRR_DiagRequest 0;
BA_ "GenSigSendType" SG_ 1858 SRR_DiagRequest 1;
BA_ "GenSigTimeoutMsg_HU_High_X445" SG_ 1858 SRR_DiagRequest 0;
BA_ "GenSigTimeoutMsg_HU_Mid_X445" SG_ 1858 SRR_DiagRequest 0;
BA_ "GenSigTimeoutTime_HU_High_X445" SG_ 1858 SRR_DiagRequest 0;
BA_ "GenSigTimeoutTime_HU_Mid_X445" SG_ 1858 SRR_DiagRequest 0;
BA_ "GenSigTimeoutMsg_IVI" SG_ 1858 SRR_DiagRequest 0;
BA_ "GenSigTimeoutTime_IVI" SG_ 1858 SRR_DiagRequest 0;
BA_ "GenSigTimeoutTime_HU_Mid_X451" SG_ 1608 FR_DiagResponse_UUDT 0;
BA_ "GenSigTimeoutTime_HU_High_X451" SG_ 1608 FR_DiagResponse_UUDT 0;
BA_ "GenSigTimeoutTime_HU_B" SG_ 1608 FR_DiagResponse_UUDT 0;
BA_ "GenSigTimeoutTime_HU_A" SG_ 1608 FR_DiagResponse_UUDT 0;
BA_ "GenSigTimeoutMsg_HU_Mid_X451" SG_ 1608 FR_DiagResponse_UUDT 0;
BA_ "GenSigTimeoutMsg_HU_High_X451" SG_ 1608 FR_DiagResponse_UUDT 0;
BA_ "GenSigTimeoutMsg_HU_B" SG_ 1608 FR_DiagResponse_UUDT 0;
BA_ "GenSigTimeoutMsg_HU_A" SG_ 1608 FR_DiagResponse_UUDT 0;
BA_ "GenSigSendType" SG_ 1608 FR_DiagResponse_UUDT 1;
BA_ "GenSigTimeoutMsg_HU_High_X445" SG_ 1608 FR_DiagResponse_UUDT 0;
BA_ "GenSigTimeoutMsg_HU_Mid_X445" SG_ 1608 FR_DiagResponse_UUDT 0;
BA_ "GenSigTimeoutTime_HU_High_X445" SG_ 1608 FR_DiagResponse_UUDT 0;
BA_ "GenSigTimeoutTime_HU_Mid_X445" SG_ 1608 FR_DiagResponse_UUDT 0;
BA_ "GenSigTimeoutMsg_IVI" SG_ 1608 FR_DiagResponse_UUDT 0;
BA_ "GenSigTimeoutTime_IVI" SG_ 1608 FR_DiagResponse_UUDT 0;
BA_ "GenSigTimeoutTime_HU_Mid_X451" SG_ 1864 FR_DiagResponse_USDT 0;
BA_ "GenSigTimeoutTime_HU_High_X451" SG_ 1864 FR_DiagResponse_USDT 0;
BA_ "GenSigTimeoutTime_HU_B" SG_ 1864 FR_DiagResponse_USDT 0;
BA_ "GenSigTimeoutTime_HU_A" SG_ 1864 FR_DiagResponse_USDT 0;
BA_ "GenSigTimeoutMsg_HU_Mid_X451" SG_ 1864 FR_DiagResponse_USDT 0;
BA_ "GenSigTimeoutMsg_HU_High_X451" SG_ 1864 FR_DiagResponse_USDT 0;
BA_ "GenSigTimeoutMsg_HU_B" SG_ 1864 FR_DiagResponse_USDT 0;
BA_ "GenSigTimeoutMsg_HU_A" SG_ 1864 FR_DiagResponse_USDT 0;
BA_ "GenSigSendType" SG_ 1864 FR_DiagResponse_USDT 1;
BA_ "GenSigTimeoutMsg_HU_High_X445" SG_ 1864 FR_DiagResponse_USDT 0;
BA_ "GenSigTimeoutMsg_HU_Mid_X445" SG_ 1864 FR_DiagResponse_USDT 0;
BA_ "GenSigTimeoutTime_HU_High_X445" SG_ 1864 FR_DiagResponse_USDT 0;
BA_ "GenSigTimeoutTime_HU_Mid_X445" SG_ 1864 FR_DiagResponse_USDT 0;
BA_ "GenSigTimeoutMsg_IVI" SG_ 1864 FR_DiagResponse_USDT 0;
BA_ "GenSigTimeoutTime_IVI" SG_ 1864 FR_DiagResponse_USDT 0;
BA_ "GenSigTimeoutTime_HU_Mid_X451" SG_ 1856 FR_DiagRequest 0;
BA_ "GenSigTimeoutTime_HU_High_X451" SG_ 1856 FR_DiagRequest 0;
BA_ "GenSigTimeoutTime_HU_B" SG_ 1856 FR_DiagRequest 0;
BA_ "GenSigTimeoutTime_HU_A" SG_ 1856 FR_DiagRequest 0;
BA_ "GenSigTimeoutMsg_HU_Mid_X451" SG_ 1856 FR_DiagRequest 0;
BA_ "GenSigTimeoutMsg_HU_High_X451" SG_ 1856 FR_DiagRequest 0;
BA_ "GenSigTimeoutMsg_HU_B" SG_ 1856 FR_DiagRequest 0;
BA_ "GenSigTimeoutMsg_HU_A" SG_ 1856 FR_DiagRequest 0;
BA_ "GenSigSendType" SG_ 1856 FR_DiagRequest 1;
BA_ "GenSigTimeoutMsg_HU_High_X445" SG_ 1856 FR_DiagRequest 0;
BA_ "GenSigTimeoutMsg_HU_Mid_X445" SG_ 1856 FR_DiagRequest 0;
BA_ "GenSigTimeoutTime_HU_High_X445" SG_ 1856 FR_DiagRequest 0;
BA_ "GenSigTimeoutTime_HU_Mid_X445" SG_ 1856 FR_DiagRequest 0;
BA_ "GenSigTimeoutMsg_IVI" SG_ 1856 FR_DiagRequest 0;
BA_ "GenSigTimeoutTime_IVI" SG_ 1856 FR_DiagRequest 0;
BA_ "GenSigTimeoutTime_HU_Mid_X451" SG_ 1609 FCM_DiagResponse_UUDT 0;
BA_ "GenSigTimeoutTime_HU_High_X451" SG_ 1609 FCM_DiagResponse_UUDT 0;
BA_ "GenSigTimeoutTime_HU_B" SG_ 1609 FCM_DiagResponse_UUDT 0;
BA_ "GenSigTimeoutTime_HU_A" SG_ 1609 FCM_DiagResponse_UUDT 0;
BA_ "GenSigTimeoutMsg_HU_Mid_X451" SG_ 1609 FCM_DiagResponse_UUDT 0;
BA_ "GenSigTimeoutMsg_HU_High_X451" SG_ 1609 FCM_DiagResponse_UUDT 0;
BA_ "GenSigTimeoutMsg_HU_B" SG_ 1609 FCM_DiagResponse_UUDT 0;
BA_ "GenSigTimeoutMsg_HU_A" SG_ 1609 FCM_DiagResponse_UUDT 0;
BA_ "GenSigSendType" SG_ 1609 FCM_DiagResponse_UUDT 1;
BA_ "GenSigTimeoutMsg_HU_High_X445" SG_ 1609 FCM_DiagResponse_UUDT 0;
BA_ "GenSigTimeoutMsg_HU_Mid_X445" SG_ 1609 FCM_DiagResponse_UUDT 0;
BA_ "GenSigTimeoutTime_HU_High_X445" SG_ 1609 FCM_DiagResponse_UUDT 0;
BA_ "GenSigTimeoutTime_HU_Mid_X445" SG_ 1609 FCM_DiagResponse_UUDT 0;
BA_ "GenSigTimeoutMsg_IVI" SG_ 1609 FCM_DiagResponse_UUDT 0;
BA_ "GenSigTimeoutTime_IVI" SG_ 1609 FCM_DiagResponse_UUDT 0;
BA_ "GenSigTimeoutTime_HU_Mid_X451" SG_ 1865 FCM_DiagResponse_USDT 0;
BA_ "GenSigTimeoutTime_HU_High_X451" SG_ 1865 FCM_DiagResponse_USDT 0;
BA_ "GenSigTimeoutTime_HU_B" SG_ 1865 FCM_DiagResponse_USDT 0;
BA_ "GenSigTimeoutTime_HU_A" SG_ 1865 FCM_DiagResponse_USDT 0;
BA_ "GenSigTimeoutMsg_HU_Mid_X451" SG_ 1865 FCM_DiagResponse_USDT 0;
BA_ "GenSigTimeoutMsg_HU_High_X451" SG_ 1865 FCM_DiagResponse_USDT 0;
BA_ "GenSigTimeoutMsg_HU_B" SG_ 1865 FCM_DiagResponse_USDT 0;
BA_ "GenSigTimeoutMsg_HU_A" SG_ 1865 FCM_DiagResponse_USDT 0;
BA_ "GenSigSendType" SG_ 1865 FCM_DiagResponse_USDT 1;
BA_ "GenSigTimeoutMsg_HU_High_X445" SG_ 1865 FCM_DiagResponse_USDT 0;
BA_ "GenSigTimeoutMsg_HU_Mid_X445" SG_ 1865 FCM_DiagResponse_USDT 0;
BA_ "GenSigTimeoutTime_HU_High_X445" SG_ 1865 FCM_DiagResponse_USDT 0;
BA_ "GenSigTimeoutTime_HU_Mid_X445" SG_ 1865 FCM_DiagResponse_USDT 0;
BA_ "GenSigTimeoutMsg_IVI" SG_ 1865 FCM_DiagResponse_USDT 0;
BA_ "GenSigTimeoutTime_IVI" SG_ 1865 FCM_DiagResponse_USDT 0;
BA_ "GenSigTimeoutTime_HU_Mid_X451" SG_ 1857 FCM_DiagRequest 0;
BA_ "GenSigTimeoutTime_HU_High_X451" SG_ 1857 FCM_DiagRequest 0;
BA_ "GenSigTimeoutTime_HU_B" SG_ 1857 FCM_DiagRequest 0;
BA_ "GenSigTimeoutTime_HU_A" SG_ 1857 FCM_DiagRequest 0;
BA_ "GenSigTimeoutMsg_HU_Mid_X451" SG_ 1857 FCM_DiagRequest 0;
BA_ "GenSigTimeoutMsg_HU_High_X451" SG_ 1857 FCM_DiagRequest 0;
BA_ "GenSigTimeoutMsg_HU_B" SG_ 1857 FCM_DiagRequest 0;
BA_ "GenSigTimeoutMsg_HU_A" SG_ 1857 FCM_DiagRequest 0;
BA_ "GenSigSendType" SG_ 1857 FCM_DiagRequest 1;
BA_ "GenSigTimeoutMsg_HU_High_X445" SG_ 1857 FCM_DiagRequest 0;
BA_ "GenSigTimeoutMsg_HU_Mid_X445" SG_ 1857 FCM_DiagRequest 0;
BA_ "GenSigTimeoutTime_HU_High_X445" SG_ 1857 FCM_DiagRequest 0;
BA_ "GenSigTimeoutTime_HU_Mid_X445" SG_ 1857 FCM_DiagRequest 0;
BA_ "GenSigTimeoutMsg_IVI" SG_ 1857 FCM_DiagRequest 0;
BA_ "GenSigTimeoutTime_IVI" SG_ 1857 FCM_DiagRequest 0;
BA_ "GenSigTimeoutTime_HU_Mid_X451" SG_ 524 RcwOnOffConfigState 0;
BA_ "GenSigTimeoutTime_HU_High_X451" SG_ 524 RcwOnOffConfigState 0;
BA_ "GenSigTimeoutTime_HU_B" SG_ 524 RcwOnOffConfigState 0;
BA_ "GenSigTimeoutTime_HU_A" SG_ 524 RcwOnOffConfigState 0;
BA_ "GenSigTimeoutMsg_HU_Mid_X451" SG_ 524 RcwOnOffConfigState 0;
BA_ "GenSigTimeoutMsg_HU_High_X451" SG_ 524 RcwOnOffConfigState 0;
BA_ "GenSigTimeoutMsg_HU_B" SG_ 524 RcwOnOffConfigState 0;
BA_ "GenSigTimeoutMsg_HU_A" SG_ 524 RcwOnOffConfigState 0;
BA_ "GenSigSendType" SG_ 524 RcwOnOffConfigState 1;
BA_ "GenSigTimeoutMsg_HU_High_X445" SG_ 524 RcwOnOffConfigState 0;
BA_ "GenSigTimeoutMsg_HU_Mid_X445" SG_ 524 RcwOnOffConfigState 0;
BA_ "GenSigTimeoutTime_HU_High_X445" SG_ 524 RcwOnOffConfigState 0;
BA_ "GenSigTimeoutTime_HU_Mid_X445" SG_ 524 RcwOnOffConfigState 0;
BA_ "GenSigTimeoutMsg_IVI" SG_ 524 RcwOnOffConfigState 0;
BA_ "GenSigTimeoutTime_IVI" SG_ 524 RcwOnOffConfigState 0;
BA_ "GenSigTimeoutTime_HU_Mid_X451" SG_ 524 BsdOnOffConfigState 0;
BA_ "GenSigTimeoutTime_HU_High_X451" SG_ 524 BsdOnOffConfigState 0;
BA_ "GenSigTimeoutTime_HU_B" SG_ 524 BsdOnOffConfigState 0;
BA_ "GenSigTimeoutTime_HU_A" SG_ 524 BsdOnOffConfigState 0;
BA_ "GenSigTimeoutMsg_HU_Mid_X451" SG_ 524 BsdOnOffConfigState 0;
BA_ "GenSigTimeoutMsg_HU_High_X451" SG_ 524 BsdOnOffConfigState 0;
BA_ "GenSigTimeoutMsg_HU_B" SG_ 524 BsdOnOffConfigState 0;
BA_ "GenSigTimeoutMsg_HU_A" SG_ 524 BsdOnOffConfigState 0;
BA_ "GenSigSendType" SG_ 524 BsdOnOffConfigState 1;
BA_ "GenSigTimeoutMsg_HU_High_X445" SG_ 524 BsdOnOffConfigState 0;
BA_ "GenSigTimeoutMsg_HU_Mid_X445" SG_ 524 BsdOnOffConfigState 0;
BA_ "GenSigTimeoutTime_HU_High_X445" SG_ 524 BsdOnOffConfigState 0;
BA_ "GenSigTimeoutTime_HU_Mid_X445" SG_ 524 BsdOnOffConfigState 0;
BA_ "GenSigTimeoutMsg_IVI" SG_ 524 BsdOnOffConfigState 0;
BA_ "GenSigTimeoutTime_IVI" SG_ 524 BsdOnOffConfigState 0;
BA_ "GenSigTimeoutTime_HU_Mid_X451" SG_ 524 DoaOnOffConfigState 0;
BA_ "GenSigTimeoutTime_HU_High_X451" SG_ 524 DoaOnOffConfigState 0;
BA_ "GenSigTimeoutTime_HU_B" SG_ 524 DoaOnOffConfigState 0;
BA_ "GenSigTimeoutTime_HU_A" SG_ 524 DoaOnOffConfigState 0;
BA_ "GenSigTimeoutMsg_HU_Mid_X451" SG_ 524 DoaOnOffConfigState 0;
BA_ "GenSigTimeoutMsg_HU_High_X451" SG_ 524 DoaOnOffConfigState 0;
BA_ "GenSigTimeoutMsg_HU_B" SG_ 524 DoaOnOffConfigState 0;
BA_ "GenSigTimeoutMsg_HU_A" SG_ 524 DoaOnOffConfigState 0;
BA_ "GenSigSendType" SG_ 524 DoaOnOffConfigState 1;
BA_ "GenSigTimeoutMsg_HU_High_X445" SG_ 524 DoaOnOffConfigState 0;
BA_ "GenSigTimeoutMsg_HU_Mid_X445" SG_ 524 DoaOnOffConfigState 0;
BA_ "GenSigTimeoutTime_HU_High_X445" SG_ 524 DoaOnOffConfigState 0;
BA_ "GenSigTimeoutTime_HU_Mid_X445" SG_ 524 DoaOnOffConfigState 0;
BA_ "GenSigTimeoutMsg_IVI" SG_ 524 DoaOnOffConfigState 0;
BA_ "GenSigTimeoutTime_IVI" SG_ 524 DoaOnOffConfigState 0;
BA_ "GenSigTimeoutTime_HU_Mid_X451" SG_ 524 RctaOnOffConfigState 0;
BA_ "GenSigTimeoutTime_HU_High_X451" SG_ 524 RctaOnOffConfigState 0;
BA_ "GenSigTimeoutTime_HU_B" SG_ 524 RctaOnOffConfigState 0;
BA_ "GenSigTimeoutTime_HU_A" SG_ 524 RctaOnOffConfigState 0;
BA_ "GenSigTimeoutMsg_HU_Mid_X451" SG_ 524 RctaOnOffConfigState 0;
BA_ "GenSigTimeoutMsg_HU_High_X451" SG_ 524 RctaOnOffConfigState 0;
BA_ "GenSigTimeoutMsg_HU_B" SG_ 524 RctaOnOffConfigState 0;
BA_ "GenSigTimeoutMsg_HU_A" SG_ 524 RctaOnOffConfigState 0;
BA_ "GenSigSendType" SG_ 524 RctaOnOffConfigState 1;
BA_ "GenSigTimeoutMsg_HU_High_X445" SG_ 524 RctaOnOffConfigState 0;
BA_ "GenSigTimeoutMsg_HU_Mid_X445" SG_ 524 RctaOnOffConfigState 0;
BA_ "GenSigTimeoutTime_HU_High_X445" SG_ 524 RctaOnOffConfigState 0;
BA_ "GenSigTimeoutTime_HU_Mid_X445" SG_ 524 RctaOnOffConfigState 0;
BA_ "GenSigTimeoutMsg_IVI" SG_ 524 RctaOnOffConfigState 0;
BA_ "GenSigTimeoutTime_IVI" SG_ 524 RctaOnOffConfigState 0;
BA_ "GenSigSendType" SG_ 593 RLRadarPresence 7;
BA_ "GenSigCycleTimeActive" SG_ 593 RLRadarPresence 100;
BA_ "GenSigCycleTime" SG_ 593 RLRadarPresence 100;
BA_ "GenSigTimeoutMsg_HU_High_X445" SG_ 593 RLRadarPresence 0;
BA_ "GenSigTimeoutMsg_HU_Mid_X445" SG_ 593 RLRadarPresence 0;
BA_ "GenSigTimeoutTime_HU_High_X445" SG_ 593 RLRadarPresence 0;
BA_ "GenSigTimeoutTime_HU_Mid_X445" SG_ 593 RLRadarPresence 0;
BA_ "GenSigTimeoutMsg_IVI" SG_ 593 RLRadarPresence 0;
BA_ "GenSigTimeoutTime_IVI" SG_ 593 RLRadarPresence 0;
BA_ "GenSigSendType" SG_ 593 RctaStates 7;
BA_ "GenSigCycleTimeActive" SG_ 593 RctaStates 100;
BA_ "GenSigCycleTime" SG_ 593 RctaStates 100;
BA_ "GenSigTimeoutMsg_HU_High_X445" SG_ 593 RctaStates 0;
BA_ "GenSigTimeoutMsg_HU_Mid_X445" SG_ 593 RctaStates 0;
BA_ "GenSigTimeoutTime_HU_High_X445" SG_ 593 RctaStates 0;
BA_ "GenSigTimeoutTime_HU_Mid_X445" SG_ 593 RctaStates 0;
BA_ "GenSigTimeoutMsg_IVI" SG_ 593 RctaStates 0;
BA_ "GenSigTimeoutTime_IVI" SG_ 593 RctaStates 0;
BA_ "GenSigStartValue" SG_ 593 RctaOnOffState 1;
BA_ "GenSigSendType" SG_ 593 RctaOnOffState 7;
BA_ "GenSigCycleTimeActive" SG_ 593 RctaOnOffState 100;
BA_ "GenSigCycleTime" SG_ 593 RctaOnOffState 100;
BA_ "GenSigTimeoutMsg_HU_High_X445" SG_ 593 RctaOnOffState 0;
BA_ "GenSigTimeoutMsg_HU_Mid_X445" SG_ 593 RctaOnOffState 0;
BA_ "GenSigTimeoutTime_HU_High_X445" SG_ 593 RctaOnOffState 0;
BA_ "GenSigTimeoutTime_HU_Mid_X445" SG_ 593 RctaOnOffState 0;
BA_ "GenSigTimeoutMsg_IVI" SG_ 593 RctaOnOffState 0;
BA_ "GenSigTimeoutTime_IVI" SG_ 593 RctaOnOffState 0;
BA_ "GenSigSendType" SG_ 593 RctaIndRight 7;
BA_ "GenSigCycleTimeActive" SG_ 593 RctaIndRight 100;
BA_ "GenSigCycleTime" SG_ 593 RctaIndRight 100;
BA_ "GenSigTimeoutMsg_HU_High_X445" SG_ 593 RctaIndRight 0;
BA_ "GenSigTimeoutMsg_HU_Mid_X445" SG_ 593 RctaIndRight 0;
BA_ "GenSigTimeoutTime_HU_High_X445" SG_ 593 RctaIndRight 0;
BA_ "GenSigTimeoutTime_HU_Mid_X445" SG_ 593 RctaIndRight 0;
BA_ "GenSigTimeoutMsg_IVI" SG_ 593 RctaIndRight 0;
BA_ "GenSigTimeoutTime_IVI" SG_ 593 RctaIndRight 0;
BA_ "GenSigSendType" SG_ 593 RctaIndLeft 7;
BA_ "GenSigCycleTimeActive" SG_ 593 RctaIndLeft 100;
BA_ "GenSigCycleTime" SG_ 593 RctaIndLeft 100;
BA_ "GenSigTimeoutMsg_HU_High_X445" SG_ 593 RctaIndLeft 0;
BA_ "GenSigTimeoutMsg_HU_Mid_X445" SG_ 593 RctaIndLeft 0;
BA_ "GenSigTimeoutTime_HU_High_X445" SG_ 593 RctaIndLeft 0;
BA_ "GenSigTimeoutTime_HU_Mid_X445" SG_ 593 RctaIndLeft 0;
BA_ "GenSigTimeoutMsg_IVI" SG_ 593 RctaIndLeft 0;
BA_ "GenSigTimeoutTime_IVI" SG_ 593 RctaIndLeft 0;
BA_ "GenSigTimeoutTime_HU_Mid_X451" SG_ 593 RcwWarning 0;
BA_ "GenSigTimeoutTime_HU_High_X451" SG_ 593 RcwWarning 0;
BA_ "GenSigTimeoutTime_HU_B" SG_ 593 RcwWarning 0;
BA_ "GenSigTimeoutTime_HU_A" SG_ 593 RcwWarning 0;
BA_ "GenSigTimeoutMsg_HU_Mid_X451" SG_ 593 RcwWarning 0;
BA_ "GenSigTimeoutMsg_HU_High_X451" SG_ 593 RcwWarning 0;
BA_ "GenSigTimeoutMsg_HU_B" SG_ 593 RcwWarning 0;
BA_ "GenSigTimeoutMsg_HU_A" SG_ 593 RcwWarning 0;
BA_ "GenSigSendType" SG_ 593 RcwWarning 7;
BA_ "GenSigCycleTimeActive" SG_ 593 RcwWarning 100;
BA_ "GenSigCycleTime" SG_ 593 RcwWarning 100;
BA_ "GenSigTimeoutTime_HU_Mid_X451" SG_ 593 RcwStates 0;
BA_ "GenSigTimeoutTime_HU_High_X451" SG_ 593 RcwStates 0;
BA_ "GenSigTimeoutTime_HU_B" SG_ 593 RcwStates 0;
BA_ "GenSigTimeoutTime_HU_A" SG_ 593 RcwStates 0;
BA_ "GenSigTimeoutMsg_HU_Mid_X451" SG_ 593 RcwStates 0;
BA_ "GenSigTimeoutMsg_HU_High_X451" SG_ 593 RcwStates 0;
BA_ "GenSigTimeoutMsg_HU_B" SG_ 593 RcwStates 0;
BA_ "GenSigTimeoutMsg_HU_A" SG_ 593 RcwStates 0;
BA_ "GenSigSendType" SG_ 593 RcwStates 7;
BA_ "GenSigCycleTimeActive" SG_ 593 RcwStates 100;
BA_ "GenSigCycleTime" SG_ 593 RcwStates 100;
BA_ "GenSigStartValue" SG_ 593 RcwOnOffState 1;
BA_ "GenSigSendType" SG_ 593 RcwOnOffState 7;
BA_ "GenSigCycleTimeActive" SG_ 593 RcwOnOffState 100;
BA_ "GenSigCycleTime" SG_ 593 RcwOnOffState 100;
BA_ "GenSigTimeoutMsg_HU_High_X445" SG_ 593 RcwOnOffState 0;
BA_ "GenSigTimeoutMsg_HU_Mid_X445" SG_ 593 RcwOnOffState 0;
BA_ "GenSigTimeoutTime_HU_High_X445" SG_ 593 RcwOnOffState 0;
BA_ "GenSigTimeoutTime_HU_Mid_X445" SG_ 593 RcwOnOffState 0;
BA_ "GenSigTimeoutMsg_IVI" SG_ 593 RcwOnOffState 0;
BA_ "GenSigTimeoutTime_IVI" SG_ 593 RcwOnOffState 0;
BA_ "GenSigTimeoutTime_HU_Mid_X451" SG_ 593 BsdStates 0;
BA_ "GenSigTimeoutTime_HU_High_X451" SG_ 593 BsdStates 0;
BA_ "GenSigTimeoutTime_HU_B" SG_ 593 BsdStates 0;
BA_ "GenSigTimeoutTime_HU_A" SG_ 593 BsdStates 0;
BA_ "GenSigTimeoutMsg_HU_Mid_X451" SG_ 593 BsdStates 0;
BA_ "GenSigTimeoutMsg_HU_High_X451" SG_ 593 BsdStates 0;
BA_ "GenSigTimeoutMsg_HU_B" SG_ 593 BsdStates 0;
BA_ "GenSigTimeoutMsg_HU_A" SG_ 593 BsdStates 0;
BA_ "GenSigSendType" SG_ 593 BsdStates 7;
BA_ "GenSigCycleTimeActive" SG_ 593 BsdStates 100;
BA_ "GenSigCycleTime" SG_ 593 BsdStates 100;
BA_ "GenSigSendType" SG_ 593 BsdSoundRight 7;
BA_ "GenSigCycleTimeActive" SG_ 593 BsdSoundRight 100;
BA_ "GenSigCycleTime" SG_ 593 BsdSoundRight 100;
BA_ "GenSigTimeoutMsg_HU_High_X445" SG_ 593 BsdSoundRight 0;
BA_ "GenSigTimeoutMsg_HU_Mid_X445" SG_ 593 BsdSoundRight 0;
BA_ "GenSigTimeoutTime_HU_High_X445" SG_ 593 BsdSoundRight 0;
BA_ "GenSigTimeoutTime_HU_Mid_X445" SG_ 593 BsdSoundRight 0;
BA_ "GenSigTimeoutMsg_IVI" SG_ 593 BsdSoundRight 0;
BA_ "GenSigTimeoutTime_IVI" SG_ 593 BsdSoundRight 0;
BA_ "GenSigSendType" SG_ 593 BsdSoundLeft 7;
BA_ "GenSigCycleTimeActive" SG_ 593 BsdSoundLeft 100;
BA_ "GenSigCycleTime" SG_ 593 BsdSoundLeft 100;
BA_ "GenSigTimeoutMsg_HU_High_X445" SG_ 593 BsdSoundLeft 0;
BA_ "GenSigTimeoutMsg_HU_Mid_X445" SG_ 593 BsdSoundLeft 0;
BA_ "GenSigTimeoutTime_HU_High_X445" SG_ 593 BsdSoundLeft 0;
BA_ "GenSigTimeoutTime_HU_Mid_X445" SG_ 593 BsdSoundLeft 0;
BA_ "GenSigTimeoutMsg_IVI" SG_ 593 BsdSoundLeft 0;
BA_ "GenSigTimeoutTime_IVI" SG_ 593 BsdSoundLeft 0;
BA_ "GenSigStartValue" SG_ 593 BsdOnOffState 1;
BA_ "GenSigSendType" SG_ 593 BsdOnOffState 7;
BA_ "GenSigCycleTimeActive" SG_ 593 BsdOnOffState 100;
BA_ "GenSigCycleTime" SG_ 593 BsdOnOffState 100;
BA_ "GenSigTimeoutMsg_HU_High_X445" SG_ 593 BsdOnOffState 0;
BA_ "GenSigTimeoutMsg_HU_Mid_X445" SG_ 593 BsdOnOffState 0;
BA_ "GenSigTimeoutTime_HU_High_X445" SG_ 593 BsdOnOffState 0;
BA_ "GenSigTimeoutTime_HU_Mid_X445" SG_ 593 BsdOnOffState 0;
BA_ "GenSigTimeoutMsg_IVI" SG_ 593 BsdOnOffState 0;
BA_ "GenSigTimeoutTime_IVI" SG_ 593 BsdOnOffState 0;
BA_ "GenSigTimeoutTime_HU_Mid_X451" SG_ 593 BsdIndStatus 0;
BA_ "GenSigTimeoutTime_HU_High_X451" SG_ 593 BsdIndStatus 0;
BA_ "GenSigTimeoutTime_HU_B" SG_ 593 BsdIndStatus 0;
BA_ "GenSigTimeoutTime_HU_A" SG_ 593 BsdIndStatus 0;
BA_ "GenSigTimeoutMsg_HU_Mid_X451" SG_ 593 BsdIndStatus 0;
BA_ "GenSigTimeoutMsg_HU_High_X451" SG_ 593 BsdIndStatus 0;
BA_ "GenSigTimeoutMsg_HU_B" SG_ 593 BsdIndStatus 0;
BA_ "GenSigTimeoutMsg_HU_A" SG_ 593 BsdIndStatus 0;
BA_ "GenSigSendType" SG_ 593 BsdIndStatus 7;
BA_ "GenSigCycleTimeActive" SG_ 593 BsdIndStatus 100;
BA_ "GenSigCycleTime" SG_ 593 BsdIndStatus 100;
BA_ "GenSigTimeoutTime_HU_Mid_X451" SG_ 593 BsdIndRight 0;
BA_ "GenSigTimeoutTime_HU_High_X451" SG_ 593 BsdIndRight 0;
BA_ "GenSigTimeoutTime_HU_B" SG_ 593 BsdIndRight 0;
BA_ "GenSigTimeoutTime_HU_A" SG_ 593 BsdIndRight 0;
BA_ "GenSigTimeoutMsg_HU_Mid_X451" SG_ 593 BsdIndRight 0;
BA_ "GenSigTimeoutMsg_HU_High_X451" SG_ 593 BsdIndRight 0;
BA_ "GenSigTimeoutMsg_HU_B" SG_ 593 BsdIndRight 0;
BA_ "GenSigTimeoutMsg_HU_A" SG_ 593 BsdIndRight 0;
BA_ "GenSigSendType" SG_ 593 BsdIndRight 7;
BA_ "GenSigCycleTimeActive" SG_ 593 BsdIndRight 100;
BA_ "GenSigCycleTime" SG_ 593 BsdIndRight 100;
BA_ "GenSigTimeoutTime_HU_Mid_X451" SG_ 593 BsdIndLeft 0;
BA_ "GenSigTimeoutTime_HU_High_X451" SG_ 593 BsdIndLeft 0;
BA_ "GenSigTimeoutTime_HU_B" SG_ 593 BsdIndLeft 0;
BA_ "GenSigTimeoutTime_HU_A" SG_ 593 BsdIndLeft 0;
BA_ "GenSigTimeoutMsg_HU_Mid_X451" SG_ 593 BsdIndLeft 0;
BA_ "GenSigTimeoutMsg_HU_High_X451" SG_ 593 BsdIndLeft 0;
BA_ "GenSigTimeoutMsg_HU_B" SG_ 593 BsdIndLeft 0;
BA_ "GenSigTimeoutMsg_HU_A" SG_ 593 BsdIndLeft 0;
BA_ "GenSigSendType" SG_ 593 BsdIndLeft 7;
BA_ "GenSigCycleTimeActive" SG_ 593 BsdIndLeft 100;
BA_ "GenSigCycleTime" SG_ 593 BsdIndLeft 100;
BA_ "GenSigSendType" SG_ 593 DoaWarnRight 7;
BA_ "GenSigCycleTimeActive" SG_ 593 DoaWarnRight 100;
BA_ "GenSigCycleTime" SG_ 593 DoaWarnRight 100;
BA_ "GenSigTimeoutMsg_HU_High_X445" SG_ 593 DoaWarnRight 0;
BA_ "GenSigTimeoutMsg_HU_Mid_X445" SG_ 593 DoaWarnRight 0;
BA_ "GenSigTimeoutTime_HU_High_X445" SG_ 593 DoaWarnRight 0;
BA_ "GenSigTimeoutTime_HU_Mid_X445" SG_ 593 DoaWarnRight 0;
BA_ "GenSigTimeoutMsg_IVI" SG_ 593 DoaWarnRight 0;
BA_ "GenSigTimeoutTime_IVI" SG_ 593 DoaWarnRight 0;
BA_ "GenSigSendType" SG_ 593 DoaWarnLeft 7;
BA_ "GenSigCycleTimeActive" SG_ 593 DoaWarnLeft 100;
BA_ "GenSigCycleTime" SG_ 593 DoaWarnLeft 100;
BA_ "GenSigTimeoutMsg_HU_High_X445" SG_ 593 DoaWarnLeft 0;
BA_ "GenSigTimeoutMsg_HU_Mid_X445" SG_ 593 DoaWarnLeft 0;
BA_ "GenSigTimeoutTime_HU_High_X445" SG_ 593 DoaWarnLeft 0;
BA_ "GenSigTimeoutTime_HU_Mid_X445" SG_ 593 DoaWarnLeft 0;
BA_ "GenSigTimeoutMsg_IVI" SG_ 593 DoaWarnLeft 0;
BA_ "GenSigTimeoutTime_IVI" SG_ 593 DoaWarnLeft 0;
BA_ "GenSigTimeoutTime_HU_Mid_X451" SG_ 593 DoaStates 0;
BA_ "GenSigTimeoutTime_HU_High_X451" SG_ 593 DoaStates 0;
BA_ "GenSigTimeoutTime_HU_B" SG_ 593 DoaStates 0;
BA_ "GenSigTimeoutTime_HU_A" SG_ 593 DoaStates 0;
BA_ "GenSigTimeoutMsg_HU_Mid_X451" SG_ 593 DoaStates 0;
BA_ "GenSigTimeoutMsg_HU_High_X451" SG_ 593 DoaStates 0;
BA_ "GenSigTimeoutMsg_HU_B" SG_ 593 DoaStates 0;
BA_ "GenSigTimeoutMsg_HU_A" SG_ 593 DoaStates 0;
BA_ "GenSigSendType" SG_ 593 DoaStates 7;
BA_ "GenSigCycleTimeActive" SG_ 593 DoaStates 100;
BA_ "GenSigCycleTime" SG_ 593 DoaStates 100;
BA_ "GenSigStartValue" SG_ 593 DoaOnOffState 1;
BA_ "GenSigSendType" SG_ 593 DoaOnOffState 7;
BA_ "GenSigCycleTimeActive" SG_ 593 DoaOnOffState 100;
BA_ "GenSigCycleTime" SG_ 593 DoaOnOffState 100;
BA_ "GenSigTimeoutMsg_HU_High_X445" SG_ 593 DoaOnOffState 0;
BA_ "GenSigTimeoutMsg_HU_Mid_X445" SG_ 593 DoaOnOffState 0;
BA_ "GenSigTimeoutTime_HU_High_X445" SG_ 593 DoaOnOffState 0;
BA_ "GenSigTimeoutTime_HU_Mid_X445" SG_ 593 DoaOnOffState 0;
BA_ "GenSigTimeoutMsg_IVI" SG_ 593 DoaOnOffState 0;
BA_ "GenSigTimeoutTime_IVI" SG_ 593 DoaOnOffState 0;
BA_ "GenSigTimeoutTime_HU_Mid_X451" SG_ 1291 ActiveWakeUp_SRR 1000;
BA_ "GenSigTimeoutTime_HU_High_X451" SG_ 1291 ActiveWakeUp_SRR 1000;
BA_ "GenSigTimeoutTime_HU_B" SG_ 1291 ActiveWakeUp_SRR 1000;
BA_ "GenSigTimeoutTime_HU_A" SG_ 1291 ActiveWakeUp_SRR 1000;
BA_ "GenSigTimeoutMsg_HU_Mid_X451" SG_ 1291 ActiveWakeUp_SRR 1000;
BA_ "GenSigTimeoutMsg_HU_High_X451" SG_ 1291 ActiveWakeUp_SRR 1000;
BA_ "GenSigTimeoutMsg_HU_B" SG_ 1291 ActiveWakeUp_SRR 1000;
BA_ "GenSigTimeoutMsg_HU_A" SG_ 1291 ActiveWakeUp_SRR 1000;
BA_ "GenSigSendType" SG_ 1291 ActiveWakeUp_SRR 7;
BA_ "GenSigCycleTimeActive" SG_ 1291 ActiveWakeUp_SRR 200;
BA_ "GenSigCycleTime" SG_ 1291 ActiveWakeUp_SRR 200;
BA_ "GenSigTimeoutMsg_HU_High_X445" SG_ 1291 ActiveWakeUp_SRR 1000;
BA_ "GenSigTimeoutMsg_HU_Mid_X445" SG_ 1291 ActiveWakeUp_SRR 1000;
BA_ "GenSigTimeoutTime_HU_High_X445" SG_ 1291 ActiveWakeUp_SRR 1000;
BA_ "GenSigTimeoutTime_HU_Mid_X445" SG_ 1291 ActiveWakeUp_SRR 1000;
BA_ "GenSigTimeoutMsg_IVI" SG_ 1291 ActiveWakeUp_SRR 1000;
BA_ "GenSigTimeoutTime_IVI" SG_ 1291 ActiveWakeUp_SRR 1000;
BA_ "GenSigTimeoutTime_HU_Mid_X451" SG_ 1291 CurrentState_SRR 1000;
BA_ "GenSigTimeoutTime_HU_High_X451" SG_ 1291 CurrentState_SRR 1000;
BA_ "GenSigTimeoutTime_HU_B" SG_ 1291 CurrentState_SRR 1000;
BA_ "GenSigTimeoutTime_HU_A" SG_ 1291 CurrentState_SRR 1000;
BA_ "GenSigTimeoutMsg_HU_Mid_X451" SG_ 1291 CurrentState_SRR 1000;
BA_ "GenSigTimeoutMsg_HU_High_X451" SG_ 1291 CurrentState_SRR 1000;
BA_ "GenSigTimeoutMsg_HU_B" SG_ 1291 CurrentState_SRR 1000;
BA_ "GenSigTimeoutMsg_HU_A" SG_ 1291 CurrentState_SRR 1000;
BA_ "GenSigSendType" SG_ 1291 CurrentState_SRR 7;
BA_ "GenSigCycleTimeActive" SG_ 1291 CurrentState_SRR 200;
BA_ "GenSigCycleTime" SG_ 1291 CurrentState_SRR 200;
BA_ "GenSigTimeoutMsg_HU_High_X445" SG_ 1291 CurrentState_SRR 1000;
BA_ "GenSigTimeoutMsg_HU_Mid_X445" SG_ 1291 CurrentState_SRR 1000;
BA_ "GenSigTimeoutTime_HU_High_X445" SG_ 1291 CurrentState_SRR 1000;
BA_ "GenSigTimeoutTime_HU_Mid_X445" SG_ 1291 CurrentState_SRR 1000;
BA_ "GenSigTimeoutMsg_IVI" SG_ 1291 CurrentState_SRR 1000;
BA_ "GenSigTimeoutTime_IVI" SG_ 1291 CurrentState_SRR 1000;
BA_ "GenSigTimeoutTime_HU_Mid_X451" SG_ 1291 NMCoOrdSlpReady_SRR 1000;
BA_ "GenSigTimeoutTime_HU_High_X451" SG_ 1291 NMCoOrdSlpReady_SRR 1000;
BA_ "GenSigTimeoutTime_HU_B" SG_ 1291 NMCoOrdSlpReady_SRR 1000;
BA_ "GenSigTimeoutTime_HU_A" SG_ 1291 NMCoOrdSlpReady_SRR 1000;
BA_ "GenSigTimeoutMsg_HU_Mid_X451" SG_ 1291 NMCoOrdSlpReady_SRR 1000;
BA_ "GenSigTimeoutMsg_HU_High_X451" SG_ 1291 NMCoOrdSlpReady_SRR 1000;
BA_ "GenSigTimeoutMsg_HU_B" SG_ 1291 NMCoOrdSlpReady_SRR 1000;
BA_ "GenSigTimeoutMsg_HU_A" SG_ 1291 NMCoOrdSlpReady_SRR 1000;
BA_ "GenSigSendType" SG_ 1291 NMCoOrdSlpReady_SRR 7;
BA_ "GenSigCycleTimeActive" SG_ 1291 NMCoOrdSlpReady_SRR 200;
BA_ "GenSigCycleTime" SG_ 1291 NMCoOrdSlpReady_SRR 200;
BA_ "GenSigTimeoutMsg_HU_High_X445" SG_ 1291 NMCoOrdSlpReady_SRR 1000;
BA_ "GenSigTimeoutMsg_HU_Mid_X445" SG_ 1291 NMCoOrdSlpReady_SRR 1000;
BA_ "GenSigTimeoutTime_HU_High_X445" SG_ 1291 NMCoOrdSlpReady_SRR 1000;
BA_ "GenSigTimeoutTime_HU_Mid_X445" SG_ 1291 NMCoOrdSlpReady_SRR 1000;
BA_ "GenSigTimeoutMsg_IVI" SG_ 1291 NMCoOrdSlpReady_SRR 1000;
BA_ "GenSigTimeoutTime_IVI" SG_ 1291 NMCoOrdSlpReady_SRR 1000;
BA_ "GenSigTimeoutTime_HU_Mid_X451" SG_ 1291 PartialNetworkInformation_SRR 1000;
BA_ "GenSigTimeoutTime_HU_High_X451" SG_ 1291 PartialNetworkInformation_SRR 1000;
BA_ "GenSigTimeoutTime_HU_B" SG_ 1291 PartialNetworkInformation_SRR 1000;
BA_ "GenSigTimeoutTime_HU_A" SG_ 1291 PartialNetworkInformation_SRR 1000;
BA_ "GenSigTimeoutMsg_HU_Mid_X451" SG_ 1291 PartialNetworkInformation_SRR 1000;
BA_ "GenSigTimeoutMsg_HU_High_X451" SG_ 1291 PartialNetworkInformation_SRR 1000;
BA_ "GenSigTimeoutMsg_HU_B" SG_ 1291 PartialNetworkInformation_SRR 1000;
BA_ "GenSigTimeoutMsg_HU_A" SG_ 1291 PartialNetworkInformation_SRR 1000;
BA_ "GenSigSendType" SG_ 1291 PartialNetworkInformation_SRR 7;
BA_ "GenSigCycleTimeActive" SG_ 1291 PartialNetworkInformation_SRR 200;
BA_ "GenSigCycleTime" SG_ 1291 PartialNetworkInformation_SRR 200;
BA_ "GenSigTimeoutMsg_HU_High_X445" SG_ 1291 PartialNetworkInformation_SRR 1000;
BA_ "GenSigTimeoutMsg_HU_Mid_X445" SG_ 1291 PartialNetworkInformation_SRR 1000;
BA_ "GenSigTimeoutTime_HU_High_X445" SG_ 1291 PartialNetworkInformation_SRR 1000;
BA_ "GenSigTimeoutTime_HU_Mid_X445" SG_ 1291 PartialNetworkInformation_SRR 1000;
BA_ "GenSigTimeoutMsg_IVI" SG_ 1291 PartialNetworkInformation_SRR 1000;
BA_ "GenSigTimeoutTime_IVI" SG_ 1291 PartialNetworkInformation_SRR 1000;
BA_ "GenSigTimeoutTime_HU_Mid_X451" SG_ 1291 PreviousState_SRR 1000;
BA_ "GenSigTimeoutTime_HU_High_X451" SG_ 1291 PreviousState_SRR 1000;
BA_ "GenSigTimeoutTime_HU_B" SG_ 1291 PreviousState_SRR 1000;
BA_ "GenSigTimeoutTime_HU_A" SG_ 1291 PreviousState_SRR 1000;
BA_ "GenSigTimeoutMsg_HU_Mid_X451" SG_ 1291 PreviousState_SRR 1000;
BA_ "GenSigTimeoutMsg_HU_High_X451" SG_ 1291 PreviousState_SRR 1000;
BA_ "GenSigTimeoutMsg_HU_B" SG_ 1291 PreviousState_SRR 1000;
BA_ "GenSigTimeoutMsg_HU_A" SG_ 1291 PreviousState_SRR 1000;
BA_ "GenSigSendType" SG_ 1291 PreviousState_SRR 7;
BA_ "GenSigCycleTimeActive" SG_ 1291 PreviousState_SRR 200;
BA_ "GenSigCycleTime" SG_ 1291 PreviousState_SRR 200;
BA_ "GenSigTimeoutMsg_HU_High_X445" SG_ 1291 PreviousState_SRR 1000;
BA_ "GenSigTimeoutMsg_HU_Mid_X445" SG_ 1291 PreviousState_SRR 1000;
BA_ "GenSigTimeoutTime_HU_High_X445" SG_ 1291 PreviousState_SRR 1000;
BA_ "GenSigTimeoutTime_HU_Mid_X445" SG_ 1291 PreviousState_SRR 1000;
BA_ "GenSigTimeoutMsg_IVI" SG_ 1291 PreviousState_SRR 1000;
BA_ "GenSigTimeoutTime_IVI" SG_ 1291 PreviousState_SRR 1000;
BA_ "GenSigTimeoutTime_HU_B" SG_ 1291 RepeatMessageReq_SRR 0;
BA_ "GenSigTimeoutTime_HU_A" SG_ 1291 RepeatMessageReq_SRR 0;
BA_ "GenSigTimeoutMsg_HU_B" SG_ 1291 RepeatMessageReq_SRR 0;
BA_ "GenSigTimeoutMsg_HU_A" SG_ 1291 RepeatMessageReq_SRR 0;
BA_ "GenSigSendType" SG_ 1291 RepeatMessageReq_SRR 7;
BA_ "GenSigCycleTimeActive" SG_ 1291 RepeatMessageReq_SRR 200;
BA_ "GenSigCycleTime" SG_ 1291 RepeatMessageReq_SRR 200;
BA_ "GenSigTimeoutTime_HU_Mid_X451" SG_ 1291 Reserved71 0;
BA_ "GenSigTimeoutTime_HU_High_X451" SG_ 1291 Reserved71 0;
BA_ "GenSigTimeoutTime_HU_B" SG_ 1291 Reserved71 0;
BA_ "GenSigTimeoutTime_HU_A" SG_ 1291 Reserved71 0;
BA_ "GenSigTimeoutMsg_HU_Mid_X451" SG_ 1291 Reserved71 0;
BA_ "GenSigTimeoutMsg_HU_High_X451" SG_ 1291 Reserved71 0;
BA_ "GenSigTimeoutMsg_HU_B" SG_ 1291 Reserved71 0;
BA_ "GenSigTimeoutMsg_HU_A" SG_ 1291 Reserved71 0;
BA_ "GenSigSendType" SG_ 1291 Reserved71 7;
BA_ "GenSigCycleTimeActive" SG_ 1291 Reserved71 200;
BA_ "GenSigCycleTime" SG_ 1291 Reserved71 200;
BA_ "GenSigTimeoutTime_HU_Mid_X451" SG_ 1291 Reserved70 0;
BA_ "GenSigTimeoutTime_HU_High_X451" SG_ 1291 Reserved70 0;
BA_ "GenSigTimeoutTime_HU_B" SG_ 1291 Reserved70 0;
BA_ "GenSigTimeoutTime_HU_A" SG_ 1291 Reserved70 0;
BA_ "GenSigTimeoutMsg_HU_Mid_X451" SG_ 1291 Reserved70 0;
BA_ "GenSigTimeoutMsg_HU_High_X451" SG_ 1291 Reserved70 0;
BA_ "GenSigTimeoutMsg_HU_B" SG_ 1291 Reserved70 0;
BA_ "GenSigTimeoutMsg_HU_A" SG_ 1291 Reserved70 0;
BA_ "GenSigSendType" SG_ 1291 Reserved70 7;
BA_ "GenSigCycleTimeActive" SG_ 1291 Reserved70 200;
BA_ "GenSigCycleTime" SG_ 1291 Reserved70 200;
BA_ "GenSigTimeoutTime_HU_Mid_X451" SG_ 1291 Reserved69 0;
BA_ "GenSigTimeoutTime_HU_High_X451" SG_ 1291 Reserved69 0;
BA_ "GenSigTimeoutTime_HU_B" SG_ 1291 Reserved69 0;
BA_ "GenSigTimeoutTime_HU_A" SG_ 1291 Reserved69 0;
BA_ "GenSigTimeoutMsg_HU_Mid_X451" SG_ 1291 Reserved69 0;
BA_ "GenSigTimeoutMsg_HU_High_X451" SG_ 1291 Reserved69 0;
BA_ "GenSigTimeoutMsg_HU_B" SG_ 1291 Reserved69 0;
BA_ "GenSigTimeoutMsg_HU_A" SG_ 1291 Reserved69 0;
BA_ "GenSigSendType" SG_ 1291 Reserved69 7;
BA_ "GenSigCycleTimeActive" SG_ 1291 Reserved69 200;
BA_ "GenSigCycleTime" SG_ 1291 Reserved69 200;
BA_ "GenSigTimeoutTime_HU_Mid_X451" SG_ 1291 Reserved68 0;
BA_ "GenSigTimeoutTime_HU_High_X451" SG_ 1291 Reserved68 0;
BA_ "GenSigTimeoutTime_HU_B" SG_ 1291 Reserved68 0;
BA_ "GenSigTimeoutTime_HU_A" SG_ 1291 Reserved68 0;
BA_ "GenSigTimeoutMsg_HU_Mid_X451" SG_ 1291 Reserved68 0;
BA_ "GenSigTimeoutMsg_HU_High_X451" SG_ 1291 Reserved68 0;
BA_ "GenSigTimeoutMsg_HU_B" SG_ 1291 Reserved68 0;
BA_ "GenSigTimeoutMsg_HU_A" SG_ 1291 Reserved68 0;
BA_ "GenSigSendType" SG_ 1291 Reserved68 7;
BA_ "GenSigCycleTimeActive" SG_ 1291 Reserved68 200;
BA_ "GenSigCycleTime" SG_ 1291 Reserved68 200;
BA_ "GenSigTimeoutTime_HU_Mid_X451" SG_ 1291 Reserved67 0;
BA_ "GenSigTimeoutTime_HU_High_X451" SG_ 1291 Reserved67 0;
BA_ "GenSigTimeoutTime_HU_B" SG_ 1291 Reserved67 0;
BA_ "GenSigTimeoutTime_HU_A" SG_ 1291 Reserved67 0;
BA_ "GenSigTimeoutMsg_HU_Mid_X451" SG_ 1291 Reserved67 0;
BA_ "GenSigTimeoutMsg_HU_High_X451" SG_ 1291 Reserved67 0;
BA_ "GenSigTimeoutMsg_HU_B" SG_ 1291 Reserved67 0;
BA_ "GenSigTimeoutMsg_HU_A" SG_ 1291 Reserved67 0;
BA_ "GenSigSendType" SG_ 1291 Reserved67 7;
BA_ "GenSigCycleTimeActive" SG_ 1291 Reserved67 200;
BA_ "GenSigCycleTime" SG_ 1291 Reserved67 200;
BA_ "GenSigTimeoutTime_HU_Mid_X451" SG_ 1291 Reserved66 0;
BA_ "GenSigTimeoutTime_HU_High_X451" SG_ 1291 Reserved66 0;
BA_ "GenSigTimeoutTime_HU_B" SG_ 1291 Reserved66 0;
BA_ "GenSigTimeoutTime_HU_A" SG_ 1291 Reserved66 0;
BA_ "GenSigTimeoutMsg_HU_Mid_X451" SG_ 1291 Reserved66 0;
BA_ "GenSigTimeoutMsg_HU_High_X451" SG_ 1291 Reserved66 0;
BA_ "GenSigTimeoutMsg_HU_B" SG_ 1291 Reserved66 0;
BA_ "GenSigTimeoutMsg_HU_A" SG_ 1291 Reserved66 0;
BA_ "GenSigSendType" SG_ 1291 Reserved66 7;
BA_ "GenSigCycleTimeActive" SG_ 1291 Reserved66 200;
BA_ "GenSigCycleTime" SG_ 1291 Reserved66 200;
BA_ "GenSigTimeoutTime_HU_Mid_X451" SG_ 1291 Reserved65 0;
BA_ "GenSigTimeoutTime_HU_High_X451" SG_ 1291 Reserved65 0;
BA_ "GenSigTimeoutTime_HU_B" SG_ 1291 Reserved65 0;
BA_ "GenSigTimeoutTime_HU_A" SG_ 1291 Reserved65 0;
BA_ "GenSigTimeoutMsg_HU_Mid_X451" SG_ 1291 Reserved65 0;
BA_ "GenSigTimeoutMsg_HU_High_X451" SG_ 1291 Reserved65 0;
BA_ "GenSigTimeoutMsg_HU_B" SG_ 1291 Reserved65 0;
BA_ "GenSigTimeoutMsg_HU_A" SG_ 1291 Reserved65 0;
BA_ "GenSigSendType" SG_ 1291 Reserved65 7;
BA_ "GenSigCycleTimeActive" SG_ 1291 Reserved65 200;
BA_ "GenSigCycleTime" SG_ 1291 Reserved65 200;
BA_ "GenSigTimeoutTime_HU_Mid_X451" SG_ 1291 Reserved64 0;
BA_ "GenSigTimeoutTime_HU_High_X451" SG_ 1291 Reserved64 0;
BA_ "GenSigTimeoutTime_HU_B" SG_ 1291 Reserved64 0;
BA_ "GenSigTimeoutTime_HU_A" SG_ 1291 Reserved64 0;
BA_ "GenSigTimeoutMsg_HU_Mid_X451" SG_ 1291 Reserved64 0;
BA_ "GenSigTimeoutMsg_HU_High_X451" SG_ 1291 Reserved64 0;
BA_ "GenSigTimeoutMsg_HU_B" SG_ 1291 Reserved64 0;
BA_ "GenSigTimeoutMsg_HU_A" SG_ 1291 Reserved64 0;
BA_ "GenSigSendType" SG_ 1291 Reserved64 7;
BA_ "GenSigCycleTimeActive" SG_ 1291 Reserved64 200;
BA_ "GenSigCycleTime" SG_ 1291 Reserved64 200;
BA_ "GenSigTimeoutTime_HU_Mid_X451" SG_ 1291 SRR_NMPDU_USER_DATA_D5 1000;
BA_ "GenSigTimeoutTime_HU_High_X451" SG_ 1291 SRR_NMPDU_USER_DATA_D5 1000;
BA_ "GenSigTimeoutTime_HU_B" SG_ 1291 SRR_NMPDU_USER_DATA_D5 1000;
BA_ "GenSigTimeoutTime_HU_A" SG_ 1291 SRR_NMPDU_USER_DATA_D5 1000;
BA_ "GenSigTimeoutMsg_HU_Mid_X451" SG_ 1291 SRR_NMPDU_USER_DATA_D5 1000;
BA_ "GenSigTimeoutMsg_HU_High_X451" SG_ 1291 SRR_NMPDU_USER_DATA_D5 1000;
BA_ "GenSigTimeoutMsg_HU_B" SG_ 1291 SRR_NMPDU_USER_DATA_D5 1000;
BA_ "GenSigTimeoutMsg_HU_A" SG_ 1291 SRR_NMPDU_USER_DATA_D5 1000;
BA_ "GenSigSendType" SG_ 1291 SRR_NMPDU_USER_DATA_D5 7;
BA_ "GenSigCycleTimeActive" SG_ 1291 SRR_NMPDU_USER_DATA_D5 200;
BA_ "GenSigCycleTime" SG_ 1291 SRR_NMPDU_USER_DATA_D5 200;
BA_ "GenSigTimeoutMsg_HU_High_X445" SG_ 1291 SRR_NMPDU_USER_DATA_D5 1000;
BA_ "GenSigTimeoutMsg_HU_Mid_X445" SG_ 1291 SRR_NMPDU_USER_DATA_D5 1000;
BA_ "GenSigTimeoutTime_HU_High_X445" SG_ 1291 SRR_NMPDU_USER_DATA_D5 1000;
BA_ "GenSigTimeoutTime_HU_Mid_X445" SG_ 1291 SRR_NMPDU_USER_DATA_D5 1000;
BA_ "GenSigTimeoutMsg_IVI" SG_ 1291 SRR_NMPDU_USER_DATA_D5 1000;
BA_ "GenSigTimeoutTime_IVI" SG_ 1291 SRR_NMPDU_USER_DATA_D5 1000;
BA_ "GenSigTimeoutTime_HU_Mid_X451" SG_ 1291 SRR_NMPDU_USER_DATA_D4 1000;
BA_ "GenSigTimeoutTime_HU_High_X451" SG_ 1291 SRR_NMPDU_USER_DATA_D4 1000;
BA_ "GenSigTimeoutTime_HU_B" SG_ 1291 SRR_NMPDU_USER_DATA_D4 1000;
BA_ "GenSigTimeoutTime_HU_A" SG_ 1291 SRR_NMPDU_USER_DATA_D4 1000;
BA_ "GenSigTimeoutMsg_HU_Mid_X451" SG_ 1291 SRR_NMPDU_USER_DATA_D4 1000;
BA_ "GenSigTimeoutMsg_HU_High_X451" SG_ 1291 SRR_NMPDU_USER_DATA_D4 1000;
BA_ "GenSigTimeoutMsg_HU_B" SG_ 1291 SRR_NMPDU_USER_DATA_D4 1000;
BA_ "GenSigTimeoutMsg_HU_A" SG_ 1291 SRR_NMPDU_USER_DATA_D4 1000;
BA_ "GenSigSendType" SG_ 1291 SRR_NMPDU_USER_DATA_D4 7;
BA_ "GenSigCycleTimeActive" SG_ 1291 SRR_NMPDU_USER_DATA_D4 200;
BA_ "GenSigCycleTime" SG_ 1291 SRR_NMPDU_USER_DATA_D4 200;
BA_ "GenSigTimeoutMsg_HU_High_X445" SG_ 1291 SRR_NMPDU_USER_DATA_D4 1000;
BA_ "GenSigTimeoutMsg_HU_Mid_X445" SG_ 1291 SRR_NMPDU_USER_DATA_D4 1000;
BA_ "GenSigTimeoutTime_HU_High_X445" SG_ 1291 SRR_NMPDU_USER_DATA_D4 1000;
BA_ "GenSigTimeoutTime_HU_Mid_X445" SG_ 1291 SRR_NMPDU_USER_DATA_D4 1000;
BA_ "GenSigTimeoutMsg_IVI" SG_ 1291 SRR_NMPDU_USER_DATA_D4 1000;
BA_ "GenSigTimeoutTime_IVI" SG_ 1291 SRR_NMPDU_USER_DATA_D4 1000;
BA_ "GenSigTimeoutTime_HU_Mid_X451" SG_ 1291 SRR_NMPDU_USER_DATA_D3 1000;
BA_ "GenSigTimeoutTime_HU_High_X451" SG_ 1291 SRR_NMPDU_USER_DATA_D3 1000;
BA_ "GenSigTimeoutTime_HU_B" SG_ 1291 SRR_NMPDU_USER_DATA_D3 1000;
BA_ "GenSigTimeoutTime_HU_A" SG_ 1291 SRR_NMPDU_USER_DATA_D3 1000;
BA_ "GenSigTimeoutMsg_HU_Mid_X451" SG_ 1291 SRR_NMPDU_USER_DATA_D3 1000;
BA_ "GenSigTimeoutMsg_HU_High_X451" SG_ 1291 SRR_NMPDU_USER_DATA_D3 1000;
BA_ "GenSigTimeoutMsg_HU_B" SG_ 1291 SRR_NMPDU_USER_DATA_D3 1000;
BA_ "GenSigTimeoutMsg_HU_A" SG_ 1291 SRR_NMPDU_USER_DATA_D3 1000;
BA_ "GenSigSendType" SG_ 1291 SRR_NMPDU_USER_DATA_D3 7;
BA_ "GenSigCycleTimeActive" SG_ 1291 SRR_NMPDU_USER_DATA_D3 200;
BA_ "GenSigCycleTime" SG_ 1291 SRR_NMPDU_USER_DATA_D3 200;
BA_ "GenSigTimeoutMsg_HU_High_X445" SG_ 1291 SRR_NMPDU_USER_DATA_D3 1000;
BA_ "GenSigTimeoutMsg_HU_Mid_X445" SG_ 1291 SRR_NMPDU_USER_DATA_D3 1000;
BA_ "GenSigTimeoutTime_HU_High_X445" SG_ 1291 SRR_NMPDU_USER_DATA_D3 1000;
BA_ "GenSigTimeoutTime_HU_Mid_X445" SG_ 1291 SRR_NMPDU_USER_DATA_D3 1000;
BA_ "GenSigTimeoutMsg_IVI" SG_ 1291 SRR_NMPDU_USER_DATA_D3 1000;
BA_ "GenSigTimeoutTime_IVI" SG_ 1291 SRR_NMPDU_USER_DATA_D3 1000;
BA_ "GenSigTimeoutTime_HU_Mid_X451" SG_ 1291 SRR_NMPDU_USER_DATA_D2 1000;
BA_ "GenSigTimeoutTime_HU_High_X451" SG_ 1291 SRR_NMPDU_USER_DATA_D2 1000;
BA_ "GenSigTimeoutTime_HU_B" SG_ 1291 SRR_NMPDU_USER_DATA_D2 1000;
BA_ "GenSigTimeoutTime_HU_A" SG_ 1291 SRR_NMPDU_USER_DATA_D2 1000;
BA_ "GenSigTimeoutMsg_HU_Mid_X451" SG_ 1291 SRR_NMPDU_USER_DATA_D2 1000;
BA_ "GenSigTimeoutMsg_HU_High_X451" SG_ 1291 SRR_NMPDU_USER_DATA_D2 1000;
BA_ "GenSigTimeoutMsg_HU_B" SG_ 1291 SRR_NMPDU_USER_DATA_D2 1000;
BA_ "GenSigTimeoutMsg_HU_A" SG_ 1291 SRR_NMPDU_USER_DATA_D2 1000;
BA_ "GenSigSendType" SG_ 1291 SRR_NMPDU_USER_DATA_D2 7;
BA_ "GenSigCycleTimeActive" SG_ 1291 SRR_NMPDU_USER_DATA_D2 200;
BA_ "GenSigCycleTime" SG_ 1291 SRR_NMPDU_USER_DATA_D2 200;
BA_ "GenSigTimeoutMsg_HU_High_X445" SG_ 1291 SRR_NMPDU_USER_DATA_D2 1000;
BA_ "GenSigTimeoutMsg_HU_Mid_X445" SG_ 1291 SRR_NMPDU_USER_DATA_D2 1000;
BA_ "GenSigTimeoutTime_HU_High_X445" SG_ 1291 SRR_NMPDU_USER_DATA_D2 1000;
BA_ "GenSigTimeoutTime_HU_Mid_X445" SG_ 1291 SRR_NMPDU_USER_DATA_D2 1000;
BA_ "GenSigTimeoutMsg_IVI" SG_ 1291 SRR_NMPDU_USER_DATA_D2 1000;
BA_ "GenSigTimeoutTime_IVI" SG_ 1291 SRR_NMPDU_USER_DATA_D2 1000;
BA_ "GenSigTimeoutTime_HU_Mid_X451" SG_ 1291 SRR_NMPDU_USER_DATA_D1 1000;
BA_ "GenSigTimeoutTime_HU_High_X451" SG_ 1291 SRR_NMPDU_USER_DATA_D1 1000;
BA_ "GenSigTimeoutTime_HU_B" SG_ 1291 SRR_NMPDU_USER_DATA_D1 1000;
BA_ "GenSigTimeoutTime_HU_A" SG_ 1291 SRR_NMPDU_USER_DATA_D1 1000;
BA_ "GenSigTimeoutMsg_HU_Mid_X451" SG_ 1291 SRR_NMPDU_USER_DATA_D1 1000;
BA_ "GenSigTimeoutMsg_HU_High_X451" SG_ 1291 SRR_NMPDU_USER_DATA_D1 1000;
BA_ "GenSigTimeoutMsg_HU_B" SG_ 1291 SRR_NMPDU_USER_DATA_D1 1000;
BA_ "GenSigTimeoutMsg_HU_A" SG_ 1291 SRR_NMPDU_USER_DATA_D1 1000;
BA_ "GenSigSendType" SG_ 1291 SRR_NMPDU_USER_DATA_D1 7;
BA_ "GenSigCycleTimeActive" SG_ 1291 SRR_NMPDU_USER_DATA_D1 200;
BA_ "GenSigCycleTime" SG_ 1291 SRR_NMPDU_USER_DATA_D1 200;
BA_ "GenSigTimeoutMsg_HU_High_X445" SG_ 1291 SRR_NMPDU_USER_DATA_D1 1000;
BA_ "GenSigTimeoutMsg_HU_Mid_X445" SG_ 1291 SRR_NMPDU_USER_DATA_D1 1000;
BA_ "GenSigTimeoutTime_HU_High_X445" SG_ 1291 SRR_NMPDU_USER_DATA_D1 1000;
BA_ "GenSigTimeoutTime_HU_Mid_X445" SG_ 1291 SRR_NMPDU_USER_DATA_D1 1000;
BA_ "GenSigTimeoutMsg_IVI" SG_ 1291 SRR_NMPDU_USER_DATA_D1 1000;
BA_ "GenSigTimeoutTime_IVI" SG_ 1291 SRR_NMPDU_USER_DATA_D1 1000;
BA_ "GenSigTimeoutTime_HU_Mid_X451" SG_ 1291 SRR_NMPDU_SRC_ECU_ID 1000;
BA_ "GenSigTimeoutTime_HU_High_X451" SG_ 1291 SRR_NMPDU_SRC_ECU_ID 1000;
BA_ "GenSigTimeoutTime_HU_B" SG_ 1291 SRR_NMPDU_SRC_ECU_ID 1000;
BA_ "GenSigTimeoutTime_HU_A" SG_ 1291 SRR_NMPDU_SRC_ECU_ID 1000;
BA_ "GenSigTimeoutMsg_HU_Mid_X451" SG_ 1291 SRR_NMPDU_SRC_ECU_ID 1000;
BA_ "GenSigTimeoutMsg_HU_High_X451" SG_ 1291 SRR_NMPDU_SRC_ECU_ID 1000;
BA_ "GenSigTimeoutMsg_HU_B" SG_ 1291 SRR_NMPDU_SRC_ECU_ID 1000;
BA_ "GenSigTimeoutMsg_HU_A" SG_ 1291 SRR_NMPDU_SRC_ECU_ID 1000;
BA_ "GenSigSendType" SG_ 1291 SRR_NMPDU_SRC_ECU_ID 7;
BA_ "GenSigCycleTimeActive" SG_ 1291 SRR_NMPDU_SRC_ECU_ID 200;
BA_ "GenSigCycleTime" SG_ 1291 SRR_NMPDU_SRC_ECU_ID 200;
BA_ "GenSigTimeoutMsg_HU_High_X445" SG_ 1291 SRR_NMPDU_SRC_ECU_ID 1000;
BA_ "GenSigTimeoutMsg_HU_Mid_X445" SG_ 1291 SRR_NMPDU_SRC_ECU_ID 1000;
BA_ "GenSigTimeoutTime_HU_High_X445" SG_ 1291 SRR_NMPDU_SRC_ECU_ID 1000;
BA_ "GenSigTimeoutTime_HU_Mid_X445" SG_ 1291 SRR_NMPDU_SRC_ECU_ID 1000;
BA_ "GenSigTimeoutMsg_IVI" SG_ 1291 SRR_NMPDU_SRC_ECU_ID 1000;
BA_ "GenSigTimeoutTime_IVI" SG_ 1291 SRR_NMPDU_SRC_ECU_ID 1000;
BA_ "GenSigTimeoutTime_HU_Mid_X451" SG_ 468 PotSwRkeOnOffReq 0;
BA_ "GenSigTimeoutTime_HU_High_X451" SG_ 468 PotSwRkeOnOffReq 0;
BA_ "GenSigTimeoutTime_HU_B" SG_ 468 PotSwRkeOnOffReq 0;
BA_ "GenSigTimeoutTime_HU_A" SG_ 468 PotSwRkeOnOffReq 0;
BA_ "GenSigTimeoutMsg_HU_Mid_X451" SG_ 468 PotSwRkeOnOffReq 0;
BA_ "GenSigTimeoutMsg_HU_High_X451" SG_ 468 PotSwRkeOnOffReq 0;
BA_ "GenSigTimeoutMsg_HU_B" SG_ 468 PotSwRkeOnOffReq 0;
BA_ "GenSigTimeoutMsg_HU_A" SG_ 468 PotSwRkeOnOffReq 0;
BA_ "GenSigSendType" SG_ 468 PotSwRkeOnOffReq 2;
BA_ "GenSigTimeoutMsg_HU_High_X445" SG_ 468 PotSwRkeOnOffReq 0;
BA_ "GenSigTimeoutMsg_HU_Mid_X445" SG_ 468 PotSwRkeOnOffReq 0;
BA_ "GenSigTimeoutTime_HU_High_X445" SG_ 468 PotSwRkeOnOffReq 0;
BA_ "GenSigTimeoutTime_HU_Mid_X445" SG_ 468 PotSwRkeOnOffReq 0;
BA_ "GenSigTimeoutMsg_IVI" SG_ 468 PotSwRkeOnOffReq 0;
BA_ "GenSigTimeoutTime_IVI" SG_ 468 PotSwRkeOnOffReq 0;
BA_ "GenSigTimeoutTime_HU_Mid_X451" SG_ 468 PotHeightAdjReq 0;
BA_ "GenSigTimeoutTime_HU_High_X451" SG_ 468 PotHeightAdjReq 0;
BA_ "GenSigTimeoutTime_HU_B" SG_ 468 PotHeightAdjReq 0;
BA_ "GenSigTimeoutTime_HU_A" SG_ 468 PotHeightAdjReq 0;
BA_ "GenSigTimeoutMsg_HU_Mid_X451" SG_ 468 PotHeightAdjReq 0;
BA_ "GenSigTimeoutMsg_HU_High_X451" SG_ 468 PotHeightAdjReq 0;
BA_ "GenSigTimeoutMsg_HU_B" SG_ 468 PotHeightAdjReq 0;
BA_ "GenSigTimeoutMsg_HU_A" SG_ 468 PotHeightAdjReq 0;
BA_ "GenSigSendType" SG_ 468 PotHeightAdjReq 2;
BA_ "GenSigTimeoutMsg_HU_High_X445" SG_ 468 PotHeightAdjReq 0;
BA_ "GenSigTimeoutMsg_HU_Mid_X445" SG_ 468 PotHeightAdjReq 0;
BA_ "GenSigTimeoutTime_HU_High_X445" SG_ 468 PotHeightAdjReq 0;
BA_ "GenSigTimeoutTime_HU_Mid_X445" SG_ 468 PotHeightAdjReq 0;
BA_ "GenSigTimeoutMsg_IVI" SG_ 468 PotHeightAdjReq 0;
BA_ "GenSigTimeoutTime_IVI" SG_ 468 PotHeightAdjReq 0;
BA_ "GenSigTimeoutTime_HU_Mid_X451" SG_ 468 PotGestOnOffReq 0;
BA_ "GenSigTimeoutTime_HU_High_X451" SG_ 468 PotGestOnOffReq 0;
BA_ "GenSigTimeoutTime_HU_B" SG_ 468 PotGestOnOffReq 0;
BA_ "GenSigTimeoutTime_HU_A" SG_ 468 PotGestOnOffReq 0;
BA_ "GenSigTimeoutMsg_HU_Mid_X451" SG_ 468 PotGestOnOffReq 0;
BA_ "GenSigTimeoutMsg_HU_High_X451" SG_ 468 PotGestOnOffReq 0;
BA_ "GenSigTimeoutMsg_HU_B" SG_ 468 PotGestOnOffReq 0;
BA_ "GenSigTimeoutMsg_HU_A" SG_ 468 PotGestOnOffReq 0;
BA_ "GenSigSendType" SG_ 468 PotGestOnOffReq 2;
BA_ "GenSigTimeoutMsg_HU_High_X445" SG_ 468 PotGestOnOffReq 0;
BA_ "GenSigTimeoutMsg_HU_Mid_X445" SG_ 468 PotGestOnOffReq 0;
BA_ "GenSigTimeoutTime_HU_High_X445" SG_ 468 PotGestOnOffReq 0;
BA_ "GenSigTimeoutTime_HU_Mid_X445" SG_ 468 PotGestOnOffReq 0;
BA_ "GenSigTimeoutMsg_IVI" SG_ 468 PotGestOnOffReq 0;
BA_ "GenSigTimeoutTime_IVI" SG_ 468 PotGestOnOffReq 0;
BA_ "GenSigTimeoutTime_HU_Mid_X451" SG_ 468 PotBuzzOnOffReq 0;
BA_ "GenSigTimeoutTime_HU_High_X451" SG_ 468 PotBuzzOnOffReq 0;
BA_ "GenSigTimeoutTime_HU_B" SG_ 468 PotBuzzOnOffReq 0;
BA_ "GenSigTimeoutTime_HU_A" SG_ 468 PotBuzzOnOffReq 0;
BA_ "GenSigTimeoutMsg_HU_Mid_X451" SG_ 468 PotBuzzOnOffReq 0;
BA_ "GenSigTimeoutMsg_HU_High_X451" SG_ 468 PotBuzzOnOffReq 0;
BA_ "GenSigTimeoutMsg_HU_B" SG_ 468 PotBuzzOnOffReq 0;
BA_ "GenSigTimeoutMsg_HU_A" SG_ 468 PotBuzzOnOffReq 0;
BA_ "GenSigSendType" SG_ 468 PotBuzzOnOffReq 2;
BA_ "GenSigTimeoutMsg_HU_High_X445" SG_ 468 PotBuzzOnOffReq 0;
BA_ "GenSigTimeoutMsg_HU_Mid_X445" SG_ 468 PotBuzzOnOffReq 0;
BA_ "GenSigTimeoutTime_HU_High_X445" SG_ 468 PotBuzzOnOffReq 0;
BA_ "GenSigTimeoutTime_HU_Mid_X445" SG_ 468 PotBuzzOnOffReq 0;
BA_ "GenSigTimeoutMsg_IVI" SG_ 468 PotBuzzOnOffReq 0;
BA_ "GenSigTimeoutTime_IVI" SG_ 468 PotBuzzOnOffReq 0;
BA_ "GenSigTimeoutTime_HU_Mid_X451" SG_ 468 RcwReqType 0;
BA_ "GenSigTimeoutTime_HU_High_X451" SG_ 468 RcwReqType 0;
BA_ "GenSigTimeoutTime_HU_B" SG_ 468 RcwReqType 0;
BA_ "GenSigTimeoutTime_HU_A" SG_ 468 RcwReqType 0;
BA_ "GenSigTimeoutMsg_HU_Mid_X451" SG_ 468 RcwReqType 0;
BA_ "GenSigTimeoutMsg_HU_High_X451" SG_ 468 RcwReqType 0;
BA_ "GenSigTimeoutMsg_HU_B" SG_ 468 RcwReqType 0;
BA_ "GenSigTimeoutMsg_HU_A" SG_ 468 RcwReqType 0;
BA_ "GenSigSendType" SG_ 468 RcwReqType 2;
BA_ "GenSigTimeoutMsg_HU_High_X445" SG_ 468 RcwReqType 0;
BA_ "GenSigTimeoutMsg_HU_Mid_X445" SG_ 468 RcwReqType 0;
BA_ "GenSigTimeoutTime_HU_High_X445" SG_ 468 RcwReqType 0;
BA_ "GenSigTimeoutTime_HU_Mid_X445" SG_ 468 RcwReqType 0;
BA_ "GenSigTimeoutMsg_IVI" SG_ 468 RcwReqType 0;
BA_ "GenSigTimeoutTime_IVI" SG_ 468 RcwReqType 0;
BA_ "GenSigTimeoutTime_HU_Mid_X451" SG_ 468 RcwOnOffStateReq 0;
BA_ "GenSigTimeoutTime_HU_High_X451" SG_ 468 RcwOnOffStateReq 0;
BA_ "GenSigTimeoutTime_HU_B" SG_ 468 RcwOnOffStateReq 0;
BA_ "GenSigTimeoutTime_HU_A" SG_ 468 RcwOnOffStateReq 0;
BA_ "GenSigTimeoutMsg_HU_Mid_X451" SG_ 468 RcwOnOffStateReq 0;
BA_ "GenSigTimeoutMsg_HU_High_X451" SG_ 468 RcwOnOffStateReq 0;
BA_ "GenSigTimeoutMsg_HU_B" SG_ 468 RcwOnOffStateReq 0;
BA_ "GenSigTimeoutMsg_HU_A" SG_ 468 RcwOnOffStateReq 0;
BA_ "GenSigSendType" SG_ 468 RcwOnOffStateReq 2;
BA_ "GenSigTimeoutMsg_HU_High_X445" SG_ 468 RcwOnOffStateReq 0;
BA_ "GenSigTimeoutMsg_HU_Mid_X445" SG_ 468 RcwOnOffStateReq 0;
BA_ "GenSigTimeoutTime_HU_High_X445" SG_ 468 RcwOnOffStateReq 0;
BA_ "GenSigTimeoutTime_HU_Mid_X445" SG_ 468 RcwOnOffStateReq 0;
BA_ "GenSigTimeoutMsg_IVI" SG_ 468 RcwOnOffStateReq 0;
BA_ "GenSigTimeoutTime_IVI" SG_ 468 RcwOnOffStateReq 0;
BA_ "GenSigTimeoutTime_HU_Mid_X451" SG_ 468 RcwOnOffStateAck 0;
BA_ "GenSigTimeoutTime_HU_High_X451" SG_ 468 RcwOnOffStateAck 0;
BA_ "GenSigTimeoutTime_HU_B" SG_ 468 RcwOnOffStateAck 0;
BA_ "GenSigTimeoutTime_HU_A" SG_ 468 RcwOnOffStateAck 0;
BA_ "GenSigTimeoutMsg_HU_Mid_X451" SG_ 468 RcwOnOffStateAck 0;
BA_ "GenSigTimeoutMsg_HU_High_X451" SG_ 468 RcwOnOffStateAck 0;
BA_ "GenSigTimeoutMsg_HU_B" SG_ 468 RcwOnOffStateAck 0;
BA_ "GenSigTimeoutMsg_HU_A" SG_ 468 RcwOnOffStateAck 0;
BA_ "GenSigSendType" SG_ 468 RcwOnOffStateAck 2;
BA_ "GenSigTimeoutMsg_HU_High_X445" SG_ 468 RcwOnOffStateAck 0;
BA_ "GenSigTimeoutMsg_HU_Mid_X445" SG_ 468 RcwOnOffStateAck 0;
BA_ "GenSigTimeoutTime_HU_High_X445" SG_ 468 RcwOnOffStateAck 0;
BA_ "GenSigTimeoutTime_HU_Mid_X445" SG_ 468 RcwOnOffStateAck 0;
BA_ "GenSigTimeoutMsg_IVI" SG_ 468 RcwOnOffStateAck 0;
BA_ "GenSigTimeoutTime_IVI" SG_ 468 RcwOnOffStateAck 0;
BA_ "GenSigTimeoutTime_HU_Mid_X451" SG_ 468 RctaReqType 0;
BA_ "GenSigTimeoutTime_HU_High_X451" SG_ 468 RctaReqType 0;
BA_ "GenSigTimeoutTime_HU_B" SG_ 468 RctaReqType 0;
BA_ "GenSigTimeoutTime_HU_A" SG_ 468 RctaReqType 0;
BA_ "GenSigTimeoutMsg_HU_Mid_X451" SG_ 468 RctaReqType 0;
BA_ "GenSigTimeoutMsg_HU_High_X451" SG_ 468 RctaReqType 0;
BA_ "GenSigTimeoutMsg_HU_B" SG_ 468 RctaReqType 0;
BA_ "GenSigTimeoutMsg_HU_A" SG_ 468 RctaReqType 0;
BA_ "GenSigSendType" SG_ 468 RctaReqType 2;
BA_ "GenSigTimeoutMsg_HU_High_X445" SG_ 468 RctaReqType 0;
BA_ "GenSigTimeoutMsg_HU_Mid_X445" SG_ 468 RctaReqType 0;
BA_ "GenSigTimeoutTime_HU_High_X445" SG_ 468 RctaReqType 0;
BA_ "GenSigTimeoutTime_HU_Mid_X445" SG_ 468 RctaReqType 0;
BA_ "GenSigTimeoutMsg_IVI" SG_ 468 RctaReqType 0;
BA_ "GenSigTimeoutTime_IVI" SG_ 468 RctaReqType 0;
BA_ "GenSigTimeoutTime_HU_Mid_X451" SG_ 468 RctaOnOffStateReq 0;
BA_ "GenSigTimeoutTime_HU_High_X451" SG_ 468 RctaOnOffStateReq 0;
BA_ "GenSigTimeoutTime_HU_B" SG_ 468 RctaOnOffStateReq 0;
BA_ "GenSigTimeoutTime_HU_A" SG_ 468 RctaOnOffStateReq 0;
BA_ "GenSigTimeoutMsg_HU_Mid_X451" SG_ 468 RctaOnOffStateReq 0;
BA_ "GenSigTimeoutMsg_HU_High_X451" SG_ 468 RctaOnOffStateReq 0;
BA_ "GenSigTimeoutMsg_HU_B" SG_ 468 RctaOnOffStateReq 0;
BA_ "GenSigTimeoutMsg_HU_A" SG_ 468 RctaOnOffStateReq 0;
BA_ "GenSigSendType" SG_ 468 RctaOnOffStateReq 2;
BA_ "GenSigTimeoutMsg_HU_High_X445" SG_ 468 RctaOnOffStateReq 0;
BA_ "GenSigTimeoutMsg_HU_Mid_X445" SG_ 468 RctaOnOffStateReq 0;
BA_ "GenSigTimeoutTime_HU_High_X445" SG_ 468 RctaOnOffStateReq 0;
BA_ "GenSigTimeoutTime_HU_Mid_X445" SG_ 468 RctaOnOffStateReq 0;
BA_ "GenSigTimeoutMsg_IVI" SG_ 468 RctaOnOffStateReq 0;
BA_ "GenSigTimeoutTime_IVI" SG_ 468 RctaOnOffStateReq 0;
BA_ "GenSigTimeoutTime_HU_Mid_X451" SG_ 468 RctaOnOffStateAck 0;
BA_ "GenSigTimeoutTime_HU_High_X451" SG_ 468 RctaOnOffStateAck 0;
BA_ "GenSigTimeoutTime_HU_B" SG_ 468 RctaOnOffStateAck 0;
BA_ "GenSigTimeoutTime_HU_A" SG_ 468 RctaOnOffStateAck 0;
BA_ "GenSigTimeoutMsg_HU_Mid_X451" SG_ 468 RctaOnOffStateAck 0;
BA_ "GenSigTimeoutMsg_HU_High_X451" SG_ 468 RctaOnOffStateAck 0;
BA_ "GenSigTimeoutMsg_HU_B" SG_ 468 RctaOnOffStateAck 0;
BA_ "GenSigTimeoutMsg_HU_A" SG_ 468 RctaOnOffStateAck 0;
BA_ "GenSigSendType" SG_ 468 RctaOnOffStateAck 2;
BA_ "GenSigTimeoutMsg_HU_High_X445" SG_ 468 RctaOnOffStateAck 0;
BA_ "GenSigTimeoutMsg_HU_Mid_X445" SG_ 468 RctaOnOffStateAck 0;
BA_ "GenSigTimeoutTime_HU_High_X445" SG_ 468 RctaOnOffStateAck 0;
BA_ "GenSigTimeoutTime_HU_Mid_X445" SG_ 468 RctaOnOffStateAck 0;
BA_ "GenSigTimeoutMsg_IVI" SG_ 468 RctaOnOffStateAck 0;
BA_ "GenSigTimeoutTime_IVI" SG_ 468 RctaOnOffStateAck 0;
BA_ "GenSigTimeoutTime_HU_Mid_X451" SG_ 468 DoaReqType 0;
BA_ "GenSigTimeoutTime_HU_High_X451" SG_ 468 DoaReqType 0;
BA_ "GenSigTimeoutTime_HU_B" SG_ 468 DoaReqType 0;
BA_ "GenSigTimeoutTime_HU_A" SG_ 468 DoaReqType 0;
BA_ "GenSigTimeoutMsg_HU_Mid_X451" SG_ 468 DoaReqType 0;
BA_ "GenSigTimeoutMsg_HU_High_X451" SG_ 468 DoaReqType 0;
BA_ "GenSigTimeoutMsg_HU_B" SG_ 468 DoaReqType 0;
BA_ "GenSigTimeoutMsg_HU_A" SG_ 468 DoaReqType 0;
BA_ "GenSigSendType" SG_ 468 DoaReqType 2;
BA_ "GenSigTimeoutMsg_HU_High_X445" SG_ 468 DoaReqType 0;
BA_ "GenSigTimeoutMsg_HU_Mid_X445" SG_ 468 DoaReqType 0;
BA_ "GenSigTimeoutTime_HU_High_X445" SG_ 468 DoaReqType 0;
BA_ "GenSigTimeoutTime_HU_Mid_X445" SG_ 468 DoaReqType 0;
BA_ "GenSigTimeoutMsg_IVI" SG_ 468 DoaReqType 0;
BA_ "GenSigTimeoutTime_IVI" SG_ 468 DoaReqType 0;
BA_ "GenSigTimeoutTime_HU_Mid_X451" SG_ 468 DoaOnOffStateReq 0;
BA_ "GenSigTimeoutTime_HU_High_X451" SG_ 468 DoaOnOffStateReq 0;
BA_ "GenSigTimeoutTime_HU_B" SG_ 468 DoaOnOffStateReq 0;
BA_ "GenSigTimeoutTime_HU_A" SG_ 468 DoaOnOffStateReq 0;
BA_ "GenSigTimeoutMsg_HU_Mid_X451" SG_ 468 DoaOnOffStateReq 0;
BA_ "GenSigTimeoutMsg_HU_High_X451" SG_ 468 DoaOnOffStateReq 0;
BA_ "GenSigTimeoutMsg_HU_B" SG_ 468 DoaOnOffStateReq 0;
BA_ "GenSigTimeoutMsg_HU_A" SG_ 468 DoaOnOffStateReq 0;
BA_ "GenSigSendType" SG_ 468 DoaOnOffStateReq 2;
BA_ "GenSigTimeoutMsg_HU_High_X445" SG_ 468 DoaOnOffStateReq 0;
BA_ "GenSigTimeoutMsg_HU_Mid_X445" SG_ 468 DoaOnOffStateReq 0;
BA_ "GenSigTimeoutTime_HU_High_X445" SG_ 468 DoaOnOffStateReq 0;
BA_ "GenSigTimeoutTime_HU_Mid_X445" SG_ 468 DoaOnOffStateReq 0;
BA_ "GenSigTimeoutMsg_IVI" SG_ 468 DoaOnOffStateReq 0;
BA_ "GenSigTimeoutTime_IVI" SG_ 468 DoaOnOffStateReq 0;
BA_ "GenSigTimeoutTime_HU_Mid_X451" SG_ 468 DoaOnOffStateAck 0;
BA_ "GenSigTimeoutTime_HU_High_X451" SG_ 468 DoaOnOffStateAck 0;
BA_ "GenSigTimeoutTime_HU_B" SG_ 468 DoaOnOffStateAck 0;
BA_ "GenSigTimeoutTime_HU_A" SG_ 468 DoaOnOffStateAck 0;
BA_ "GenSigTimeoutMsg_HU_Mid_X451" SG_ 468 DoaOnOffStateAck 0;
BA_ "GenSigTimeoutMsg_HU_High_X451" SG_ 468 DoaOnOffStateAck 0;
BA_ "GenSigTimeoutMsg_HU_B" SG_ 468 DoaOnOffStateAck 0;
BA_ "GenSigTimeoutMsg_HU_A" SG_ 468 DoaOnOffStateAck 0;
BA_ "GenSigSendType" SG_ 468 DoaOnOffStateAck 2;
BA_ "GenSigTimeoutMsg_HU_High_X445" SG_ 468 DoaOnOffStateAck 0;
BA_ "GenSigTimeoutMsg_HU_Mid_X445" SG_ 468 DoaOnOffStateAck 0;
BA_ "GenSigTimeoutTime_HU_High_X445" SG_ 468 DoaOnOffStateAck 0;
BA_ "GenSigTimeoutTime_HU_Mid_X445" SG_ 468 DoaOnOffStateAck 0;
BA_ "GenSigTimeoutMsg_IVI" SG_ 468 DoaOnOffStateAck 0;
BA_ "GenSigTimeoutTime_IVI" SG_ 468 DoaOnOffStateAck 0;
BA_ "GenSigTimeoutTime_HU_Mid_X451" SG_ 468 BsdReqType 0;
BA_ "GenSigTimeoutTime_HU_High_X451" SG_ 468 BsdReqType 0;
BA_ "GenSigTimeoutTime_HU_B" SG_ 468 BsdReqType 0;
BA_ "GenSigTimeoutTime_HU_A" SG_ 468 BsdReqType 0;
BA_ "GenSigTimeoutMsg_HU_Mid_X451" SG_ 468 BsdReqType 0;
BA_ "GenSigTimeoutMsg_HU_High_X451" SG_ 468 BsdReqType 0;
BA_ "GenSigTimeoutMsg_HU_B" SG_ 468 BsdReqType 0;
BA_ "GenSigTimeoutMsg_HU_A" SG_ 468 BsdReqType 0;
BA_ "GenSigSendType" SG_ 468 BsdReqType 2;
BA_ "GenSigTimeoutMsg_HU_High_X445" SG_ 468 BsdReqType 0;
BA_ "GenSigTimeoutMsg_HU_Mid_X445" SG_ 468 BsdReqType 0;
BA_ "GenSigTimeoutTime_HU_High_X445" SG_ 468 BsdReqType 0;
BA_ "GenSigTimeoutTime_HU_Mid_X445" SG_ 468 BsdReqType 0;
BA_ "GenSigTimeoutMsg_IVI" SG_ 468 BsdReqType 0;
BA_ "GenSigTimeoutTime_IVI" SG_ 468 BsdReqType 0;
BA_ "GenSigTimeoutTime_HU_Mid_X451" SG_ 468 BsdOnOffStateReq 0;
BA_ "GenSigTimeoutTime_HU_High_X451" SG_ 468 BsdOnOffStateReq 0;
BA_ "GenSigTimeoutTime_HU_B" SG_ 468 BsdOnOffStateReq 0;
BA_ "GenSigTimeoutTime_HU_A" SG_ 468 BsdOnOffStateReq 0;
BA_ "GenSigTimeoutMsg_HU_Mid_X451" SG_ 468 BsdOnOffStateReq 0;
BA_ "GenSigTimeoutMsg_HU_High_X451" SG_ 468 BsdOnOffStateReq 0;
BA_ "GenSigTimeoutMsg_HU_B" SG_ 468 BsdOnOffStateReq 0;
BA_ "GenSigTimeoutMsg_HU_A" SG_ 468 BsdOnOffStateReq 0;
BA_ "GenSigSendType" SG_ 468 BsdOnOffStateReq 2;
BA_ "GenSigTimeoutMsg_HU_High_X445" SG_ 468 BsdOnOffStateReq 0;
BA_ "GenSigTimeoutMsg_HU_Mid_X445" SG_ 468 BsdOnOffStateReq 0;
BA_ "GenSigTimeoutTime_HU_High_X445" SG_ 468 BsdOnOffStateReq 0;
BA_ "GenSigTimeoutTime_HU_Mid_X445" SG_ 468 BsdOnOffStateReq 0;
BA_ "GenSigTimeoutMsg_IVI" SG_ 468 BsdOnOffStateReq 0;
BA_ "GenSigTimeoutTime_IVI" SG_ 468 BsdOnOffStateReq 0;
BA_ "GenSigTimeoutTime_HU_Mid_X451" SG_ 468 BsdOnOffStateAck 0;
BA_ "GenSigTimeoutTime_HU_High_X451" SG_ 468 BsdOnOffStateAck 0;
BA_ "GenSigTimeoutTime_HU_B" SG_ 468 BsdOnOffStateAck 0;
BA_ "GenSigTimeoutTime_HU_A" SG_ 468 BsdOnOffStateAck 0;
BA_ "GenSigTimeoutMsg_HU_Mid_X451" SG_ 468 BsdOnOffStateAck 0;
BA_ "GenSigTimeoutMsg_HU_High_X451" SG_ 468 BsdOnOffStateAck 0;
BA_ "GenSigTimeoutMsg_HU_B" SG_ 468 BsdOnOffStateAck 0;
BA_ "GenSigTimeoutMsg_HU_A" SG_ 468 BsdOnOffStateAck 0;
BA_ "GenSigSendType" SG_ 468 BsdOnOffStateAck 2;
BA_ "GenSigTimeoutMsg_HU_High_X445" SG_ 468 BsdOnOffStateAck 0;
BA_ "GenSigTimeoutMsg_HU_Mid_X445" SG_ 468 BsdOnOffStateAck 0;
BA_ "GenSigTimeoutTime_HU_High_X445" SG_ 468 BsdOnOffStateAck 0;
BA_ "GenSigTimeoutTime_HU_Mid_X445" SG_ 468 BsdOnOffStateAck 0;
BA_ "GenSigTimeoutMsg_IVI" SG_ 468 BsdOnOffStateAck 0;
BA_ "GenSigTimeoutTime_IVI" SG_ 468 BsdOnOffStateAck 0;
BA_ "GenSigTimeoutTime_HU_Mid_X451" SG_ 468 FcwAebWarnSetStateReq 0;
BA_ "GenSigTimeoutTime_HU_High_X451" SG_ 468 FcwAebWarnSetStateReq 0;
BA_ "GenSigTimeoutTime_HU_B" SG_ 468 FcwAebWarnSetStateReq 0;
BA_ "GenSigTimeoutTime_HU_A" SG_ 468 FcwAebWarnSetStateReq 0;
BA_ "GenSigTimeoutMsg_HU_Mid_X451" SG_ 468 FcwAebWarnSetStateReq 0;
BA_ "GenSigTimeoutMsg_HU_High_X451" SG_ 468 FcwAebWarnSetStateReq 0;
BA_ "GenSigTimeoutMsg_HU_B" SG_ 468 FcwAebWarnSetStateReq 0;
BA_ "GenSigTimeoutMsg_HU_A" SG_ 468 FcwAebWarnSetStateReq 0;
BA_ "GenSigSendType" SG_ 468 FcwAebWarnSetStateReq 2;
BA_ "GenSigTimeoutMsg_HU_High_X445" SG_ 468 FcwAebWarnSetStateReq 0;
BA_ "GenSigTimeoutMsg_HU_Mid_X445" SG_ 468 FcwAebWarnSetStateReq 0;
BA_ "GenSigTimeoutTime_HU_High_X445" SG_ 468 FcwAebWarnSetStateReq 0;
BA_ "GenSigTimeoutTime_HU_Mid_X445" SG_ 468 FcwAebWarnSetStateReq 0;
BA_ "GenSigTimeoutMsg_IVI" SG_ 468 FcwAebWarnSetStateReq 0;
BA_ "GenSigTimeoutTime_IVI" SG_ 468 FcwAebWarnSetStateReq 0;
BA_ "GenSigTimeoutTime_HU_Mid_X451" SG_ 468 FcwAebWarnSetStateAck 0;
BA_ "GenSigTimeoutTime_HU_High_X451" SG_ 468 FcwAebWarnSetStateAck 0;
BA_ "GenSigTimeoutTime_HU_B" SG_ 468 FcwAebWarnSetStateAck 0;
BA_ "GenSigTimeoutTime_HU_A" SG_ 468 FcwAebWarnSetStateAck 0;
BA_ "GenSigTimeoutMsg_HU_Mid_X451" SG_ 468 FcwAebWarnSetStateAck 0;
BA_ "GenSigTimeoutMsg_HU_High_X451" SG_ 468 FcwAebWarnSetStateAck 0;
BA_ "GenSigTimeoutMsg_HU_B" SG_ 468 FcwAebWarnSetStateAck 0;
BA_ "GenSigTimeoutMsg_HU_A" SG_ 468 FcwAebWarnSetStateAck 0;
BA_ "GenSigSendType" SG_ 468 FcwAebWarnSetStateAck 2;
BA_ "GenSigTimeoutMsg_HU_High_X445" SG_ 468 FcwAebWarnSetStateAck 0;
BA_ "GenSigTimeoutMsg_HU_Mid_X445" SG_ 468 FcwAebWarnSetStateAck 0;
BA_ "GenSigTimeoutTime_HU_High_X445" SG_ 468 FcwAebWarnSetStateAck 0;
BA_ "GenSigTimeoutTime_HU_Mid_X445" SG_ 468 FcwAebWarnSetStateAck 0;
BA_ "GenSigTimeoutMsg_IVI" SG_ 468 FcwAebWarnSetStateAck 0;
BA_ "GenSigTimeoutTime_IVI" SG_ 468 FcwAebWarnSetStateAck 0;
BA_ "GenSigTimeoutTime_HU_Mid_X451" SG_ 468 FcwAebReqType 0;
BA_ "GenSigTimeoutTime_HU_High_X451" SG_ 468 FcwAebReqType 0;
BA_ "GenSigTimeoutTime_HU_B" SG_ 468 FcwAebReqType 0;
BA_ "GenSigTimeoutTime_HU_A" SG_ 468 FcwAebReqType 0;
BA_ "GenSigTimeoutMsg_HU_Mid_X451" SG_ 468 FcwAebReqType 0;
BA_ "GenSigTimeoutMsg_HU_High_X451" SG_ 468 FcwAebReqType 0;
BA_ "GenSigTimeoutMsg_HU_B" SG_ 468 FcwAebReqType 0;
BA_ "GenSigTimeoutMsg_HU_A" SG_ 468 FcwAebReqType 0;
BA_ "GenSigSendType" SG_ 468 FcwAebReqType 2;
BA_ "GenSigTimeoutMsg_HU_High_X445" SG_ 468 FcwAebReqType 0;
BA_ "GenSigTimeoutMsg_HU_Mid_X445" SG_ 468 FcwAebReqType 0;
BA_ "GenSigTimeoutTime_HU_High_X445" SG_ 468 FcwAebReqType 0;
BA_ "GenSigTimeoutTime_HU_Mid_X445" SG_ 468 FcwAebReqType 0;
BA_ "GenSigTimeoutMsg_IVI" SG_ 468 FcwAebReqType 0;
BA_ "GenSigTimeoutTime_IVI" SG_ 468 FcwAebReqType 0;
BA_ "GenSigTimeoutTime_HU_Mid_X451" SG_ 468 FcwAebOnOffStateReq 0;
BA_ "GenSigTimeoutTime_HU_High_X451" SG_ 468 FcwAebOnOffStateReq 0;
BA_ "GenSigTimeoutTime_HU_B" SG_ 468 FcwAebOnOffStateReq 0;
BA_ "GenSigTimeoutTime_HU_A" SG_ 468 FcwAebOnOffStateReq 0;
BA_ "GenSigTimeoutMsg_HU_Mid_X451" SG_ 468 FcwAebOnOffStateReq 0;
BA_ "GenSigTimeoutMsg_HU_High_X451" SG_ 468 FcwAebOnOffStateReq 0;
BA_ "GenSigTimeoutMsg_HU_B" SG_ 468 FcwAebOnOffStateReq 0;
BA_ "GenSigTimeoutMsg_HU_A" SG_ 468 FcwAebOnOffStateReq 0;
BA_ "GenSigSendType" SG_ 468 FcwAebOnOffStateReq 2;
BA_ "GenSigTimeoutMsg_HU_High_X445" SG_ 468 FcwAebOnOffStateReq 0;
BA_ "GenSigTimeoutMsg_HU_Mid_X445" SG_ 468 FcwAebOnOffStateReq 0;
BA_ "GenSigTimeoutTime_HU_High_X445" SG_ 468 FcwAebOnOffStateReq 0;
BA_ "GenSigTimeoutTime_HU_Mid_X445" SG_ 468 FcwAebOnOffStateReq 0;
BA_ "GenSigTimeoutMsg_IVI" SG_ 468 FcwAebOnOffStateReq 0;
BA_ "GenSigTimeoutTime_IVI" SG_ 468 FcwAebOnOffStateReq 0;
BA_ "GenSigTimeoutTime_HU_Mid_X451" SG_ 468 FcwAebOnOffStateAck 0;
BA_ "GenSigTimeoutTime_HU_High_X451" SG_ 468 FcwAebOnOffStateAck 0;
BA_ "GenSigTimeoutTime_HU_B" SG_ 468 FcwAebOnOffStateAck 0;
BA_ "GenSigTimeoutTime_HU_A" SG_ 468 FcwAebOnOffStateAck 0;
BA_ "GenSigTimeoutMsg_HU_Mid_X451" SG_ 468 FcwAebOnOffStateAck 0;
BA_ "GenSigTimeoutMsg_HU_High_X451" SG_ 468 FcwAebOnOffStateAck 0;
BA_ "GenSigTimeoutMsg_HU_B" SG_ 468 FcwAebOnOffStateAck 0;
BA_ "GenSigTimeoutMsg_HU_A" SG_ 468 FcwAebOnOffStateAck 0;
BA_ "GenSigSendType" SG_ 468 FcwAebOnOffStateAck 2;
BA_ "GenSigTimeoutMsg_HU_High_X445" SG_ 468 FcwAebOnOffStateAck 0;
BA_ "GenSigTimeoutMsg_HU_Mid_X445" SG_ 468 FcwAebOnOffStateAck 0;
BA_ "GenSigTimeoutTime_HU_High_X445" SG_ 468 FcwAebOnOffStateAck 0;
BA_ "GenSigTimeoutTime_HU_Mid_X445" SG_ 468 FcwAebOnOffStateAck 0;
BA_ "GenSigTimeoutMsg_IVI" SG_ 468 FcwAebOnOffStateAck 0;
BA_ "GenSigTimeoutTime_IVI" SG_ 468 FcwAebOnOffStateAck 0;
BA_ "GenSigTimeoutTime_HU_Mid_X451" SG_ 468 TsrReqType 0;
BA_ "GenSigTimeoutTime_HU_High_X451" SG_ 468 TsrReqType 0;
BA_ "GenSigTimeoutTime_HU_B" SG_ 468 TsrReqType 0;
BA_ "GenSigTimeoutTime_HU_A" SG_ 468 TsrReqType 0;
BA_ "GenSigTimeoutMsg_HU_Mid_X451" SG_ 468 TsrReqType 0;
BA_ "GenSigTimeoutMsg_HU_High_X451" SG_ 468 TsrReqType 0;
BA_ "GenSigTimeoutMsg_HU_B" SG_ 468 TsrReqType 0;
BA_ "GenSigTimeoutMsg_HU_A" SG_ 468 TsrReqType 0;
BA_ "GenSigSendType" SG_ 468 TsrReqType 2;
BA_ "GenSigTimeoutMsg_HU_High_X445" SG_ 468 TsrReqType 0;
BA_ "GenSigTimeoutMsg_HU_Mid_X445" SG_ 468 TsrReqType 0;
BA_ "GenSigTimeoutTime_HU_High_X445" SG_ 468 TsrReqType 0;
BA_ "GenSigTimeoutTime_HU_Mid_X445" SG_ 468 TsrReqType 0;
BA_ "GenSigTimeoutMsg_IVI" SG_ 468 TsrReqType 0;
BA_ "GenSigTimeoutTime_IVI" SG_ 468 TsrReqType 0;
BA_ "GenSigTimeoutTime_HU_Mid_X451" SG_ 468 TsrOnOffStateReq 0;
BA_ "GenSigTimeoutTime_HU_High_X451" SG_ 468 TsrOnOffStateReq 0;
BA_ "GenSigTimeoutTime_HU_B" SG_ 468 TsrOnOffStateReq 0;
BA_ "GenSigTimeoutTime_HU_A" SG_ 468 TsrOnOffStateReq 0;
BA_ "GenSigTimeoutMsg_HU_Mid_X451" SG_ 468 TsrOnOffStateReq 0;
BA_ "GenSigTimeoutMsg_HU_High_X451" SG_ 468 TsrOnOffStateReq 0;
BA_ "GenSigTimeoutMsg_HU_B" SG_ 468 TsrOnOffStateReq 0;
BA_ "GenSigTimeoutMsg_HU_A" SG_ 468 TsrOnOffStateReq 0;
BA_ "GenSigSendType" SG_ 468 TsrOnOffStateReq 2;
BA_ "GenSigTimeoutMsg_HU_High_X445" SG_ 468 TsrOnOffStateReq 0;
BA_ "GenSigTimeoutMsg_HU_Mid_X445" SG_ 468 TsrOnOffStateReq 0;
BA_ "GenSigTimeoutTime_HU_High_X445" SG_ 468 TsrOnOffStateReq 0;
BA_ "GenSigTimeoutTime_HU_Mid_X445" SG_ 468 TsrOnOffStateReq 0;
BA_ "GenSigTimeoutMsg_IVI" SG_ 468 TsrOnOffStateReq 0;
BA_ "GenSigTimeoutTime_IVI" SG_ 468 TsrOnOffStateReq 0;
BA_ "GenSigTimeoutTime_HU_Mid_X451" SG_ 468 TsrOnOffStateAck 0;
BA_ "GenSigTimeoutTime_HU_High_X451" SG_ 468 TsrOnOffStateAck 0;
BA_ "GenSigTimeoutTime_HU_B" SG_ 468 TsrOnOffStateAck 0;
BA_ "GenSigTimeoutTime_HU_A" SG_ 468 TsrOnOffStateAck 0;
BA_ "GenSigTimeoutMsg_HU_Mid_X451" SG_ 468 TsrOnOffStateAck 0;
BA_ "GenSigTimeoutMsg_HU_High_X451" SG_ 468 TsrOnOffStateAck 0;
BA_ "GenSigTimeoutMsg_HU_B" SG_ 468 TsrOnOffStateAck 0;
BA_ "GenSigTimeoutMsg_HU_A" SG_ 468 TsrOnOffStateAck 0;
BA_ "GenSigSendType" SG_ 468 TsrOnOffStateAck 2;
BA_ "GenSigTimeoutMsg_HU_High_X445" SG_ 468 TsrOnOffStateAck 0;
BA_ "GenSigTimeoutMsg_HU_Mid_X445" SG_ 468 TsrOnOffStateAck 0;
BA_ "GenSigTimeoutTime_HU_High_X445" SG_ 468 TsrOnOffStateAck 0;
BA_ "GenSigTimeoutTime_HU_Mid_X445" SG_ 468 TsrOnOffStateAck 0;
BA_ "GenSigTimeoutMsg_IVI" SG_ 468 TsrOnOffStateAck 0;
BA_ "GenSigTimeoutTime_IVI" SG_ 468 TsrOnOffStateAck 0;
BA_ "GenSigTimeoutTime_HU_Mid_X451" SG_ 468 LdwOnOffStateReq 0;
BA_ "GenSigTimeoutTime_HU_High_X451" SG_ 468 LdwOnOffStateReq 0;
BA_ "GenSigTimeoutTime_HU_B" SG_ 468 LdwOnOffStateReq 0;
BA_ "GenSigTimeoutTime_HU_A" SG_ 468 LdwOnOffStateReq 0;
BA_ "GenSigTimeoutMsg_HU_Mid_X451" SG_ 468 LdwOnOffStateReq 0;
BA_ "GenSigTimeoutMsg_HU_High_X451" SG_ 468 LdwOnOffStateReq 0;
BA_ "GenSigTimeoutMsg_HU_B" SG_ 468 LdwOnOffStateReq 0;
BA_ "GenSigTimeoutMsg_HU_A" SG_ 468 LdwOnOffStateReq 0;
BA_ "GenSigSendType" SG_ 468 LdwOnOffStateReq 2;
BA_ "GenSigTimeoutMsg_HU_High_X445" SG_ 468 LdwOnOffStateReq 0;
BA_ "GenSigTimeoutMsg_HU_Mid_X445" SG_ 468 LdwOnOffStateReq 0;
BA_ "GenSigTimeoutTime_HU_High_X445" SG_ 468 LdwOnOffStateReq 0;
BA_ "GenSigTimeoutTime_HU_Mid_X445" SG_ 468 LdwOnOffStateReq 0;
BA_ "GenSigTimeoutMsg_IVI" SG_ 468 LdwOnOffStateReq 0;
BA_ "GenSigTimeoutTime_IVI" SG_ 468 LdwOnOffStateReq 0;
BA_ "GenSigTimeoutTime_HU_Mid_X451" SG_ 468 LdwReqType 0;
BA_ "GenSigTimeoutTime_HU_High_X451" SG_ 468 LdwReqType 0;
BA_ "GenSigTimeoutTime_HU_B" SG_ 468 LdwReqType 0;
BA_ "GenSigTimeoutTime_HU_A" SG_ 468 LdwReqType 0;
BA_ "GenSigTimeoutMsg_HU_Mid_X451" SG_ 468 LdwReqType 0;
BA_ "GenSigTimeoutMsg_HU_High_X451" SG_ 468 LdwReqType 0;
BA_ "GenSigTimeoutMsg_HU_B" SG_ 468 LdwReqType 0;
BA_ "GenSigTimeoutMsg_HU_A" SG_ 468 LdwReqType 0;
BA_ "GenSigSendType" SG_ 468 LdwReqType 2;
BA_ "GenSigTimeoutMsg_HU_High_X445" SG_ 468 LdwReqType 0;
BA_ "GenSigTimeoutMsg_HU_Mid_X445" SG_ 468 LdwReqType 0;
BA_ "GenSigTimeoutTime_HU_High_X445" SG_ 468 LdwReqType 0;
BA_ "GenSigTimeoutTime_HU_Mid_X445" SG_ 468 LdwReqType 0;
BA_ "GenSigTimeoutMsg_IVI" SG_ 468 LdwReqType 0;
BA_ "GenSigTimeoutTime_IVI" SG_ 468 LdwReqType 0;
BA_ "GenSigTimeoutTime_HU_Mid_X451" SG_ 468 LdwOnOffStateAck 0;
BA_ "GenSigTimeoutTime_HU_High_X451" SG_ 468 LdwOnOffStateAck 0;
BA_ "GenSigTimeoutTime_HU_B" SG_ 468 LdwOnOffStateAck 0;
BA_ "GenSigTimeoutTime_HU_A" SG_ 468 LdwOnOffStateAck 0;
BA_ "GenSigTimeoutMsg_HU_Mid_X451" SG_ 468 LdwOnOffStateAck 0;
BA_ "GenSigTimeoutMsg_HU_High_X451" SG_ 468 LdwOnOffStateAck 0;
BA_ "GenSigTimeoutMsg_HU_B" SG_ 468 LdwOnOffStateAck 0;
BA_ "GenSigTimeoutMsg_HU_A" SG_ 468 LdwOnOffStateAck 0;
BA_ "GenSigSendType" SG_ 468 LdwOnOffStateAck 2;
BA_ "GenSigTimeoutMsg_HU_High_X445" SG_ 468 LdwOnOffStateAck 0;
BA_ "GenSigTimeoutMsg_HU_Mid_X445" SG_ 468 LdwOnOffStateAck 0;
BA_ "GenSigTimeoutTime_HU_High_X445" SG_ 468 LdwOnOffStateAck 0;
BA_ "GenSigTimeoutTime_HU_Mid_X445" SG_ 468 LdwOnOffStateAck 0;
BA_ "GenSigTimeoutMsg_IVI" SG_ 468 LdwOnOffStateAck 0;
BA_ "GenSigTimeoutTime_IVI" SG_ 468 LdwOnOffStateAck 0;
BA_ "GenSigTimeoutTime_HU_Mid_X451" SG_ 468 HbaOnOffStateReq 0;
BA_ "GenSigTimeoutTime_HU_High_X451" SG_ 468 HbaOnOffStateReq 0;
BA_ "GenSigTimeoutTime_HU_B" SG_ 468 HbaOnOffStateReq 0;
BA_ "GenSigTimeoutTime_HU_A" SG_ 468 HbaOnOffStateReq 0;
BA_ "GenSigTimeoutMsg_HU_Mid_X451" SG_ 468 HbaOnOffStateReq 0;
BA_ "GenSigTimeoutMsg_HU_High_X451" SG_ 468 HbaOnOffStateReq 0;
BA_ "GenSigTimeoutMsg_HU_B" SG_ 468 HbaOnOffStateReq 0;
BA_ "GenSigTimeoutMsg_HU_A" SG_ 468 HbaOnOffStateReq 0;
BA_ "GenSigSendType" SG_ 468 HbaOnOffStateReq 2;
BA_ "GenSigTimeoutMsg_HU_High_X445" SG_ 468 HbaOnOffStateReq 0;
BA_ "GenSigTimeoutMsg_HU_Mid_X445" SG_ 468 HbaOnOffStateReq 0;
BA_ "GenSigTimeoutTime_HU_High_X445" SG_ 468 HbaOnOffStateReq 0;
BA_ "GenSigTimeoutTime_HU_Mid_X445" SG_ 468 HbaOnOffStateReq 0;
BA_ "GenSigTimeoutMsg_IVI" SG_ 468 HbaOnOffStateReq 0;
BA_ "GenSigTimeoutTime_IVI" SG_ 468 HbaOnOffStateReq 0;
BA_ "GenSigTimeoutTime_HU_Mid_X451" SG_ 468 HbaReqType 0;
BA_ "GenSigTimeoutTime_HU_High_X451" SG_ 468 HbaReqType 0;
BA_ "GenSigTimeoutTime_HU_B" SG_ 468 HbaReqType 0;
BA_ "GenSigTimeoutTime_HU_A" SG_ 468 HbaReqType 0;
BA_ "GenSigTimeoutMsg_HU_Mid_X451" SG_ 468 HbaReqType 0;
BA_ "GenSigTimeoutMsg_HU_High_X451" SG_ 468 HbaReqType 0;
BA_ "GenSigTimeoutMsg_HU_B" SG_ 468 HbaReqType 0;
BA_ "GenSigTimeoutMsg_HU_A" SG_ 468 HbaReqType 0;
BA_ "GenSigSendType" SG_ 468 HbaReqType 2;
BA_ "GenSigTimeoutMsg_HU_High_X445" SG_ 468 HbaReqType 0;
BA_ "GenSigTimeoutMsg_HU_Mid_X445" SG_ 468 HbaReqType 0;
BA_ "GenSigTimeoutTime_HU_High_X445" SG_ 468 HbaReqType 0;
BA_ "GenSigTimeoutTime_HU_Mid_X445" SG_ 468 HbaReqType 0;
BA_ "GenSigTimeoutMsg_IVI" SG_ 468 HbaReqType 0;
BA_ "GenSigTimeoutTime_IVI" SG_ 468 HbaReqType 0;
BA_ "GenSigTimeoutTime_HU_Mid_X451" SG_ 468 HbaOnOffStateAck 0;
BA_ "GenSigTimeoutTime_HU_High_X451" SG_ 468 HbaOnOffStateAck 0;
BA_ "GenSigTimeoutTime_HU_B" SG_ 468 HbaOnOffStateAck 0;
BA_ "GenSigTimeoutTime_HU_A" SG_ 468 HbaOnOffStateAck 0;
BA_ "GenSigTimeoutMsg_HU_Mid_X451" SG_ 468 HbaOnOffStateAck 0;
BA_ "GenSigTimeoutMsg_HU_High_X451" SG_ 468 HbaOnOffStateAck 0;
BA_ "GenSigTimeoutMsg_HU_B" SG_ 468 HbaOnOffStateAck 0;
BA_ "GenSigTimeoutMsg_HU_A" SG_ 468 HbaOnOffStateAck 0;
BA_ "GenSigSendType" SG_ 468 HbaOnOffStateAck 2;
BA_ "GenSigTimeoutMsg_HU_High_X445" SG_ 468 HbaOnOffStateAck 0;
BA_ "GenSigTimeoutMsg_HU_Mid_X445" SG_ 468 HbaOnOffStateAck 0;
BA_ "GenSigTimeoutTime_HU_High_X445" SG_ 468 HbaOnOffStateAck 0;
BA_ "GenSigTimeoutTime_HU_Mid_X445" SG_ 468 HbaOnOffStateAck 0;
BA_ "GenSigTimeoutMsg_IVI" SG_ 468 HbaOnOffStateAck 0;
BA_ "GenSigTimeoutTime_IVI" SG_ 468 HbaOnOffStateAck 0;
BA_ "GenSigTimeoutTime_HU_Mid_X451" SG_ 471 LdwOnOffStateValidity 0;
BA_ "GenSigTimeoutTime_HU_High_X451" SG_ 471 LdwOnOffStateValidity 0;
BA_ "GenSigTimeoutTime_HU_B" SG_ 471 LdwOnOffStateValidity 0;
BA_ "GenSigTimeoutTime_HU_A" SG_ 471 LdwOnOffStateValidity 0;
BA_ "GenSigTimeoutMsg_HU_Mid_X451" SG_ 471 LdwOnOffStateValidity 0;
BA_ "GenSigTimeoutMsg_HU_High_X451" SG_ 471 LdwOnOffStateValidity 0;
BA_ "GenSigTimeoutMsg_HU_B" SG_ 471 LdwOnOffStateValidity 0;
BA_ "GenSigTimeoutMsg_HU_A" SG_ 471 LdwOnOffStateValidity 0;
BA_ "GenSigSendType" SG_ 471 LdwOnOffStateValidity 2;
BA_ "GenSigTimeoutMsg_HU_High_X445" SG_ 471 LdwOnOffStateValidity 0;
BA_ "GenSigTimeoutMsg_HU_Mid_X445" SG_ 471 LdwOnOffStateValidity 0;
BA_ "GenSigTimeoutTime_HU_High_X445" SG_ 471 LdwOnOffStateValidity 0;
BA_ "GenSigTimeoutTime_HU_Mid_X445" SG_ 471 LdwOnOffStateValidity 0;
BA_ "GenSigTimeoutMsg_IVI" SG_ 471 LdwOnOffStateValidity 0;
BA_ "GenSigTimeoutTime_IVI" SG_ 471 LdwOnOffStateValidity 0;
BA_ "GenSigTimeoutTime_HU_B" SG_ 471 AdasSteeringSwitchStateAck 0;
BA_ "GenSigTimeoutTime_HU_A" SG_ 471 AdasSteeringSwitchStateAck 0;
BA_ "GenSigTimeoutMsg_HU_B" SG_ 471 AdasSteeringSwitchStateAck 0;
BA_ "GenSigTimeoutMsg_HU_A" SG_ 471 AdasSteeringSwitchStateAck 0;
BA_ "GenSigSendType" SG_ 471 AdasSteeringSwitchStateAck 2;
BA_ "GenSigTimeoutTime_HU_Mid_X451" SG_ 471 TsrSignalApplicability 0;
BA_ "GenSigTimeoutTime_HU_High_X451" SG_ 471 TsrSignalApplicability 0;
BA_ "GenSigTimeoutTime_HU_B" SG_ 471 TsrSignalApplicability 0;
BA_ "GenSigTimeoutTime_HU_A" SG_ 471 TsrSignalApplicability 0;
BA_ "GenSigTimeoutMsg_HU_Mid_X451" SG_ 471 TsrSignalApplicability 0;
BA_ "GenSigTimeoutMsg_HU_High_X451" SG_ 471 TsrSignalApplicability 0;
BA_ "GenSigTimeoutMsg_HU_B" SG_ 471 TsrSignalApplicability 0;
BA_ "GenSigTimeoutMsg_HU_A" SG_ 471 TsrSignalApplicability 0;
BA_ "GenSigSendType" SG_ 471 TsrSignalApplicability 2;
BA_ "GenSigTimeoutMsg_HU_High_X445" SG_ 471 TsrSignalApplicability 0;
BA_ "GenSigTimeoutMsg_HU_Mid_X445" SG_ 471 TsrSignalApplicability 0;
BA_ "GenSigTimeoutTime_HU_High_X445" SG_ 471 TsrSignalApplicability 0;
BA_ "GenSigTimeoutTime_HU_Mid_X445" SG_ 471 TsrSignalApplicability 0;
BA_ "GenSigTimeoutMsg_IVI" SG_ 471 TsrSignalApplicability 0;
BA_ "GenSigTimeoutTime_IVI" SG_ 471 TsrSignalApplicability 0;
BA_ "GenSigTimeoutTime_HU_Mid_X451" SG_ 471 FcwAebSignalApplicability 0;
BA_ "GenSigTimeoutTime_HU_High_X451" SG_ 471 FcwAebSignalApplicability 0;
BA_ "GenSigTimeoutTime_HU_B" SG_ 471 FcwAebSignalApplicability 0;
BA_ "GenSigTimeoutTime_HU_A" SG_ 471 FcwAebSignalApplicability 0;
BA_ "GenSigTimeoutMsg_HU_Mid_X451" SG_ 471 FcwAebSignalApplicability 0;
BA_ "GenSigTimeoutMsg_HU_High_X451" SG_ 471 FcwAebSignalApplicability 0;
BA_ "GenSigTimeoutMsg_HU_B" SG_ 471 FcwAebSignalApplicability 0;
BA_ "GenSigTimeoutMsg_HU_A" SG_ 471 FcwAebSignalApplicability 0;
BA_ "GenSigSendType" SG_ 471 FcwAebSignalApplicability 2;
BA_ "GenSigTimeoutMsg_HU_High_X445" SG_ 471 FcwAebSignalApplicability 0;
BA_ "GenSigTimeoutMsg_HU_Mid_X445" SG_ 471 FcwAebSignalApplicability 0;
BA_ "GenSigTimeoutTime_HU_High_X445" SG_ 471 FcwAebSignalApplicability 0;
BA_ "GenSigTimeoutTime_HU_Mid_X445" SG_ 471 FcwAebSignalApplicability 0;
BA_ "GenSigTimeoutMsg_IVI" SG_ 471 FcwAebSignalApplicability 0;
BA_ "GenSigTimeoutTime_IVI" SG_ 471 FcwAebSignalApplicability 0;
BA_ "GenSigTimeoutTime_HU_Mid_X451" SG_ 471 LdwSignalApplicability 0;
BA_ "GenSigTimeoutTime_HU_High_X451" SG_ 471 LdwSignalApplicability 0;
BA_ "GenSigTimeoutTime_HU_B" SG_ 471 LdwSignalApplicability 0;
BA_ "GenSigTimeoutTime_HU_A" SG_ 471 LdwSignalApplicability 0;
BA_ "GenSigTimeoutMsg_HU_Mid_X451" SG_ 471 LdwSignalApplicability 0;
BA_ "GenSigTimeoutMsg_HU_High_X451" SG_ 471 LdwSignalApplicability 0;
BA_ "GenSigTimeoutMsg_HU_B" SG_ 471 LdwSignalApplicability 0;
BA_ "GenSigTimeoutMsg_HU_A" SG_ 471 LdwSignalApplicability 0;
BA_ "GenSigSendType" SG_ 471 LdwSignalApplicability 2;
BA_ "GenSigTimeoutMsg_HU_High_X445" SG_ 471 LdwSignalApplicability 0;
BA_ "GenSigTimeoutMsg_HU_Mid_X445" SG_ 471 LdwSignalApplicability 0;
BA_ "GenSigTimeoutTime_HU_High_X445" SG_ 471 LdwSignalApplicability 0;
BA_ "GenSigTimeoutTime_HU_Mid_X445" SG_ 471 LdwSignalApplicability 0;
BA_ "GenSigTimeoutMsg_IVI" SG_ 471 LdwSignalApplicability 0;
BA_ "GenSigTimeoutTime_IVI" SG_ 471 LdwSignalApplicability 0;
BA_ "GenSigTimeoutTime_HU_Mid_X451" SG_ 471 HbaSignalApplicability 0;
BA_ "GenSigTimeoutTime_HU_High_X451" SG_ 471 HbaSignalApplicability 0;
BA_ "GenSigTimeoutTime_HU_B" SG_ 471 HbaSignalApplicability 0;
BA_ "GenSigTimeoutTime_HU_A" SG_ 471 HbaSignalApplicability 0;
BA_ "GenSigTimeoutMsg_HU_Mid_X451" SG_ 471 HbaSignalApplicability 0;
BA_ "GenSigTimeoutMsg_HU_High_X451" SG_ 471 HbaSignalApplicability 0;
BA_ "GenSigTimeoutMsg_HU_B" SG_ 471 HbaSignalApplicability 0;
BA_ "GenSigTimeoutMsg_HU_A" SG_ 471 HbaSignalApplicability 0;
BA_ "GenSigSendType" SG_ 471 HbaSignalApplicability 2;
BA_ "GenSigTimeoutMsg_HU_High_X445" SG_ 471 HbaSignalApplicability 0;
BA_ "GenSigTimeoutMsg_HU_Mid_X445" SG_ 471 HbaSignalApplicability 0;
BA_ "GenSigTimeoutTime_HU_High_X445" SG_ 471 HbaSignalApplicability 0;
BA_ "GenSigTimeoutTime_HU_Mid_X445" SG_ 471 HbaSignalApplicability 0;
BA_ "GenSigTimeoutMsg_IVI" SG_ 471 HbaSignalApplicability 0;
BA_ "GenSigTimeoutTime_IVI" SG_ 471 HbaSignalApplicability 0;
BA_ "GenSigTimeoutTime_HU_Mid_X451" SG_ 471 FcwAebOnOffConfigStateValidity 0;
BA_ "GenSigTimeoutTime_HU_High_X451" SG_ 471 FcwAebOnOffConfigStateValidity 0;
BA_ "GenSigTimeoutTime_HU_B" SG_ 471 FcwAebOnOffConfigStateValidity 0;
BA_ "GenSigTimeoutTime_HU_A" SG_ 471 FcwAebOnOffConfigStateValidity 0;
BA_ "GenSigTimeoutMsg_HU_Mid_X451" SG_ 471 FcwAebOnOffConfigStateValidity 0;
BA_ "GenSigTimeoutMsg_HU_High_X451" SG_ 471 FcwAebOnOffConfigStateValidity 0;
BA_ "GenSigTimeoutMsg_HU_B" SG_ 471 FcwAebOnOffConfigStateValidity 0;
BA_ "GenSigTimeoutMsg_HU_A" SG_ 471 FcwAebOnOffConfigStateValidity 0;
BA_ "GenSigSendType" SG_ 471 FcwAebOnOffConfigStateValidity 2;
BA_ "GenSigTimeoutMsg_HU_High_X445" SG_ 471 FcwAebOnOffConfigStateValidity 0;
BA_ "GenSigTimeoutMsg_HU_Mid_X445" SG_ 471 FcwAebOnOffConfigStateValidity 0;
BA_ "GenSigTimeoutTime_HU_High_X445" SG_ 471 FcwAebOnOffConfigStateValidity 0;
BA_ "GenSigTimeoutTime_HU_Mid_X445" SG_ 471 FcwAebOnOffConfigStateValidity 0;
BA_ "GenSigTimeoutMsg_IVI" SG_ 471 FcwAebOnOffConfigStateValidity 0;
BA_ "GenSigTimeoutTime_IVI" SG_ 471 FcwAebOnOffConfigStateValidity 0;
BA_ "GenSigTimeoutTime_HU_Mid_X451" SG_ 471 FcwAebWarnSetConfigStateValidity 0;
BA_ "GenSigTimeoutTime_HU_High_X451" SG_ 471 FcwAebWarnSetConfigStateValidity 0;
BA_ "GenSigTimeoutTime_HU_B" SG_ 471 FcwAebWarnSetConfigStateValidity 0;
BA_ "GenSigTimeoutTime_HU_A" SG_ 471 FcwAebWarnSetConfigStateValidity 0;
BA_ "GenSigTimeoutMsg_HU_Mid_X451" SG_ 471 FcwAebWarnSetConfigStateValidity 0;
BA_ "GenSigTimeoutMsg_HU_High_X451" SG_ 471 FcwAebWarnSetConfigStateValidity 0;
BA_ "GenSigTimeoutMsg_HU_B" SG_ 471 FcwAebWarnSetConfigStateValidity 0;
BA_ "GenSigTimeoutMsg_HU_A" SG_ 471 FcwAebWarnSetConfigStateValidity 0;
BA_ "GenSigSendType" SG_ 471 FcwAebWarnSetConfigStateValidity 2;
BA_ "GenSigTimeoutMsg_HU_High_X445" SG_ 471 FcwAebWarnSetConfigStateValidity 0;
BA_ "GenSigTimeoutMsg_HU_Mid_X445" SG_ 471 FcwAebWarnSetConfigStateValidity 0;
BA_ "GenSigTimeoutTime_HU_High_X445" SG_ 471 FcwAebWarnSetConfigStateValidity 0;
BA_ "GenSigTimeoutTime_HU_Mid_X445" SG_ 471 FcwAebWarnSetConfigStateValidity 0;
BA_ "GenSigTimeoutMsg_IVI" SG_ 471 FcwAebWarnSetConfigStateValidity 0;
BA_ "GenSigTimeoutTime_IVI" SG_ 471 FcwAebWarnSetConfigStateValidity 0;
BA_ "GenSigTimeoutTime_HU_Mid_X451" SG_ 471 FcwAebWarnSetConfigState 0;
BA_ "GenSigTimeoutTime_HU_High_X451" SG_ 471 FcwAebWarnSetConfigState 0;
BA_ "GenSigTimeoutTime_HU_B" SG_ 471 FcwAebWarnSetConfigState 0;
BA_ "GenSigTimeoutTime_HU_A" SG_ 471 FcwAebWarnSetConfigState 0;
BA_ "GenSigTimeoutMsg_HU_Mid_X451" SG_ 471 FcwAebWarnSetConfigState 0;
BA_ "GenSigTimeoutMsg_HU_High_X451" SG_ 471 FcwAebWarnSetConfigState 0;
BA_ "GenSigTimeoutMsg_HU_B" SG_ 471 FcwAebWarnSetConfigState 0;
BA_ "GenSigTimeoutMsg_HU_A" SG_ 471 FcwAebWarnSetConfigState 0;
BA_ "GenSigSendType" SG_ 471 FcwAebWarnSetConfigState 2;
BA_ "GenSigTimeoutMsg_HU_High_X445" SG_ 471 FcwAebWarnSetConfigState 0;
BA_ "GenSigTimeoutMsg_HU_Mid_X445" SG_ 471 FcwAebWarnSetConfigState 0;
BA_ "GenSigTimeoutTime_HU_High_X445" SG_ 471 FcwAebWarnSetConfigState 0;
BA_ "GenSigTimeoutTime_HU_Mid_X445" SG_ 471 FcwAebWarnSetConfigState 0;
BA_ "GenSigTimeoutMsg_IVI" SG_ 471 FcwAebWarnSetConfigState 0;
BA_ "GenSigTimeoutTime_IVI" SG_ 471 FcwAebWarnSetConfigState 0;
BA_ "GenSigTimeoutTime_HU_Mid_X451" SG_ 471 TsrOnOffConfigState 0;
BA_ "GenSigTimeoutTime_HU_High_X451" SG_ 471 TsrOnOffConfigState 0;
BA_ "GenSigTimeoutTime_HU_B" SG_ 471 TsrOnOffConfigState 0;
BA_ "GenSigTimeoutTime_HU_A" SG_ 471 TsrOnOffConfigState 0;
BA_ "GenSigTimeoutMsg_HU_Mid_X451" SG_ 471 TsrOnOffConfigState 0;
BA_ "GenSigTimeoutMsg_HU_High_X451" SG_ 471 TsrOnOffConfigState 0;
BA_ "GenSigTimeoutMsg_HU_B" SG_ 471 TsrOnOffConfigState 0;
BA_ "GenSigTimeoutMsg_HU_A" SG_ 471 TsrOnOffConfigState 0;
BA_ "GenSigSendType" SG_ 471 TsrOnOffConfigState 2;
BA_ "GenSigTimeoutMsg_HU_High_X445" SG_ 471 TsrOnOffConfigState 0;
BA_ "GenSigTimeoutMsg_HU_Mid_X445" SG_ 471 TsrOnOffConfigState 0;
BA_ "GenSigTimeoutTime_HU_High_X445" SG_ 471 TsrOnOffConfigState 0;
BA_ "GenSigTimeoutTime_HU_Mid_X445" SG_ 471 TsrOnOffConfigState 0;
BA_ "GenSigTimeoutMsg_IVI" SG_ 471 TsrOnOffConfigState 0;
BA_ "GenSigTimeoutTime_IVI" SG_ 471 TsrOnOffConfigState 0;
BA_ "GenSigTimeoutTime_HU_Mid_X451" SG_ 471 LdwOnOffConfigState 0;
BA_ "GenSigTimeoutTime_HU_High_X451" SG_ 471 LdwOnOffConfigState 0;
BA_ "GenSigTimeoutTime_HU_B" SG_ 471 LdwOnOffConfigState 0;
BA_ "GenSigTimeoutTime_HU_A" SG_ 471 LdwOnOffConfigState 0;
BA_ "GenSigTimeoutMsg_HU_Mid_X451" SG_ 471 LdwOnOffConfigState 0;
BA_ "GenSigTimeoutMsg_HU_High_X451" SG_ 471 LdwOnOffConfigState 0;
BA_ "GenSigTimeoutMsg_HU_B" SG_ 471 LdwOnOffConfigState 0;
BA_ "GenSigTimeoutMsg_HU_A" SG_ 471 LdwOnOffConfigState 0;
BA_ "GenSigSendType" SG_ 471 LdwOnOffConfigState 2;
BA_ "GenSigTimeoutMsg_HU_High_X445" SG_ 471 LdwOnOffConfigState 0;
BA_ "GenSigTimeoutMsg_HU_Mid_X445" SG_ 471 LdwOnOffConfigState 0;
BA_ "GenSigTimeoutTime_HU_High_X445" SG_ 471 LdwOnOffConfigState 0;
BA_ "GenSigTimeoutTime_HU_Mid_X445" SG_ 471 LdwOnOffConfigState 0;
BA_ "GenSigTimeoutMsg_IVI" SG_ 471 LdwOnOffConfigState 0;
BA_ "GenSigTimeoutTime_IVI" SG_ 471 LdwOnOffConfigState 0;
BA_ "GenSigTimeoutTime_HU_Mid_X451" SG_ 471 HbaOnOffConfigState 0;
BA_ "GenSigTimeoutTime_HU_High_X451" SG_ 471 HbaOnOffConfigState 0;
BA_ "GenSigTimeoutTime_HU_B" SG_ 471 HbaOnOffConfigState 0;
BA_ "GenSigTimeoutTime_HU_A" SG_ 471 HbaOnOffConfigState 0;
BA_ "GenSigTimeoutMsg_HU_Mid_X451" SG_ 471 HbaOnOffConfigState 0;
BA_ "GenSigTimeoutMsg_HU_High_X451" SG_ 471 HbaOnOffConfigState 0;
BA_ "GenSigTimeoutMsg_HU_B" SG_ 471 HbaOnOffConfigState 0;
BA_ "GenSigTimeoutMsg_HU_A" SG_ 471 HbaOnOffConfigState 0;
BA_ "GenSigSendType" SG_ 471 HbaOnOffConfigState 2;
BA_ "GenSigTimeoutMsg_HU_High_X445" SG_ 471 HbaOnOffConfigState 0;
BA_ "GenSigTimeoutMsg_HU_Mid_X445" SG_ 471 HbaOnOffConfigState 0;
BA_ "GenSigTimeoutTime_HU_High_X445" SG_ 471 HbaOnOffConfigState 0;
BA_ "GenSigTimeoutTime_HU_Mid_X445" SG_ 471 HbaOnOffConfigState 0;
BA_ "GenSigTimeoutMsg_IVI" SG_ 471 HbaOnOffConfigState 0;
BA_ "GenSigTimeoutTime_IVI" SG_ 471 HbaOnOffConfigState 0;
BA_ "GenSigTimeoutTime_HU_Mid_X451" SG_ 471 FcwAebOnOffConfigState 0;
BA_ "GenSigTimeoutTime_HU_High_X451" SG_ 471 FcwAebOnOffConfigState 0;
BA_ "GenSigTimeoutTime_HU_B" SG_ 471 FcwAebOnOffConfigState 0;
BA_ "GenSigTimeoutTime_HU_A" SG_ 471 FcwAebOnOffConfigState 0;
BA_ "GenSigTimeoutMsg_HU_Mid_X451" SG_ 471 FcwAebOnOffConfigState 0;
BA_ "GenSigTimeoutMsg_HU_High_X451" SG_ 471 FcwAebOnOffConfigState 0;
BA_ "GenSigTimeoutMsg_HU_B" SG_ 471 FcwAebOnOffConfigState 0;
BA_ "GenSigTimeoutMsg_HU_A" SG_ 471 FcwAebOnOffConfigState 0;
BA_ "GenSigSendType" SG_ 471 FcwAebOnOffConfigState 2;
BA_ "GenSigTimeoutMsg_HU_High_X445" SG_ 471 FcwAebOnOffConfigState 0;
BA_ "GenSigTimeoutMsg_HU_Mid_X445" SG_ 471 FcwAebOnOffConfigState 0;
BA_ "GenSigTimeoutTime_HU_High_X445" SG_ 471 FcwAebOnOffConfigState 0;
BA_ "GenSigTimeoutTime_HU_Mid_X445" SG_ 471 FcwAebOnOffConfigState 0;
BA_ "GenSigTimeoutMsg_IVI" SG_ 471 FcwAebOnOffConfigState 0;
BA_ "GenSigTimeoutTime_IVI" SG_ 471 FcwAebOnOffConfigState 0;
BA_ "GenSigTimeoutTime_HU_B" SG_ 592 AccInfoDisp 0;
BA_ "GenSigTimeoutTime_HU_A" SG_ 592 AccInfoDisp 0;
BA_ "GenSigTimeoutMsg_HU_B" SG_ 592 AccInfoDisp 0;
BA_ "GenSigTimeoutMsg_HU_A" SG_ 592 AccInfoDisp 0;
BA_ "GenSigSendType" SG_ 592 AccInfoDisp 7;
BA_ "GenSigCycleTimeActive" SG_ 592 AccInfoDisp 100;
BA_ "GenSigCycleTime" SG_ 592 AccInfoDisp 100;
BA_ "GenSigTimeoutTime_HU_B" SG_ 592 AccWarnDisp 0;
BA_ "GenSigTimeoutTime_HU_A" SG_ 592 AccWarnDisp 0;
BA_ "GenSigTimeoutMsg_HU_B" SG_ 592 AccWarnDisp 0;
BA_ "GenSigTimeoutMsg_HU_A" SG_ 592 AccWarnDisp 0;
BA_ "GenSigSendType" SG_ 592 AccWarnDisp 7;
BA_ "GenSigCycleTimeActive" SG_ 592 AccWarnDisp 100;
BA_ "GenSigCycleTime" SG_ 592 AccWarnDisp 100;
BA_ "GenSigTimeoutTime_HU_B" SG_ 592 AccSetDst 0;
BA_ "GenSigTimeoutTime_HU_A" SG_ 592 AccSetDst 0;
BA_ "GenSigTimeoutMsg_HU_B" SG_ 592 AccSetDst 0;
BA_ "GenSigTimeoutMsg_HU_A" SG_ 592 AccSetDst 0;
BA_ "GenSigSendType" SG_ 592 AccSetDst 7;
BA_ "GenSigCycleTimeActive" SG_ 592 AccSetDst 100;
BA_ "GenSigCycleTime" SG_ 592 AccSetDst 100;
BA_ "GenSigTimeoutTime_HU_B" SG_ 592 AccObjValid 0;
BA_ "GenSigTimeoutTime_HU_A" SG_ 592 AccObjValid 0;
BA_ "GenSigTimeoutMsg_HU_B" SG_ 592 AccObjValid 0;
BA_ "GenSigTimeoutMsg_HU_A" SG_ 592 AccObjValid 0;
BA_ "GenSigSendType" SG_ 592 AccObjValid 7;
BA_ "GenSigCycleTimeActive" SG_ 592 AccObjValid 100;
BA_ "GenSigCycleTime" SG_ 592 AccObjValid 100;
BA_ "GenSigTimeoutTime_HU_B" SG_ 592 AccObjDistStatus 0;
BA_ "GenSigTimeoutTime_HU_A" SG_ 592 AccObjDistStatus 0;
BA_ "GenSigTimeoutMsg_HU_B" SG_ 592 AccObjDistStatus 0;
BA_ "GenSigTimeoutMsg_HU_A" SG_ 592 AccObjDistStatus 0;
BA_ "GenSigSendType" SG_ 592 AccObjDistStatus 7;
BA_ "GenSigCycleTimeActive" SG_ 592 AccObjDistStatus 100;
BA_ "GenSigCycleTime" SG_ 592 AccObjDistStatus 100;
BA_ "GenSigTimeoutTime_HU_B" SG_ 592 AccObjDist 0;
BA_ "GenSigTimeoutTime_HU_A" SG_ 592 AccObjDist 0;
BA_ "GenSigTimeoutMsg_HU_B" SG_ 592 AccObjDist 0;
BA_ "GenSigTimeoutMsg_HU_A" SG_ 592 AccObjDist 0;
BA_ "GenSigSendType" SG_ 592 AccObjDist 7;
BA_ "GenSigCycleTimeActive" SG_ 592 AccObjDist 100;
BA_ "GenSigCycleTime" SG_ 592 AccObjDist 100;
BA_ "GenSigSendType" SG_ 592 TsrSysStates 7;
BA_ "GenSigCycleTimeActive" SG_ 592 TsrSysStates 100;
BA_ "GenSigCycleTime" SG_ 592 TsrSysStates 100;
BA_ "GenSigSendType" SG_ 592 TsrDspSpd 7;
BA_ "GenSigCycleTimeActive" SG_ 592 TsrDspSpd 100;
BA_ "GenSigCycleTime" SG_ 592 TsrDspSpd 100;
BA_ "GenSigSendType" SG_ 592 TsrDisNoPass 7;
BA_ "GenSigCycleTimeActive" SG_ 592 TsrDisNoPass 100;
BA_ "GenSigCycleTime" SG_ 592 TsrDisNoPass 100;
BA_ "GenSigSendType" SG_ 592 LkaLnWrnStates 7;
BA_ "GenSigCycleTimeActive" SG_ 592 LkaLnWrnStates 100;
BA_ "GenSigCycleTime" SG_ 592 LkaLnWrnStates 100;
BA_ "GenSigSendType" SG_ 592 LkaLdwLaneRecogn 7;
BA_ "GenSigCycleTimeActive" SG_ 592 LkaLdwLaneRecogn 100;
BA_ "GenSigCycleTime" SG_ 592 LkaLdwLaneRecogn 100;
BA_ "GenSigSendType" SG_ 592 HbaStates 7;
BA_ "GenSigCycleTimeActive" SG_ 592 HbaStates 100;
BA_ "GenSigCycleTime" SG_ 592 HbaStates 100;
BA_ "GenSigStartValue" SG_ 592 TsrOnOffState 1;
BA_ "GenSigSendType" SG_ 592 TsrOnOffState 7;
BA_ "GenSigCycleTimeActive" SG_ 592 TsrOnOffState 100;
BA_ "GenSigCycleTime" SG_ 592 TsrOnOffState 100;
BA_ "GenSigSendType" SG_ 592 HbaOnOffState 7;
BA_ "GenSigCycleTimeActive" SG_ 592 HbaOnOffState 100;
BA_ "GenSigCycleTime" SG_ 592 HbaOnOffState 100;
BA_ "GenSigSendType" SG_ 592 LkaLdwSysStates 7;
BA_ "GenSigCycleTimeActive" SG_ 592 LkaLdwSysStates 100;
BA_ "GenSigCycleTime" SG_ 592 LkaLdwSysStates 100;
BA_ "GenSigStartValue" SG_ 592 LdwOnOffState 1;
BA_ "GenSigSendType" SG_ 592 LdwOnOffState 7;
BA_ "GenSigCycleTimeActive" SG_ 592 LdwOnOffState 100;
BA_ "GenSigCycleTime" SG_ 592 LdwOnOffState 100;
BA_ "GenSigSendType" SG_ 592 FcmPresence 7;
BA_ "GenSigCycleTimeActive" SG_ 592 FcmPresence 100;
BA_ "GenSigCycleTime" SG_ 592 FcmPresence 100;
BA_ "GenSigTimeoutTime_HU_B" SG_ 384 AccStopReq 0;
BA_ "GenSigTimeoutTime_HU_A" SG_ 384 AccStopReq 0;
BA_ "GenSigTimeoutMsg_HU_B" SG_ 384 AccStopReq 0;
BA_ "GenSigTimeoutMsg_HU_A" SG_ 384 AccStopReq 0;
BA_ "GenSigSendType" SG_ 384 AccStopReq 7;
BA_ "GenSigCycleTimeActive" SG_ 384 AccStopReq 20;
BA_ "GenSigCycleTime" SG_ 384 AccStopReq 20;
BA_ "GenSigSendType" SG_ 384 LkaHandsOffVisual 7;
BA_ "GenSigCycleTimeActive" SG_ 384 LkaHandsOffVisual 20;
BA_ "GenSigCycleTime" SG_ 384 LkaHandsOffVisual 20;
BA_ "GenSigSendType" SG_ 384 LkaHandsOffAudio 7;
BA_ "GenSigCycleTimeActive" SG_ 384 LkaHandsOffAudio 20;
BA_ "GenSigCycleTime" SG_ 384 LkaHandsOffAudio 20;
BA_ "GenSigSendType" SG_ 384 AccToR 7;
BA_ "GenSigCycleTimeActive" SG_ 384 AccToR 20;
BA_ "GenSigCycleTime" SG_ 384 AccToR 20;
BA_ "GenSigSendType" SG_ 384 DecelCmdStatus 7;
BA_ "GenSigCycleTimeActive" SG_ 384 DecelCmdStatus 20;
BA_ "GenSigCycleTime" SG_ 384 DecelCmdStatus 20;
BA_ "GenSigSendType" SG_ 384 DecelCmdAeb 7;
BA_ "GenSigCycleTimeActive" SG_ 384 DecelCmdAeb 20;
BA_ "GenSigCycleTime" SG_ 384 DecelCmdAeb 20;
BA_ "GenSigSendType" SG_ 384 AebDbsLevelFcm 7;
BA_ "GenSigCycleTimeActive" SG_ 384 AebDbsLevelFcm 20;
BA_ "GenSigCycleTime" SG_ 384 AebDbsLevelFcm 20;
BA_ "GenSigSendType" SG_ 384 MSG_CNT_AEB 7;
BA_ "GenSigCycleTimeActive" SG_ 384 MSG_CNT_AEB 20;
BA_ "GenSigCycleTime" SG_ 384 MSG_CNT_AEB 20;
BA_ "GenSigSendType" SG_ 384 CRC_AEB 7;
BA_ "GenSigCycleTimeActive" SG_ 384 CRC_AEB 20;
BA_ "GenSigCycleTime" SG_ 384 CRC_AEB 20;
BA_ "GenSigSendType" SG_ 384 AccSysFail 7;
BA_ "GenSigCycleTimeActive" SG_ 384 AccSysFail 20;
BA_ "GenSigCycleTime" SG_ 384 AccSysFail 20;
BA_ "GenSigSendType" SG_ 384 AccMod 7;
BA_ "GenSigCycleTimeActive" SG_ 384 AccMod 20;
BA_ "GenSigCycleTime" SG_ 384 AccMod 20;
BA_ "GenSigSendType" SG_ 384 AccMainMod 7;
BA_ "GenSigCycleTimeActive" SG_ 384 AccMainMod 20;
BA_ "GenSigCycleTime" SG_ 384 AccMainMod 20;
BA_ "GenSigSendType" SG_ 384 AebWarnCmdFcm 7;
BA_ "GenSigCycleTimeActive" SG_ 384 AebWarnCmdFcm 20;
BA_ "GenSigCycleTime" SG_ 384 AebWarnCmdFcm 20;
BA_ "GenSigSendType" SG_ 384 FcwAebFailInfoFcm 7;
BA_ "GenSigCycleTimeActive" SG_ 384 FcwAebFailInfoFcm 20;
BA_ "GenSigCycleTime" SG_ 384 FcwAebFailInfoFcm 20;
BA_ "GenSigStartValue" SG_ 384 FcwAebOnOffState 1;
BA_ "GenSigSendType" SG_ 384 FcwAebOnOffState 7;
BA_ "GenSigCycleTimeActive" SG_ 384 FcwAebOnOffState 20;
BA_ "GenSigCycleTime" SG_ 384 FcwAebOnOffState 20;
VAL_ 1157 IPC_MTO_Failure_Status 3 "Reserved" 2 "Failure healed Ageing in progress" 1 "Failure matured & DTC in memory" 0 "Failure is not detected" ;
VAL_ 1157 AMT_AT_DCT_MRC_Failure_Status 3 "Reserved" 2 "Failurehealed Ageing in progress" 1 "Failure matured & DTC in memory" 0 "Faiulure is not detected " ;
VAL_ 1157 AMT_AT_DCT_CRC_Failure_Status 3 "Reserved" 2 "Failurehealed Ageing in progress" 1 "Failure matured & DTC in memory" 0 "Faiulure is not detected " ;
VAL_ 1157 AMT_AT_DCT_MTO_Failure_Status 3 "Reserved" 2 "Failure healed Ageing in progress" 1 "Failure matured & DTC in memory" 0 "Failure is not detected" ;
VAL_ 1157 GSM_BO_Failure_Status 3 "Reserved" 2 "Failure healed Ageing in progress" 1 "Failure matured & DTC in memory" 0 "Failure is not detected" ;
VAL_ 749 AccObjRelSpdStatus 3 "Signal not available" 2 "Signal is implausible" 1 "Reserved" 0 "Signal is Plausible" ;
VAL_ 749 AccEnableCondition 15 "Reserved" 14 "Reserved" 13 "Reserved" 12 "Reserved" 11 "Reserved" 10 "Reserved" 9 "Reserved" 8 "Reserved" 7 "Wear seat belt to engage ACC" 6 "Enable AEB to engage ACC" 5 "Close driver door to engage Adaptive cruise control" 4 "Set speed higher than maximum allowed speed" 3 "ACC disabled due to ESC OFF" 2 "ACC conditions not met" 1 "Increase vehicle speed to engage ACC" 0 "Default" ;
VAL_ 749 AccVehSetSpdStatus 3 "Signal not available" 2 "Signal is implausible" 1 "Reserved" 0 "Signal is Plausible" ;
VAL_ 1310 DriverAttentionLevel 7 "Reserved Bit" 6 "Reserved Bit" 5 "Level 5" 4 "Level 4" 3 "Level 3" 2 "Level 2" 1 "Level 1" 0 "Default" ;
VAL_ 1310 CompassDirection 7 "NW" 6 "W" 5 "SW" 4 "S" 3 "SE" 2 "E" 1 "NE" 0 "N" ;
VAL_ 526 AccLkaSwitchState 3 "Invalid" 2 "No Action Required" 1 "Switch Stuck" 0 "Valid Press" ;
VAL_ 526 AdasSteeringSwitchState 15 "Reserved" 14 "Reserved" 13 "Reserved" 12 "Reserved" 11 "Reserved" 10 "Reserved" 9 "ACC Timegap/Headway Gap Long Pressed" 8 "LKA Switch Pressed" 7 "ACC Timegap/Headway Gap Short Pressed" 6 "SET - Long Press" 5 "SET - Short Press" 4 "SET + Long Press" 3 "SET + Short Press" 2 "ACC Cancel/Resume Pressed" 1 "ACC ON/OFF Pressed" 0 "No Action Required" ;
VAL_ 380 DelTrqReqDstStatus 3 "Signal not available" 2 "Information given is implausible" 1 "Reserved for future use" 0 "Information given is correct" ;
VAL_ 380 AccEngaged 1 "ON" 0 "OFF" ;
VAL_ 380 AccTorqueReqEnable 1 "Enable ACC torque request" 0 "No request" ;
VAL_ 267 PlausibilityTrqReq 1 "TorqueReq_NotValid" 0 "TorqueReq_Valid" ;
VAL_ 267 EngTrqMinStatus 3 "Signal not available" 2 "Value is impluasible" 1 "Reserved" 0 "Value is valid" ;
VAL_ 864 BcmPotPowerTailgateState 3 "Stopped (during open/close action)" 2 "Closing" 1 "Opening" 0 "Idle(fully closed/fully open)" ;
VAL_ 864 PotHeightAdjState 7 "Reserve" 6 "100% open (Default =  Fully Open Soft Stop)" 5 "90% open" 4 "80% open" 3 "70% open" 2 "60% open" 1 "50% open" 0 "No User Height Set" ;
VAL_ 864 PotGestOnOffState 1 "Enable Power Tailgate Gesture feature" 0 "Disable Power Tailgate Gesture feature" ;
VAL_ 864 PotBuzzOnOffState 1 "POT buzzer function ON" 0 "POT buzzer function OFF" ;
VAL_ 864 PotFuncState 1 "POT function Present" 0 "POT function Absent" ;
VAL_ 864 BCmHuSunShadeStateStatus 3 "Signal Not Available(SNA)" 2 "Implausible" 1 "Reserved" 0 "Plausible" ;
VAL_ 864 BCmHuSunShadeState 7 "Reserved Bit" 6 "Reserved Bit" 5 "Reserved Bit" 4 "SunShade Function Not Available" 3 "SunShade Closing (Ongoing Closing transition)" 2 "SunShade opening (Ongoing Opening transition)" 1 "SunShade opened" 0 "SunShade Fully Closed" ;
VAL_ 864 BCmHuSunRoofStateStatus 3 "Signal Not Available(SNA)" 2 "Implausible" 1 "Reserved" 0 "Plausible" ;
VAL_ 864 BCmHuSunRoofState 7 "Reserved Bit" 6 "Reserved Bit" 5 "Reserved Bit" 4 "SunRoof Function Not Available" 3 "Sunroof Closing (Ongoing Closing transition)" 2 "Sunroof opening (Ongoing Opening transition)" 1 "Sunroof opened" 0 "Sunroof Fully Closed" ;
VAL_ 864 BCmHuGotoEntryExitPosState 1 "Easy Entry Exit function ON" 0 "Easy Entry Exit function OFF" ;
VAL_ 864 DrvMemSeatFunState 1 "Driver Memory Seat function Present" 0 "Driver Memory Seat function Absent" ;
VAL_ 864 MemRecallCancelSeat 1 "Cancelled" 0 "Not Cancelled" ;
VAL_ 864 MemoryPosStoreReqStatus 3 "Signal Not Available" 2 "Implausible" 1 "Reserved" 0 "Plausible" ;
VAL_ 864 MemoryPosStoreReq 7 "Reserved Bit" 6 "Reserved Bit" 5 "Reserved Bit" 4 "Reserved Bit" 3 "Memory 3 Store" 2 "Memory 2 Store" 1 "Memory 1 Store" 0 "Idle" ;
VAL_ 864 MemoryPosLoadReqStatus 3 "Signal Not Available" 2 "Implausible" 1 "Reserved" 0 "Plausible" ;
VAL_ 864 MemoryPosLoadReq 7 "Reserved Bit" 6 "Reserved Bit" 5 "Reserved Bit" 4 "Reserved Bit" 3 "Memory 3 Load " 2 "Memory 2 Load " 1 "Memory 1 Load " 0 "Idle" ;
VAL_ 748 DoorStateRearRHStatus_100ms 3 "Signal not available" 2 "Reserved" 1 "Reserved" 0 "Value is plausible" ;
VAL_ 748 DoorStateRearRH_100ms 1 "Open" 0 "Close" ;
VAL_ 748 DoorStateRearLHStatus_100ms 3 "Signal not available" 2 "Reserved" 1 "Reserved" 0 "Value is plausible" ;
VAL_ 748 DoorStateRearLH_100ms 1 "open" 0 "close" ;
VAL_ 748 DoorStatePassStatus_100ms 3 "Signal not avialable" 2 "Reserved" 1 "Reserved" 0 "Value is plausible" ;
VAL_ 748 DoorStatePass_100ms 1 "Open" 0 "Close" ;
VAL_ 748 DoorStateDrvrStatus_100ms 3 "Signal not available" 2 "Reserved" 1 "Reserved " 0 "Signal is plausible" ;
VAL_ 748 DoorStateDrvr_100ms 1 "open" 0 "Close" ;
VAL_ 456 ETcHuHiFanSpdConfigValue 4 "Fan Speed 4" 3 "Fan Speed 3" 2 "Fan Speed 2" 1 "Fan Speed 1" 0 "Fan Speed 0" ;
VAL_ 456 ETcHuLowFanSpdConfigValue 4 "Fan Speed 4" 3 "Fan Speed 3" 2 "Fan Speed 2" 1 "Fan Speed 1" 0 "Fan Speed 0" ;
VAL_ 456 ETcHuHiTempConfigValue 15 "Hot Level Request 8" 14 "Hot Level Request 7" 13 "Hot Level Request 6" 12 "Hot Level Request 5" 11 "Hot Level Request 4" 10 "Hot Level Request 3" 9 "Hot Level Request 2" 8 "Hot Level Request 1" 7 "Cool Level Request 1" 6 "Cool Level Request 2" 5 "Cool Level Request 3" 4 "Cool Level Request 4" 3 "Cool Level Request 5" 2 "Cool Level Request 6" 1 "Cool Level Request 7" 0 "Cool Level Request 8" ;
VAL_ 456 ETcHuLowTempConfigValue 15 "Hot Level Request 8" 14 "Hot Level Request 7" 13 "Hot Level Request 6" 12 "Hot Level Request 5" 11 "Hot Level Request 4" 10 "Hot Level Request 3" 9 "Hot Level Request 2" 8 "Hot Level Request 1" 7 "Cool Level Request 1" 6 "Cool Level Request 2" 5 "Cool Level Request 3" 4 "Cool Level Request 4" 3 "Cool Level Request 5" 2 "Cool Level Request 6" 1 "Cool Level Request 7" 0 "Cool Level Request 8" ;
VAL_ 572 CCmHuUserInterventionStatusFlag 31 "Reserved" 30 "Reserved" 29 "Reserved" 28 "Reserved" 27 "Reserved" 26 "Reserved" 25 "Reserved" 24 "Reserved" 23 "Reserved" 22 "Reserved" 21 "Reserved" 20 "Reserved" 19 "Reserved" 18 "Autodefog User Intervention flag " 17 "Rear Blower Flag" 16 "FL Seat Ventilation Flag" 15 "FR Seat Ventilation Flag" 14 "Express Cool Flag" 13 "Rear defog Flag" 12 "Temperature Wheel  flag" 11 "Dual button flag" 10 "Fan speed wheel flag" 9 "Temperature Wheel driver flag" 8 "Temperature Wheel Passenger flag" 7 "Distribution button flag" 6 "Recirculation button flag" 5 "Maxdefrost button flag" 4 "Off button flag" 3 "Auto button flag" 2 "Econ button flag" 1 "AC Button flag" 0 "CCmHuUserInterventionStatusFlagClear" ;
VAL_ 572 CcmHuUserInterventionBeep 1 "Beep" 0 "No Beep" ;
VAL_ 572 CCmHuMaxDefrstSwitchStatus 1 "Max defrost ON" 0 "Max defrost OFF" ;
VAL_ 572 CCMHuFreshAirRecircSwitchStatus 3 "Reserved" 2 "Fresh Air ON" 1 "Recirculation with AQS (applicable for dual zone FATC)" 0 "Recirculation ON" ;
VAL_ 572 CCmHuDistribSwitchStatus 7 "Reserved" 6 "Reserved" 5 "DefrostMode Status
" 4 "LegDefrostMode Status" 3 "LegMode Status" 2 "Chest-LegMode Status" 1 "ChestModeStatus" 0 "Reserved" ;
VAL_ 572 CCmHuCtrlPnlStatus 1 "Control Panel ON" 0 "Control Panel OFF" ;
VAL_ 572 CCmHuChangeBit 1 "Change bit OFF" 0 "Change bit ON" ;
VAL_ 572 CCmHuAutoSwitchStatus 1 "Auto is ON" 0 "Auto is OFF" ;
VAL_ 572 CCmHuAirConCompSwitchStatus 1 "AC is ON" 0 "AC is OFF" ;
VAL_ 572 CCmExpressCoolVoiceAlert 7 "Reserved" 6 "Low Ambient Temperature / Its Already Cold Outside" 5 "Roll Up the windows if down" 4 "Express Cooling OFF, Roll Up the windows if DOWN" 3 "Express Cooling ON windows may roll DOWN" 2 "Express Cooling OFF" 1 "Express Cooling ON" 0 "No Request" ;
VAL_ 572 ETcHuFanSpdState 4 "Fan Speed 4" 3 "Fan Speed 3" 2 "Fan Speed 2" 1 "Fan Speed 1" 0 "Fan Speed 0" ;
VAL_ 572 ETcHuTempWhlStatus 3 "Signal not available" 2 "Implausible" 1 "Reserved for future use" 0 "Plausible and signal is correct" ;
VAL_ 572 ETcHuTempWhlState 15 "Hot Level 8" 14 "Hot Level 7" 13 "Hot Level 6" 12 "Hot Level 5" 11 "Hot Level 4" 10 "Hot Level 3" 9 "Hot Level 2" 8 "Hot Level 1 " 7 "Cool Level 1" 6 "Cool Level 2" 5 "Cool Level 3" 4 "Cool Level 4" 3 "Cool Level 5" 2 "Cool Level 6" 1 "Cool Level 7" 0 "Cool Level 8" ;
VAL_ 1292 CurrentState_ESCL 1 "Normal Operation State" 0 "Repeat Messgae State" ;
VAL_ 1292 ActiveWakeUp_ESCL 1 "Node has  woken up the network(Active wakeup)" 0 "Node has not woken up the network(Passive wakeup)" ;
VAL_ 1292 RepeatMessageReq_ESCL 1 "Reserved" 0 "Repeat message state not requested" ;
VAL_ 1292 PreviousState_ESCL 7 "Reserved" 6 "Reserved" 5 "Reserved" 4 "Bus Sleep State" 3 "Prepare Bus Sleep State" 2 "Ready Sleep State" 1 "Normal Operation State" 0 "Repeat Message State" ;
VAL_ 659 TCUKeepNEtinAfterRunGSA 1 "Netwrok required" 0 "Netwrok not required" ;
VAL_ 524 RcwOnOffConfigState 3 "Reserved" 2 "Don't Care" 1 "ON" 0 "OFF" ;
VAL_ 524 BsdOnOffConfigState 3 "Reserved" 2 "Don't Care" 1 "ON" 0 "OFF" ;
VAL_ 524 DoaOnOffConfigState 3 "Reserved" 2 "Don't Care" 1 "ON" 0 "OFF" ;
VAL_ 524 RctaOnOffConfigState 3 "Reserved" 2 "Don't Care" 1 "ON" 0 "OFF" ;
VAL_ 593 RLRadarPresence 1 "Reserved" 0 "RLRadar Present" ;
VAL_ 593 RctaStates 7 "Reserved" 6 "System minor failure" 5 "Reserved" 4 "System Blockage" 3 "System Failure" 2 "System Active" 1 "System Passive" 0 "System is Off" ;
VAL_ 593 RctaOnOffState 3 "Reserved" 2 "Not Present" 1 "ON" 0 "OFF" ;
VAL_ 593 RctaIndRight 3 "Reserved" 2 "Error Indicator" 1 "Warning On" 0 "Warning is Off" ;
VAL_ 593 RctaIndLeft 3 "Reserved" 2 "Error Indicator" 1 "Warning On" 0 "Warning is Off" ;
VAL_ 593 RcwWarning 3 "Reserved" 2 "RCW warning level2" 1 "RCW warning level1" 0 "No RCW Warning" ;
VAL_ 593 RcwStates 7 "Reserved" 6 "Reserved" 5 "Reserved" 4 "System Blockage" 3 "System Failure" 2 "System Active" 1 "System Passive" 0 "System is Off" ;
VAL_ 593 RcwOnOffState 3 "Reserved" 2 "Not Present" 1 "ON" 0 "OFF" ;
VAL_ 593 BsdStates 7 "Reserved" 6 "System minor failure" 5 "Reserved" 4 "System Blockage" 3 "System Failure" 2 "System Active" 1 "System Passive" 0 "System is Off" ;
VAL_ 593 BsdSoundRight 1 "Speaker ON" 0 "Speaker OFF" ;
VAL_ 593 BsdSoundLeft 1 "Speaker ON" 0 "Speaker OFF" ;
VAL_ 593 BsdOnOffState 3 "Reserved" 2 "Not Present" 1 "ON" 0 "OFF" ;
VAL_ 593 BsdIndStatus 1 "Indicator Failure " 0 "Normal " ;
VAL_ 593 BsdIndRight 3 "Error Indicator" 2 "Indicator blinking(warning)" 1 "Indicator on (information)" 0 "Indicator output off" ;
VAL_ 593 BsdIndLeft 3 "Error Indicator" 2 "Indicator blinking(warning)" 1 "Indicator on (information)" 0 "Indicator output off" ;
VAL_ 593 DoaWarnRight 3 "Reserved" 2 "DOA Right Warning Blink" 1 "DOA Right Warning ON " 0 "OFF" ;
VAL_ 593 DoaWarnLeft 3 "Reserved" 2 "DOA Left Warning Blink" 1 "DOA Left Warning ON " 0 "OFF" ;
VAL_ 593 DoaStates 3 "Reserved" 2 "System Not Supported" 1 "System On" 0 "System Off" ;
VAL_ 593 DoaOnOffState 3 "Reserved" 2 "Not Present" 1 "ON" 0 "OFF" ;
VAL_ 1291 ActiveWakeUp_SRR 1 "Node has  woken up the network(Active wakeup)" 0 "Node has not woken up the network(Passive wakeup)" ;
VAL_ 1291 CurrentState_SRR 1 "Normal Operation State" 0 "Repeat Message State" ;
VAL_ 1291 PreviousState_SRR 7 "Reserved" 6 "Reserved" 5 "Reserved" 4 " Bus Sleep State" 3 "Prepare Bus Sleep State" 2 "Ready Sleep State" 1 "Normal Operation State" 0 "Repeat Message State" ;
VAL_ 1291 RepeatMessageReq_SRR 1 "Repeat message state requested" 0 "Repeat message state not requested" ;
VAL_ 468 PotSwRkeOnOffReq 3 "Reserve" 2 "Enable POT by RKE switch User Req" 1 "Disable POT by RKE switch User Req" 0 "No Action Required" ;
VAL_ 468 PotHeightAdjReq 7 "Description for the value '0x7'" 6 "100% open (Default =  Fully Open Soft Stop)" 5 "90% open" 4 "80% open" 3 "70% open" 2 "60% open" 1 "50% open" 0 "No User Height Set Req" ;
VAL_ 468 PotGestOnOffReq 3 "Reserve" 2 "Enable POT by Gesture User Req" 1 "Disable POT by Gesture User Req" 0 "No Action Required" ;
VAL_ 468 PotBuzzOnOffReq 3 "Reserve" 2 "POT buzzer function ON" 1 "POT buzzer function OFF" 0 "No Action Required" ;
VAL_ 468 RcwReqType 3 "Don't Care" 2 "Settings Update" 1 "Config Query" 0 "Config Ack" ;
VAL_ 468 RcwOnOffStateReq 3 "Reserved" 2 "Reserved" 1 "ON" 0 "OFF" ;
VAL_ 468 RcwOnOffStateAck 3 "Reserved" 2 "Reserved" 1 "ON" 0 "OFF" ;
VAL_ 468 RctaReqType 3 "Don't Care" 2 "Settings Update" 1 "Config Query" 0 "Config Ack" ;
VAL_ 468 RctaOnOffStateReq 3 "Reserved" 2 "Reserved" 1 "ON" 0 "OFF" ;
VAL_ 468 RctaOnOffStateAck 3 "Reserved" 2 "Reserved" 1 "ON" 0 "OFF" ;
VAL_ 468 DoaReqType 3 "Don't Care" 2 "Settings Update" 1 "Config Query" 0 "Config Ack" ;
VAL_ 468 DoaOnOffStateReq 3 "Reserved" 2 "Reserved" 1 "ON" 0 "OFF" ;
VAL_ 468 DoaOnOffStateAck 3 "Reserved" 2 "Reserved" 1 "ON" 0 "OFF" ;
VAL_ 468 BsdReqType 3 "Don't Care" 2 "Settings Update" 1 "Config Query" 0 "Config Ack" ;
VAL_ 468 BsdOnOffStateReq 3 "Reserved" 2 "Reserved" 1 "ON" 0 "OFF" ;
VAL_ 468 BsdOnOffStateAck 3 "Reserved" 2 "Reserved" 1 "ON" 0 "OFF" ;
VAL_ 468 FcwAebWarnSetStateReq 7 "Reserved" 6 "Reserved" 5 "Reserved" 4 "Reserved" 3 "Early" 2 "Normal" 1 "Late" 0 "Not Applied" ;
VAL_ 468 FcwAebWarnSetStateAck 7 "Reserved" 6 "Reserved" 5 "Reserved" 4 "Reserved" 3 "Early" 2 "Normal" 1 "Late" 0 "Not Applied" ;
VAL_ 468 FcwAebReqType 3 "Don't Care" 2 "Settings Update" 1 "Config Query" 0 "Config Ack" ;
VAL_ 468 FcwAebOnOffStateReq 3 "Reserved" 2 "ON(FCW/AEB)" 1 "ON(FCW)" 0 "OFF" ;
VAL_ 468 FcwAebOnOffStateAck 3 "Reserved" 2 "ON(FCW/AEB)" 1 "ON(FCW)" 0 "OFF" ;
VAL_ 468 TsrReqType 3 "Don't Care" 2 "Settings Update" 1 "Config Query" 0 "Config Ack" ;
VAL_ 468 TsrOnOffStateReq 3 "Reserved" 2 "Reserved" 1 "ON" 0 "OFF" ;
VAL_ 468 TsrOnOffStateAck 3 "Reserved" 2 "Reserved" 1 "ON" 0 "OFF" ;
VAL_ 468 LdwOnOffStateReq 3 "Reserved" 2 "LDW & LKA" 1 "LDW" 0 "OFF" ;
VAL_ 468 LdwReqType 3 "Don't Care" 2 "Settings Update" 1 "Config Query" 0 "Config Ack" ;
VAL_ 468 LdwOnOffStateAck 3 "Reserved" 2 "LDW & LKA" 1 "LDW" 0 "OFF" ;
VAL_ 468 HbaOnOffStateReq 3 "Reserved" 2 "Reserved" 1 "ON" 0 "OFF" ;
VAL_ 468 HbaReqType 3 "Don't Care" 2 "Settings Update" 1 "Config Query" 0 "Config Ack" ;
VAL_ 468 HbaOnOffStateAck 3 "Reserved" 2 "Reserved" 1 "ON" 0 "OFF" ;
VAL_ 471 LdwOnOffStateValidity 1 "Feature Enable not allowed" 0 "Don't Care" ;
VAL_ 471 AdasSteeringSwitchStateAck 15 "Reserved" 14 "Reserved" 13 "Reserved" 12 "Reserved" 11 "Reserved" 10 "Reserved" 9 "ACC Timegap/Headway Gap Long Pressed" 8 "LKA Switch Pressed" 7 "ACC Timegap/Headway Gap Short Pressed" 6 "SET - Long Press" 5 "SET - Short Press" 4 "SET + Long Press" 3 "SET + Short Press" 2 "ACC Cancel/Resume Pressed" 1 "ACC ON/OFF Pressed" 0 "No Action Required" ;
VAL_ 471 TsrSignalApplicability 1 "Valid" 0 "Don't Care" ;
VAL_ 471 FcwAebSignalApplicability 1 "Valid" 0 "Don't Care" ;
VAL_ 471 LdwSignalApplicability 1 "Valid" 0 "Don't Care" ;
VAL_ 471 HbaSignalApplicability 1 "Valid" 0 "Don't Care" ;
VAL_ 471 FcwAebOnOffConfigStateValidity 1 "Update attempt above threshold speed" 0 "Update Allowed" ;
VAL_ 471 FcwAebWarnSetConfigStateValidity 1 "Update attempt above threshold speed" 0 "Update Allowed" ;
VAL_ 471 FcwAebWarnSetConfigState 7 "Reserved" 6 "Reserved" 5 "Reserved" 4 "Reserved" 3 "Early" 2 "Normal" 1 "Late" 0 "Not Applied" ;
VAL_ 471 TsrOnOffConfigState 3 "Reserved" 2 "Reserved" 1 "ON" 0 "OFF" ;
VAL_ 471 LdwOnOffConfigState 3 "Reserved" 2 "LDW & LKA" 1 "LDW" 0 "OFF" ;
VAL_ 471 HbaOnOffConfigState 3 "Reserved" 2 "Reserved" 1 "ON" 0 "OFF" ;
VAL_ 471 FcwAebOnOffConfigState 3 "Reserved" 2 "ON(FCW/AEB)" 1 "ON(FCW)" 0 "OFF" ;
VAL_ 592 AccInfoDisp 7 "Invalid" 6 "Reserved" 5 "Reserved" 4 "Available to resume acceleration control" 3 "Object disappeared at low speed" 2 "CC mode" 1 "ACC mode" 0 "Default" ;
VAL_ 592 AccWarnDisp 3 "Reserved" 2 "No ACC entry condition" 1 "ACC disengaged" 0 "Default" ;
VAL_ 592 AccSetDst 7 "Reserved" 6 "Reserved" 5 "Reserved" 4 "Level-4" 3 "Level-3" 2 "Level-2" 1 "Level-1" 0 "Default" ;
VAL_ 592 AccObjValid 1 "Valid" 0 "Invalid" ;
VAL_ 592 AccObjDistStatus 3 "Signal not available" 2 "Signal is implausible" 1 "Reserved" 0 "Signal is Plausible" ;
VAL_ 592 TsrSysStates 3 "Condition Traffic Sign" 2 "Temporary Unavailable" 1 "Fail" 0 "Valid" ;
VAL_ 592 TsrDspSpd 597 "Grayed out" 596 "End of Speed Limit" 595 "No Recognition" 594 "Speed value in kmph (0x1 to 0x252)" 1 "Speed value in kmph (0x1 to 0x252)" 0 "Default" ;
VAL_ 592 TsrDisNoPass 3 "Reserved" 2 "Passing" 1 "No Passing" 0 "No Display" ;
VAL_ 592 LkaLnWrnStates 3 "Reserved	" 2 "Right Lane Departure Warning" 1 "Left Lane Departure Warning" 0 "No warning" ;
VAL_ 592 LkaLdwLaneRecogn 3 "Both Lane" 2 "Right Lane" 1 "Left Lane" 0 "No Recognition" ;
VAL_ 592 HbaStates 3 "HBA system failure" 2 "HBA ON & High Beam ON" 1 "HBA ON & High Beam OFF" 0 "HBA OFF" ;
VAL_ 592 TsrOnOffState 3 "Reserved" 2 "Not Present" 1 "ON" 0 "OFF" ;
VAL_ 592 HbaOnOffState 3 "Reserved" 2 "Not Present" 1 "ON" 0 "OFF" ;
VAL_ 592 LkaLdwSysStates 7 "Reserved" 6 "LKA Activation" 5 "System Not Calibrated" 4 "System fail" 3 "Warning" 2 "Active" 1 "Standby" 0 "System Off" ;
VAL_ 592 LdwOnOffState 3 "Not Present" 2 "LDW & LKA" 1 "LDW" 0 "OFF" ;
VAL_ 592 FcmPresence 1 "Reserved" 0 "FCM Present" ;
VAL_ 384 AccStopReq 1 "Stop Request" 0 "No Request" ;
VAL_ 384 LkaHandsOffVisual 1 "Hands OFF" 0 "Hands ON" ;
VAL_ 384 LkaHandsOffAudio 3 "Reserved" 2 "Reserved" 1 "Hands OFF" 0 "Hands ON" ;
VAL_ 384 AccToR 1 "Takeover request" 0 "No takeover request" ;
VAL_ 384 DecelCmdStatus 3 "Signal Not Available" 2 "Information given by FCM is implausible" 1 "Reserved for future use" 0 "Information given by FCM is correct" ;
VAL_ 384 AebDbsLevelFcm 3 "DBS Level 3" 2 "DBS Level 2" 1 "DBS Level 1" 0 "Not Active" ;
VAL_ 384 AccSysFail 3 "Permanent Failure" 2 "Temporary Not Available" 1 "Reserved" 0 "No Failure" ;
VAL_ 384 AccMod 3 "Shutoff" 2 "Override" 1 "Engaged" 0 "OFF/Standby" ;
VAL_ 384 AccMainMod 1 "ON" 0 "OFF" ;
VAL_ 384 AebWarnCmdFcm 7 "Reserved" 6 "Reserved" 5 "Reserved" 4 "Stop Request" 3 "Full Brake Active" 2 "Partial Brake Active	" 1 "Prefill Active" 0 "Not Active" ;
VAL_ 384 FcwAebFailInfoFcm 3 "Service Required" 2 "Temp. Not Available By Radar	" 1 "Temp. Not Available By Camera" 0 "Normal State" ;
VAL_ 384 FcwAebOnOffState 3 "ON (FCW)" 2 "Not Present" 1 "ON(FCW/AEB)" 0 "Off" ;
